VERSION ""

NS_ :

BS_:

BU_: FUSION IVI HMI Telltale

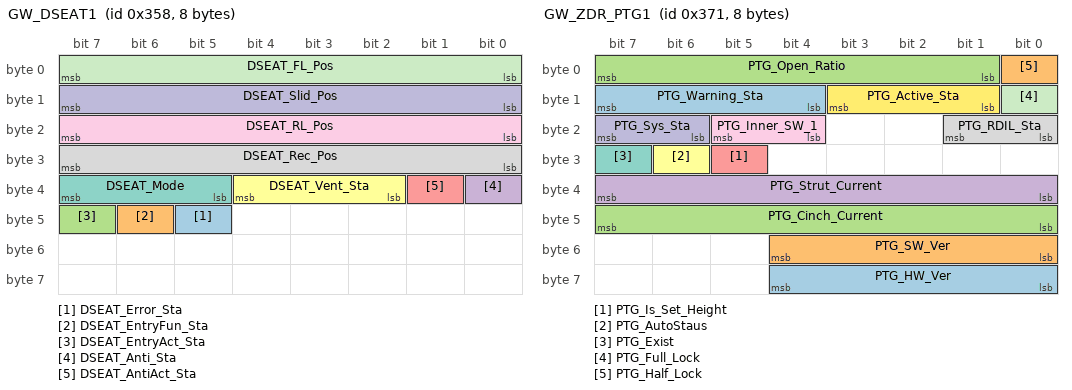
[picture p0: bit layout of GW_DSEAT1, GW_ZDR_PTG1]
BO_ 856 GW_DSEAT1: 8 FUSION
 SG_ DSEAT_Error_Sta : 45|1@0+ (1,0) [0|1] "" IVI
 SG_ DSEAT_EntryFun_Sta : 46|1@0+ (1,0) [0|1] "" IVI
 SG_ DSEAT_EntryAct_Sta : 47|1@0+ (1,0) [0|1] "" Vector__XXX
 SG_ DSEAT_Anti_Sta : 32|1@0+ (1,0) [0|1] "" IVI
 SG_ DSEAT_AntiAct_Sta : 33|1@0+ (1,0) [0|1] "" Vector__XXX
 SG_ DSEAT_Vent_Sta : 36|3@0+ (1,0) [0|4] "" IVI
 SG_ DSEAT_Mode : 39|3@0+ (1,0) [0|7] "" Vector__XXX
 SG_ DSEAT_Rec_Pos : 31|8@0+ (1,0) [0|80] "deg" Vector__XXX
 SG_ DSEAT_RL_Pos : 23|8@0+ (1,0) [0|60] "mm" Vector__XXX
 SG_ DSEAT_Slid_Pos : 15|8@0+ (1,0) [0|240] "mm" Vector__XXX
 SG_ DSEAT_FL_Pos : 7|8@0+ (1,0) [0|25] "mm" Vector__XXX

BO_ 881 GW_ZDR_PTG1: 8 FUSION
 SG_ PTG_HW_Ver : 60|5@0+ (1,0) [0|31] "" IVI
 SG_ PTG_SW_Ver : 52|5@0+ (1,0) [0|31] "" IVI
 SG_ PTG_Cinch_Current : 47|8@0+ (0.1,0) [0|25.5] "A" Vector__XXX
 SG_ PTG_Strut_Current : 39|8@0+ (0.1,0) [0|25.5] "A" Vector__XXX
 SG_ PTG_Is_Set_Height : 29|1@0+ (1,0) [0|1] "" IVI
 SG_ PTG_AutoStaus : 30|1@0+ (1,0) [0|1] "" IVI
 SG_ PTG_Exist : 31|1@0+ (1,0) [0|1] "" IVI
 SG_ PTG_RDIL_Sta : 17|2@0+ (1,0) [0|3] "" Vector__XXX
 SG_ PTG_Inner_SW_1 : 21|2@0+ (1,0) [0|3] "" Vector__XXX
 SG_ PTG_Sys_Sta : 23|2@0+ (1,0) [0|3] "" IVI
 SG_ PTG_Full_Lock : 8|1@0+ (1,0) [0|1] "" Vector__XXX
 SG_ PTG_Active_Sta : 11|3@0+ (1,0) [0|7] "" IVI
 SG_ PTG_Warning_Sta : 15|4@0+ (1,0) [0|15] "" Vector__XXX
 SG_ PTG_Half_Lock : 0|1@0+ (1,0) [0|1] "" Vector__XXX
 SG_ PTG_Open_Ratio : 7|7@0+ (1,0) [0|127] "" Vector__XXX

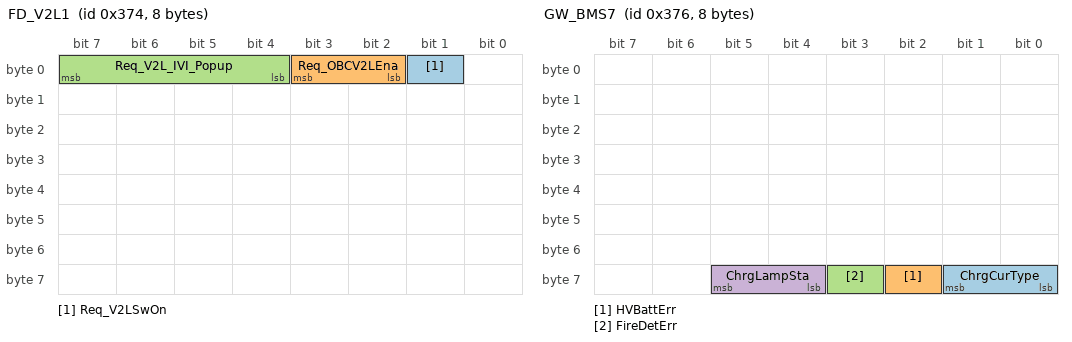
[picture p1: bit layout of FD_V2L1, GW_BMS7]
BO_ 884 FD_V2L1: 8 FUSION
 SG_ Req_V2LSwOn : 1|1@0+ (1,0) [0|1] "" IVI
 SG_ Req_OBCV2LEna : 3|2@0+ (1,0) [0|2] "" Vector__XXX
 SG_ Req_V2L_IVI_Popup : 7|4@0+ (1,0) [0|6] "" IVI

BO_ 886 GW_BMS7: 8 FUSION
 SG_ ChrgCurType : 57|2@0+ (1,0) [0|3] "" Vector__XXX
 SG_ HVBattErr : 58|1@0+ (1,0) [0|1] "" IVI,Telltale
 SG_ FireDetErr : 59|1@0+ (1,0) [0|1] "" IVI
 SG_ ChrgLampSta : 61|2@0+ (1,0) [0|3] "" Vector__XXX

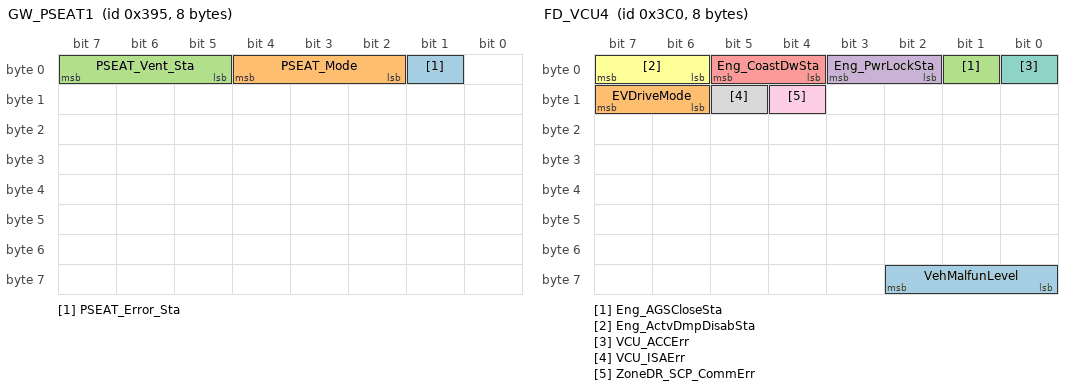
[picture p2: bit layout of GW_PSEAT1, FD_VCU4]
BO_ 917 GW_PSEAT1: 8 FUSION
 SG_ PSEAT_Error_Sta : 1|1@0+ (1,0) [0|1] "" IVI
 SG_ PSEAT_Mode : 4|3@0+ (1,0) [0|7] "" IVI
 SG_ PSEAT_Vent_Sta : 7|3@0+ (1,0) [0|4] "" IVI

BO_ 921 GW_MCU_F3: 8 FUSION
 SG_ Fr_MCU_SW_Ver : 55|16@0+ (1,0) [0|65535] "" IVI
 SG_ Fr_MCU_HW_Ver : 39|16@0+ (1,0) [0|65535] "" IVI

BO_ 925 GW_MCU_R3: 8 FUSION
 SG_ Rr_MCU3_SW_Ver : 55|16@0+ (1,0) [0|65535] "" IVI
 SG_ Rr_MCU3_HW_Ver : 39|16@0+ (1,0) [0|65535] "" IVI

BO_ 960 FD_VCU4: 8 FUSION
 SG_ VehMalfunLevel : 58|3@0+ (1,0) [0|5] "" IVI
 SG_ EVDriveMode : 15|2@0+ (1,0) [0|2] "" IVI
 SG_ Eng_AGSCloseSta : 1|1@0+ (1,0) [0|1] "" IVI
 SG_ Eng_PwrLockSta : 3|2@0+ (1,0) [0|2] "" IVI
 SG_ Eng_CoastDwSta : 5|2@0+ (1,0) [0|2] "" IVI
 SG_ Eng_ActvDmpDisabSta : 7|2@0+ (1,0) [0|2] "" IVI
 SG_ VCU_ACCErr : 0|1@0+ (1,0) [0|1] "" IVI
 SG_ VCU_ISAErr : 13|1@0+ (1,0) [0|1] "" IVI
 SG_ ZoneDR_SCP_CommErr : 12|1@0+ (1,0) [0|1] "" IVI

BO_ 963 FD_VCU6: 32 FUSION
 SG_ FUSION_SW_SHA8 : 239|8@0+ (1,0) [0|255] "" IVI
 SG_ FUSION_SW_SHA7 : 231|8@0+ (1,0) [0|255] "" IVI
 SG_ FUSION_SW_SHA6 : 223|8@0+ (1,0) [0|255] "" IVI
 SG_ FUSION_SW_SHA5 : 215|8@0+ (1,0) [0|255] "" IVI
 SG_ FUSION_SW_SHA4 : 207|8@0+ (1,0) [0|255] "" IVI
 SG_ FUSION_SW_SHA3 : 199|8@0+ (1,0) [0|255] "" IVI
 SG_ FUSION_SW_SHA2 : 191|8@0+ (1,0) [0|255] "" IVI
 SG_ FUSION_SW_SHA1 : 183|8@0+ (1,0) [0|255] "" IVI
 SG_ FUSION_SW_dash2 : 175|8@0+ (1,0) [0|255] "" IVI
 SG_ FUSION_SW_change2 : 167|8@0+ (1,0) [0|255] "" IVI
 SG_ FUSION_SW_change1 : 159|8@0+ (1,0) [0|255] "" IVI
 SG_ FUSION_SW_dash1 : 151|8@0+ (1,0) [0|255] "" IVI
 SG_ FUSION_HW_Ver1 : 143|8@0+ (1,0) [0|255] "" IVI
 SG_ FUSION_HW_Ver2 : 135|8@0+ (1,0) [0|255] "" IVI
 SG_ FUSION_HW_Ver3 : 127|8@0+ (1,0) [0|255] "" IVI
 SG_ FUSION_SW_CarModel1 : 119|8@0+ (1,0) [0|255] "" IVI
 SG_ FUSION_SW_CarModel2 : 111|8@0+ (1,0) [0|255] "" IVI
 SG_ FUSION_SW_CarModel3 : 103|8@0+ (1,0) [0|255] "" IVI
 SG_ FUSION_SW_Controller1 : 95|8@0+ (1,0) [0|255] "" IVI
 SG_ FUSION_SW_Controller2 : 87|8@0+ (1,0) [0|255] "" IVI
 SG_ FUSION_SW_Major1 : 79|8@0+ (1,0) [0|255] "" IVI
 SG_ FUSION_SW_Major2 : 71|8@0+ (1,0) [0|255] "" IVI
 SG_ FUSION_SW_Minor1 : 63|8@0+ (1,0) [0|255] "" IVI
 SG_ FUSION_SW_Minor2 : 55|8@0+ (1,0) [0|255] "" IVI
 SG_ FUSION_SW_Patch1 : 47|8@0+ (1,0) [0|255] "" IVI
 SG_ FUSION_SW_Patch2 : 39|8@0+ (1,0) [0|255] "" IVI
 SG_ FUSION_SW_Country1 : 31|8@0+ (1,0) [0|255] "" IVI
 SG_ FUSION_SW_Country2 : 23|8@0+ (1,0) [0|255] "" IVI
 SG_ FUSION_SW_Var : 15|8@0+ (1,0) [0|255] "" IVI

BO_ 965 GW_ZoneDR5: 32 FUSION
 SG_ ZONE_DR_SW_SHA8 : 239|8@0+ (1,0) [0|255] "" IVI
 SG_ ZONE_DR_SW_SHA7 : 231|8@0+ (1,0) [0|255] "" IVI
 SG_ ZONE_DR_SW_SHA6 : 223|8@0+ (1,0) [0|255] "" IVI
 SG_ ZONE_DR_SW_SHA5 : 215|8@0+ (1,0) [0|255] "" IVI
 SG_ ZONE_DR_SW_SHA4 : 207|8@0+ (1,0) [0|255] "" IVI
 SG_ ZONE_DR_SW_SHA3 : 199|8@0+ (1,0) [0|255] "" IVI
 SG_ ZONE_DR_SW_SHA2 : 191|8@0+ (1,0) [0|255] "" IVI
 SG_ ZONE_DR_SW_SHA1 : 183|8@0+ (1,0) [0|255] "" IVI
 SG_ ZONE_DR_SW_dash2 : 175|8@0+ (1,0) [0|255] "" IVI
 SG_ ZONE_DR_SW_change2 : 167|8@0+ (1,0) [0|255] "" IVI
 SG_ ZONE_DR_SW_change1 : 159|8@0+ (1,0) [0|255] "" IVI
 SG_ ZONE_DR_SW_dash1 : 151|8@0+ (1,0) [0|255] "" IVI
 SG_ ZONE_DR_HW_Ver1 : 143|8@0+ (1,0) [0|255] "" IVI
 SG_ ZONE_DR_HW_Ver2 : 135|8@0+ (1,0) [0|255] "" IVI
 SG_ ZONE_DR_HW_Ver3 : 127|8@0+ (1,0) [0|255] "" IVI
 SG_ ZONE_DR_SW_CarModel1 : 119|8@0+ (1,0) [0|255] "" IVI
 SG_ ZONE_DR_SW_CarModel2 : 111|8@0+ (1,0) [0|255] "" IVI
 SG_ ZONE_DR_SW_CarModel3 : 103|8@0+ (1,0) [0|255] "" IVI
 SG_ ZONE_DR_SW_Controller1 : 95|8@0+ (1,0) [0|255] "" IVI
 SG_ ZONE_DR_SW_Controller2 : 87|8@0+ (1,0) [0|255] "" IVI
 SG_ ZONE_DR_SW_Major1 : 79|8@0+ (1,0) [0|255] "" IVI
 SG_ ZONE_DR_SW_Major2 : 71|8@0+ (1,0) [0|255] "" IVI
 SG_ ZONE_DR_SW_Minor1 : 63|8@0+ (1,0) [0|255] "" IVI
 SG_ ZONE_DR_SW_Minor2 : 55|8@0+ (1,0) [0|255] "" IVI
 SG_ ZONE_DR_SW_Patch1 : 47|8@0+ (1,0) [0|255] "" IVI
 SG_ ZONE_DR_SW_Patch2 : 39|8@0+ (1,0) [0|255] "" IVI
 SG_ ZONE_DR_SW_Country1 : 31|8@0+ (1,0) [0|255] "" IVI
 SG_ ZONE_DR_SW_Country2 : 23|8@0+ (1,0) [0|255] "" IVI
 SG_ ZONE_DR_SW_Var : 15|8@0+ (1,0) [0|255] "" IVI

BO_ 969 GW_ZoneFR5: 32 FUSION
 SG_ ZONE_FR_SW_SHA8 : 239|8@0+ (1,0) [0|255] "" IVI
 SG_ ZONE_FR_SW_SHA7 : 231|8@0+ (1,0) [0|255] "" IVI
 SG_ ZONE_FR_SW_SHA6 : 223|8@0+ (1,0) [0|255] "" IVI
 SG_ ZONE_FR_SW_SHA5 : 215|8@0+ (1,0) [0|255] "" IVI
 SG_ ZONE_FR_SW_SHA4 : 207|8@0+ (1,0) [0|255] "" IVI
 SG_ ZONE_FR_SW_SHA3 : 199|8@0+ (1,0) [0|255] "" IVI
 SG_ ZONE_FR_SW_SHA2 : 191|8@0+ (1,0) [0|255] "" IVI
 SG_ ZONE_FR_SW_SHA1 : 183|8@0+ (1,0) [0|255] "" IVI
 SG_ ZONE_FR_SW_dash2 : 175|8@0+ (1,0) [0|255] "" IVI
 SG_ ZONE_FR_SW_change2 : 167|8@0+ (1,0) [0|255] "" IVI
 SG_ ZONE_FR_SW_change1 : 159|8@0+ (1,0) [0|255] "" IVI
 SG_ ZONE_FR_SW_dash1 : 151|8@0+ (1,0) [0|255] "" IVI
 SG_ ZONE_FR_HW_Ver1 : 143|8@0+ (1,0) [0|255] "" IVI
 SG_ ZONE_FR_HW_Ver2 : 135|8@0+ (1,0) [0|255] "" IVI
 SG_ ZONE_FR_HW_Ver3 : 127|8@0+ (1,0) [0|255] "" IVI
 SG_ ZONE_FR_SW_CarModel1 : 119|8@0+ (1,0) [0|255] "" IVI
 SG_ ZONE_FR_SW_CarModel2 : 111|8@0+ (1,0) [0|255] "" IVI
 SG_ ZONE_FR_SW_CarModel3 : 103|8@0+ (1,0) [0|255] "" IVI
 SG_ ZONE_FR_SW_Controller1 : 95|8@0+ (1,0) [0|255] "" IVI
 SG_ ZONE_FR_SW_Controller2 : 87|8@0+ (1,0) [0|255] "" IVI
 SG_ ZONE_FR_SW_Major1 : 79|8@0+ (1,0) [0|255] "" IVI
 SG_ ZONE_FR_SW_Major2 : 71|8@0+ (1,0) [0|255] "" IVI
 SG_ ZONE_FR_SW_Minor1 : 63|8@0+ (1,0) [0|255] "" IVI
 SG_ ZONE_FR_SW_Minor2 : 55|8@0+ (1,0) [0|255] "" IVI
 SG_ ZONE_FR_SW_Patch1 : 47|8@0+ (1,0) [0|255] "" IVI
 SG_ ZONE_FR_SW_Patch2 : 39|8@0+ (1,0) [0|255] "" IVI
 SG_ ZONE_FR_SW_Country1 : 31|8@0+ (1,0) [0|255] "" IVI
 SG_ ZONE_FR_SW_Country2 : 23|8@0+ (1,0) [0|255] "" IVI
 SG_ ZONE_FR_SW_Var : 15|8@0+ (1,0) [0|255] "" IVI

BO_ 992 GW_BMS4: 48 FUSION
 SG_ HVBCellVoltMax : 375|16@0+ (1,0) [0|65533] "mV" Vector__XXX
 SG_ HVBCellVoltMin : 359|16@0+ (1,0) [0|65533] "mV" Vector__XXX
 SG_ CellTempAvg : 351|8@0+ (1,-40) [-40|213] "Deg^C" Vector__XXX
 SG_ MaxCellVolt_Num : 343|8@0+ (1,0) [0|253] "" Vector__XXX
 SG_ MinCellVolt_Num : 335|8@0+ (1,0) [0|253] "" Vector__XXX
 SG_ MaxCellTemp_Num : 327|8@0+ (1,0) [0|253] "" Vector__XXX
 SG_ MinCellTemp_Num : 319|8@0+ (1,0) [0|253] "" Vector__XXX
 SG_ HVBMTempMax : 311|8@0+ (1,-40) [-40|213] "Deg^C" IVI
 SG_ HVBMTempMin : 303|8@0+ (1,-40) [-40|213] "Deg^C" Vector__XXX
 SG_ Mtemp16 : 159|8@0+ (1,-40) [-40|213] "Deg^C" Vector__XXX
 SG_ Mtemp17 : 151|8@0+ (1,-40) [-40|213] "Deg^C" Vector__XXX
 SG_ Mtemp18 : 143|8@0+ (1,-40) [-40|213] "Deg^C" Vector__XXX
 SG_ Mtemp19 : 135|8@0+ (1,-40) [-40|213] "Deg^C" Vector__XXX
 SG_ Mtemp20 : 127|8@0+ (1,-40) [-40|213] "Deg^C" Vector__XXX
 SG_ Mtemp01 : 119|8@0+ (1,-40) [-40|213] "Deg^C" Vector__XXX
 SG_ Mtemp02 : 111|8@0+ (1,-40) [-40|213] "Deg^C" Vector__XXX
 SG_ Mtemp03 : 103|8@0+ (1,-40) [-40|213] "Deg^C" Vector__XXX
 SG_ Mtemp04 : 95|8@0+ (1,-40) [-40|213] "Deg^C" Vector__XXX
 SG_ Mtemp05 : 87|8@0+ (1,-40) [-40|213] "Deg^C" Vector__XXX
 SG_ Mtemp06 : 79|8@0+ (1,-40) [-40|213] "Deg^C" Vector__XXX
 SG_ Mtemp07 : 71|8@0+ (1,-40) [-40|213] "Deg^C" Vector__XXX
 SG_ Mtemp08 : 63|8@0+ (1,-40) [-40|213] "Deg^C" Vector__XXX
 SG_ Mtemp09 : 55|8@0+ (1,-40) [-40|213] "Deg^C" Vector__XXX
 SG_ Mtemp10 : 47|8@0+ (1,-40) [-40|213] "Deg^C" Vector__XXX
 SG_ Mtemp11 : 39|8@0+ (1,-40) [-40|213] "Deg^C" Vector__XXX
 SG_ Mtemp12 : 31|8@0+ (1,-40) [-40|213] "Deg^C" Vector__XXX
 SG_ Mtemp13 : 23|8@0+ (1,-40) [-40|213] "Deg^C" Vector__XXX
 SG_ Mtemp14 : 15|8@0+ (1,-40) [-40|213] "Deg^C" Vector__XXX
 SG_ Mtemp15 : 7|8@0+ (1,-40) [-40|213] "Deg^C" Vector__XXX

BO_ 997 GW_PSEAT3: 8 FUSION
 SG_ PSEAT_HW_Ver : 23|16@0+ (1,0) [0|65535] "" IVI
 SG_ PSEAT_SW_Ver : 7|16@0+ (1,0) [0|65535] "" IVI

BO_ 1016 GW_DSEAT3: 8 FUSION
 SG_ DSEAT_HW_Ver : 23|16@0+ (1,0) [0|65535] "" IVI
 SG_ DSEAT_SW_Ver : 7|16@0+ (1,0) [0|65535] "" IVI

BO_ 1077 FD_TPMS1: 20 FUSION
 SG_ LRWheelPSW : 159|8@0+ (1,0) [0|200] "" IVI
 SG_ LFWheelPSW : 151|8@0+ (1,0) [0|200] "" IVI
 SG_ RFWheelPSW : 143|8@0+ (1,0) [0|200] "" IVI
 SG_ RRWheelPSW : 135|8@0+ (1,0) [0|200] "" IVI
 SG_ RFPressIndi : 121|2@0+ (1,0) [0|3] "" IVI
 SG_ LFPressIndi : 123|2@0+ (1,0) [0|3] "" IVI
 SG_ RRPressIndi : 125|2@0+ (1,0) [0|3] "" IVI
 SG_ LRPressIndi : 127|2@0+ (1,0) [0|3] "" IVI
 SG_ RFWheelTmpIndi : 112|1@0+ (1,0) [0|1] "" IVI
 SG_ LFWheelTmpIndi : 113|1@0+ (1,0) [0|1] "" IVI
 SG_ RRWheelTmpIndi : 114|1@0+ (1,0) [0|1] "" IVI
 SG_ LRWheelTmpIndi : 115|1@0+ (1,0) [0|1] "" IVI
 SG_ RFSensorFail : 116|1@0+ (1,0) [0|1] "" IVI
 SG_ LFSensorFail : 117|1@0+ (1,0) [0|1] "" IVI
 SG_ RRSensorFail : 118|1@0+ (1,0) [0|1] "" IVI
 SG_ LRSensorFail : 119|1@0+ (1,0) [0|1] "" IVI
 SG_ RFBatWarn : 104|1@0+ (1,0) [0|1] "" IVI
 SG_ LFBatWarn : 105|1@0+ (1,0) [0|1] "" IVI
 SG_ RRBatWarn : 106|1@0+ (1,0) [0|1] "" IVI
 SG_ LRBatWarn : 107|1@0+ (1,0) [0|1] "" IVI
 SG_ RFWheelDebug : 108|1@0+ (1,0) [0|1] "" IVI
 SG_ LFWheelDebug : 109|1@0+ (1,0) [0|1] "" IVI
 SG_ RRWheelDebug : 110|1@0+ (1,0) [0|1] "" IVI
 SG_ LRWheelDebug : 111|1@0+ (1,0) [0|1] "" IVI
 SG_ RFWheelPress : 103|8@0+ (1,0) [0|250] "" IVI
 SG_ LFWheelPress : 95|8@0+ (1,0) [0|250] "" IVI
 SG_ RRWheelPress : 87|8@0+ (1,0) [0|250] "" IVI
 SG_ LRWheelPress : 79|8@0+ (1,0) [0|250] "" IVI
 SG_ RFWheelTemp : 71|8@0+ (1,-40) [-40|215] "Deg^C" IVI
 SG_ LFWheelTemp : 63|8@0+ (1,-40) [-40|215] "Deg^C" IVI
 SG_ RRWheelTemp : 55|8@0+ (1,-40) [-40|215] "Deg^C" IVI
 SG_ LRWheelTemp : 47|8@0+ (1,-40) [-40|215] "Deg^C" IVI
 SG_ AutoLTips : 25|2@0+ (1,0) [0|3] "" IVI
 SG_ CWheelTips : 34|2@0+ (1,0) [0|3] "" IVI
 SG_ TPMS_Cali_Butt_Allow : 35|1@0+ (1,0) [0|1] "" IVI
 SG_ TPMS_Res_Butt_Allow : 37|1@0+ (1,0) [0|1] "" IVI
 SG_ TPMSWarnIndi : 39|2@0+ (1,0) [0|3] "" IVI
 SG_ RRSensorMode : 12|1@0+ (1,0) [0|1] "" Vector__XXX
 SG_ LRSensorMode : 13|1@0+ (1,0) [0|1] "" Vector__XXX
 SG_ RFSensorMode : 14|1@0+ (1,0) [0|1] "" Vector__XXX
 SG_ LFSensorMode : 15|1@0+ (1,0) [0|1] "" Vector__XXX

BO_ 1078 FD_TPMS2: 32 FUSION
 SG_ ID1_ALTU : 215|32@0+ (1,0) [0|4.294967296E9] "-" Vector__XXX
 SG_ ID2_ALTU : 183|32@0+ (1,0) [0|4.294967296E9] "-" Vector__XXX
 SG_ ID3_ALTU : 151|32@0+ (1,0) [0|4.294967296E9] "-" Vector__XXX
 SG_ ID4_ALTU : 119|32@0+ (1,0) [0|4.294967296E9] "-" Vector__XXX
 SG_ IDin_ALTU : 87|32@0+ (1,0) [0|4.294967296E9] "-" Vector__XXX
 SG_ ID1_Loc_ALTU : 74|3@0+ (1,0) [0|5] "-" Vector__XXX
 SG_ ID2_Loc_ALTU : 77|3@0+ (1,0) [0|5] "-" Vector__XXX
 SG_ ID3_Loc_ALTU : 66|3@0+ (1,0) [0|5] "-" Vector__XXX
 SG_ ID4_Loc_ALTU : 69|3@0+ (1,0) [0|5] "-" Vector__XXX
 SG_ RF_FAT_ALTU : 70|1@0+ (1,0) [0|1] "-" Vector__XXX
 SG_ ID1_message_ALTU : 63|8@0+ (1,0) [0|255] "-" Vector__XXX
 SG_ ID2_message_ALTU : 55|8@0+ (1,0) [0|255] "-" Vector__XXX
 SG_ ID3_message_ALTU : 47|8@0+ (1,0) [0|255] "-" Vector__XXX
 SG_ ID4_message_ALTU : 39|8@0+ (1,0) [0|255] "-" Vector__XXX
 SG_ S1WheelDebug_ALTU : 31|8@0+ (0.5,0) [0|100] "%" Vector__XXX
 SG_ S2WheelDebug_ALTU : 23|8@0+ (0.5,0) [0|100] "%" Vector__XXX
 SG_ S3WheelDebug_ALTU : 15|8@0+ (0.5,0) [0|100] "%" Vector__XXX
 SG_ S4WheelDebug_ALTU : 7|8@0+ (0.5,0) [0|100] "%" Vector__XXX

BO_ 1080 FD_OTA1: 12 FUSION
 SG_ OTA_Up_Backcount : 55|8@0+ (1,0) [0|122] "" IVI
 SG_ OTA_DL_Speed : 27|20@0+ (1,0) [0|1048575] "Kb/s" IVI
 SG_ OTA_Lock_Req : 31|1@0+ (1,0) [0|1] "" Vector__XXX
 SG_ OTA_Updating_ECU : 20|5@0+ (1,0) [0|30] "" Vector__XXX
 SG_ OTA_Update_Available : 21|1@0+ (1,0) [0|1] "" IVI
 SG_ OTA_InVehicle_FW : 23|2@0+ (1,0) [0|2] "" IVI
 SG_ OTA_DL_Available : 8|1@0+ (1,0) [0|1] "" IVI
 SG_ OTA_Mode : 9|1@0+ (1,0) [0|1] "" IVI
 SG_ OTA_Network_Type : 11|2@0+ (1,0) [0|3] "" IVI
 SG_ OTA_MDA_Status : 15|4@0+ (1,0) [0|14] "" IVI
 SG_ OTA_Progress_Rate : 7|8@0+ (1,0) [0|102] "" IVI
 SG_ OTA_Permit_Agreed : 63|1@0+ (1,0) [0|1] "" IVI
 SG_ OTA_Remained_Time : 58|11@0+ (10,0) [0|10800] "SECOND" IVI
 SG_ OTA_Debug_Code : 79|8@0+ (1,0) [0|65] "" IVI
 SG_ OTA_TBOXResetReq : 30|1@0+ (1,0) [0|1] "" Vector__XXX
 SG_ OTA_Updating_ECU_8bit : 95|8@0+ (1,0) [0|255] "" IVI

BO_ 1090 GW_TBOX1: 12 FUSION
 SG_ PowerOff_T_Set : 70|7@0+ (1,1) [1|100] "" Vector__XXX
 SG_ Re_Radio : 60|1@0+ (1,0) [0|1] "" IVI
 SG_ TBOX_NET_SIG_STR : 55|4@0+ (1,0) [0|8] "" IVI
 SG_ TBOX_TEST_STATUS : 51|4@0+ (1,0) [0|15] "" IVI
 SG_ ReOutsideMirror : 43|2@0+ (1,0) [0|3] "" Vector__XXX
 SG_ CbnPreReq : 45|2@0+ (1,0) [0|3] "" Vector__XXX
 SG_ CbnPreACEnaReq : 47|2@0+ (1,0) [0|3] "" IVI
 SG_ CbnPreTarT : 37|6@0+ (0.5,17) [17|32] "" Vector__XXX
 SG_ Uncounting_Req : 39|2@0+ (1,0) [0|3] "" Vector__XXX
 SG_ TBOX_Remote_PW : 28|5@0+ (1,0) [0|16] "" Vector__XXX
 SG_ Re_PwrReqTbox : 31|3@0+ (1,0) [0|6] "" Vector__XXX
 SG_ TBOX_RemoteOn : 17|2@0+ (1,0) [0|3] "" Vector__XXX
 SG_ TBOX_Re_VehData : 19|2@0+ (1,0) [0|3] "" Vector__XXX
 SG_ Antitheft_Zero : 23|4@0+ (1,0) [0|15] "" Vector__XXX
 SG_ Re_DoorLock : 7|16@0+ (1,0) [0|65535] "" Vector__XXX
 SG_ TBOX_Re_DTCData : 41|2@0+ (1,0) [0|3] "" Vector__XXX
 SG_ Remote_ACTemp : 77|6@0+ (0.5,17) [17|32] "Deg^C" Vector__XXX
 SG_ Remote_AutoReq : 79|1@0+ (1,0) [0|1] "" Vector__XXX
 SG_ Remote_MidAutoReq : 78|1@0+ (1,0) [0|1] "" Vector__XXX

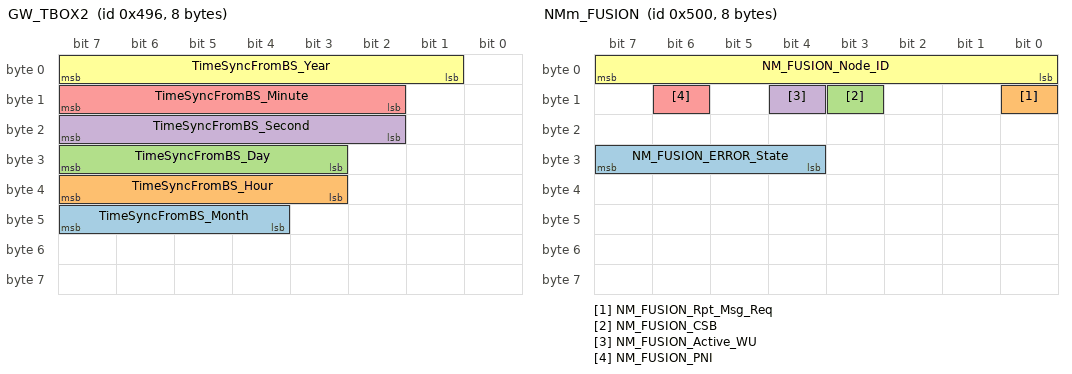
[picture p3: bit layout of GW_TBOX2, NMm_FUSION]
BO_ 1174 GW_TBOX2: 8 FUSION
 SG_ TimeSyncFromBS_Month : 47|4@0+ (1,0) [0|12] "MONTH" IVI
 SG_ TimeSyncFromBS_Hour : 39|5@0+ (1,0) [0|23] "HOUR" IVI
 SG_ TimeSyncFromBS_Day : 31|5@0+ (1,0) [0|31] "DAY" IVI
 SG_ TimeSyncFromBS_Second : 23|6@0+ (1,0) [0|59] "SECOND" IVI
 SG_ TimeSyncFromBS_Minute : 15|6@0+ (1,0) [0|59] "MINUTE" IVI
 SG_ TimeSyncFromBS_Year : 7|7@0+ (1,2000) [2000|2099] "YEAR" IVI

BO_ 1249 GW_TBOX3: 48 FUSION
 SG_ TBOX_SW_VER : 279|32@0+ (1,0) [0|4.294967295E9] "" IVI
 SG_ TBOX_HW_VER : 231|32@0+ (1,0) [0|4.294967295E9] "" IVI
 SG_ ReserveChargeOn_Minute : 221|6@0+ (1,0) [0|59] "MINUTE" Vector__XXX
 SG_ ReserveChargeOn_Hour : 210|5@0+ (1,0) [0|23] "HOUR" Vector__XXX
 SG_ ReserveChargeOn_Day : 215|5@0+ (1,0) [0|31] "DAY" Vector__XXX
 SG_ ReserveChargeOn_Month : 203|4@0+ (1,0) [0|12] "MONTH" Vector__XXX
 SG_ ReserveChargeOn_Year : 194|7@0+ (1,2000) [2000|2099] "YEAR" Vector__XXX
 SG_ ReserveChargeOFF_Minute : 189|6@0+ (1,0) [0|59] "MINUTE" Vector__XXX
 SG_ ReserveChargeOFF_Hour : 178|5@0+ (1,0) [0|23] "HOUR" Vector__XXX
 SG_ ReserveChargeOFF_Day : 183|5@0+ (1,0) [0|31] "DAY" Vector__XXX
 SG_ ReserveChargeOFF_Month : 171|4@0+ (1,0) [0|12] "MONTH" Vector__XXX
 SG_ ReserveChargeOFF_Year : 162|7@0+ (1,2000) [2000|2099] "YEAR" Vector__XXX
 SG_ Charge_Percent_Set : 159|8@0+ (1,0) [0|100] "%" IVI

BO_ 1280 NMm_FUSION: 8 FUSION
 SG_ NM_FUSION_ERROR_State : 31|4@0+ (1,0) [0|8] "" IVI,HMI,Telltale
 SG_ NM_FUSION_Rpt_Msg_Req : 8|1@0+ (1,0) [0|1] "" IVI,HMI,Telltale
 SG_ NM_FUSION_CSB : 11|1@0+ (1,0) [0|1] "" IVI,HMI,Telltale
 SG_ NM_FUSION_Active_WU : 12|1@0+ (1,0) [0|1] "" IVI,HMI,Telltale
 SG_ NM_FUSION_PNI : 14|1@0+ (1,0) [0|1] "" IVI,HMI,Telltale
 SG_ NM_FUSION_Node_ID : 7|8@0+ (1,0) [0|127] "" IVI,HMI,Telltale

BO_ 1666 DiagPhysReqToTelltale: 8 FUSION
 SG_ DiagPhysReqToTelltale : 7|64@0+ (1,0) [0|0] "" Telltale

BO_ 1696 DiagPhysReqToIVI: 8 FUSION
 SG_ DiagPhysReqToIVI : 7|64@0+ (1,0) [0|0] "" IVI

BO_ 1714 DiagPhysReqToHMI: 8 FUSION
 SG_ DiagPhysReqToHMI : 7|64@0+ (1,0) [0|0] "" HMI

BO_ 2000 DiagFuncReqFT: 8 FUSION
 SG_ DiagFuncReqFT : 7|64@0+ (1,0) [0|0] "" IVI,HMI,Telltale

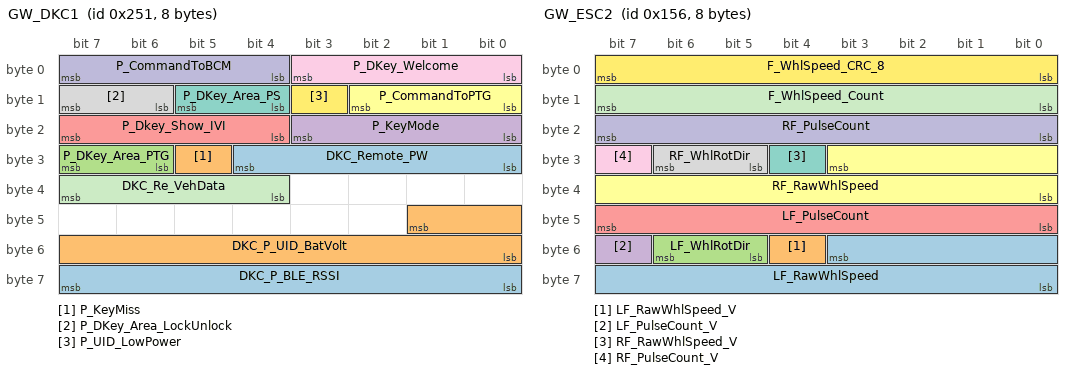
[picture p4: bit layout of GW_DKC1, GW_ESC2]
BO_ 593 GW_DKC1: 8 FUSION
 SG_ DKC_Remote_PW : 28|5@0+ (1,0) [0|16] "" Vector__XXX
 SG_ P_KeyMiss : 29|1@0+ (1,0) [0|1] "" IVI
 SG_ P_DKey_Area_PTG : 31|2@0+ (1,0) [0|3] "" Vector__XXX
 SG_ P_KeyMode : 19|4@0+ (1,0) [0|15] "" Vector__XXX
 SG_ P_Dkey_Show_IVI : 23|4@0+ (1,0) [0|15] "" IVI
 SG_ P_CommandToPTG : 10|3@0+ (1,0) [0|5] "" Vector__XXX
 SG_ P_DKey_Area_PS : 13|2@0+ (1,0) [0|3] "" Vector__XXX
 SG_ P_DKey_Area_LockUnlock : 15|2@0+ (1,0) [0|3] "" Vector__XXX
 SG_ P_DKey_Welcome : 3|4@0+ (1,0) [0|15] "" Vector__XXX
 SG_ P_CommandToBCM : 7|4@0+ (1,0) [0|15] "" Vector__XXX
 SG_ DKC_Re_VehData : 39|4@0+ (1,0) [0|15] "" Vector__XXX
 SG_ P_UID_LowPower : 11|1@0+ (1,0) [0|1] "" IVI
 SG_ DKC_P_BLE_RSSI : 63|8@0+ (1,0) [0|255] "" Vector__XXX
 SG_ DKC_P_UID_BatVolt : 41|10@0+ (10,0) [0|3500] "mV" Vector__XXX

BO_ 342 GW_ESC2: 8 FUSION
 SG_ LF_RawWhlSpeed : 51|12@0+ (0.0625,0) [0|255.9375] "km/h" Vector__XXX
 SG_ LF_RawWhlSpeed_V : 52|1@0+ (1,0) [0|1] "" Vector__XXX
 SG_ LF_WhlRotDir : 54|2@0+ (1,0) [0|3] "" IVI
 SG_ LF_PulseCount_V : 55|1@0+ (1,0) [0|1] "" IVI
 SG_ LF_PulseCount : 47|8@0+ (1,0) [0|255] "" IVI
 SG_ RF_RawWhlSpeed : 27|12@0+ (0.0625,0) [0|255.9375] "km/h" Vector__XXX
 SG_ RF_RawWhlSpeed_V : 28|1@0+ (1,0) [0|1] "" Vector__XXX
 SG_ RF_WhlRotDir : 30|2@0+ (1,0) [0|3] "" IVI
 SG_ RF_PulseCount_V : 31|1@0+ (1,0) [0|1] "" IVI
 SG_ RF_PulseCount : 23|8@0+ (1,0) [0|255] "" IVI
 SG_ F_WhlSpeed_Count : 15|8@0+ (1,0) [0|255] "" IVI
 SG_ F_WhlSpeed_CRC_8 : 7|8@0+ (1,0) [0|255] "" IVI

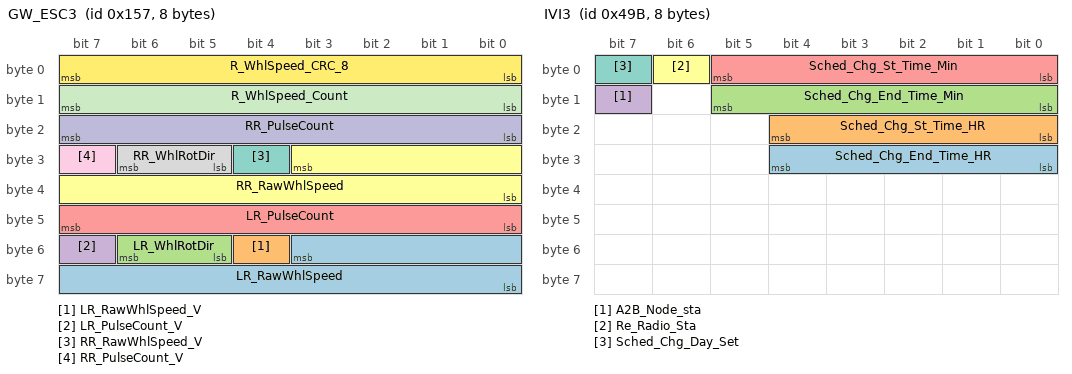
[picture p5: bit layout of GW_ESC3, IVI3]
BO_ 343 GW_ESC3: 8 FUSION
 SG_ LR_RawWhlSpeed : 51|12@0+ (0.0625,0) [0|255.9375] "km/h" Vector__XXX
 SG_ LR_RawWhlSpeed_V : 52|1@0+ (1,0) [0|1] "" Vector__XXX
 SG_ LR_WhlRotDir : 54|2@0+ (1,0) [0|3] "" IVI
 SG_ LR_PulseCount_V : 55|1@0+ (1,0) [0|1] "" IVI
 SG_ LR_PulseCount : 47|8@0+ (1,0) [0|255] "" IVI
 SG_ RR_RawWhlSpeed : 27|12@0+ (0.0625,0) [0|255.9375] "km/h" Vector__XXX
 SG_ RR_RawWhlSpeed_V : 28|1@0+ (1,0) [0|1] "" Vector__XXX
 SG_ RR_WhlRotDir : 30|2@0+ (1,0) [0|3] "" IVI
 SG_ RR_PulseCount_V : 31|1@0+ (1,0) [0|1] "" IVI
 SG_ RR_PulseCount : 23|8@0+ (1,0) [0|255] "" IVI
 SG_ R_WhlSpeed_Count : 15|8@0+ (1,0) [0|255] "" IVI
 SG_ R_WhlSpeed_CRC_8 : 7|8@0+ (1,0) [0|255] "" IVI

BO_ 602 METER1: 24 IVI
 SG_ ODOMETER : 175|24@0+ (0.1,0) [0|999999.9] "KM" FUSION
 SG_ Trip_A : 151|24@0+ (0.1,0) [0|99999.9] "KM" FUSION
 SG_ Trip_B : 127|24@0+ (0.1,0) [0|99999.9] "KM" FUSION
 SG_ ParkBrake : 112|1@0+ (1,0) [0|1] "" FUSION
 SG_ Charge : 113|1@0+ (1,0) [0|1] "" FUSION
 SG_ LEDlitWarnReq : 114|1@0+ (1,0) [0|1] "" FUSION
 SG_ Spd_Crl_Sta : 115|1@0+ (1,0) [0|1] "" FUSION
 SG_ Spd_Crl_Mode : 118|3@0+ (1,0) [0|7] "" FUSION
 SG_ AvailableTrip : 103|16@0+ (0.1,0) [0|999.9] "KM" FUSION
 SG_ APCforDTE : 87|16@0+ (0.1,-999.9) [-999.9|999.9] "Wh/km" FUSION
 SG_ AVGPwrConsumption : 71|16@0+ (0.1,-999.9) [-999.9|999.9] "Wh/km" FUSION
 SG_ Averaged_vehspeed : 49|10@0+ (1,0) [0|300] "km/h" FUSION
 SG_ METER_MPH_Real : 35|12@0+ (0.077675,0) [0|160.0105] "mph" FUSION
 SG_ METER_KPH_Real : 31|12@0+ (0.125,0) [0|255.875] "km/h" FUSION
 SG_ METER_MPH_Calcu : 23|8@0+ (1,0) [0|160] "mph" FUSION
 SG_ METER_KPH_Calcu : 15|8@0+ (1,0) [0|254] "km/h" FUSION

BO_ 1168 IVI1: 8 IVI
 SG_ DRAmbLightBrightnessSet : 46|7@0+ (1,0) [0|100] "%" FUSION
 SG_ AmbLightUserSet : 34|3@0+ (1,0) [0|6] "" FUSION
 SG_ IPAmbLightBrightnessSet : 30|7@0+ (1,0) [0|100] "%" FUSION
 SG_ Sched_OTA_wake : 31|1@0+ (1,0) [0|1] "" FUSION
 SG_ AmbLightColorSet : 21|6@0+ (1,0) [0|63] "" FUSION
 SG_ Upd_Countdown_Cancel : 22|1@0+ (1,0) [0|1] "" FUSION
 SG_ Upd_Countdown_Skip : 23|1@0+ (1,0) [0|1] "" FUSION
 SG_ LINKtoDrive : 8|1@0+ (1,0) [0|1] "" FUSION
 SG_ OTA_CompNTFY_Pres : 9|1@0+ (1,0) [0|1] "" FUSION
 SG_ OTA_CancelDL_Req : 10|1@0+ (1,0) [0|1] "" FUSION
 SG_ IVI_OTA_Upd_Sta : 12|2@0+ (1,0) [0|3] "" FUSION
 SG_ OTA_UpdStart_Req : 13|1@0+ (1,0) [0|1] "" FUSION
 SG_ OTA_SuspendDL_Req : 14|1@0+ (1,0) [0|1] "" FUSION
 SG_ OTA_DL_Req : 15|1@0+ (1,0) [0|1] "" FUSION
 SG_ FCP_FrEvt_BtnSyncReq : 0|1@0+ (1,0) [0|1] "" FUSION
 SG_ FCP_MidEvt_BtnAutoReq : 1|1@0+ (1,0) [0|1] "" FUSION
 SG_ FCP_FrEvt_BtnAutoReq : 2|1@0+ (1,0) [0|1] "" FUSION
 SG_ FCP_FrEvt_BtnACReq : 3|1@0+ (1,0) [0|1] "" FUSION
 SG_ FCP_FrEvt_BtnACMaxReq : 4|1@0+ (1,0) [0|1] "" FUSION
 SG_ VehACModReq : 7|3@0+ (1,0) [0|7] "" FUSION
 SG_ PW_CONTINUE_USE : 39|1@0+ (1,0) [0|1] "" FUSION
 SG_ PW_CLOSE_IMD : 38|1@0+ (1,0) [0|1] "" FUSION
 SG_ SmartEco_Mode_SW : 47|1@0+ (1,0) [0|1] "" FUSION
 SG_ BrkAbn_GoReady_SW : 37|1@0+ (1,0) [0|1] "" FUSION
 SG_ OpenDrOpenWdo_SW : 36|1@0+ (1,0) [0|1] "" FUSION
 SG_ IVI_Lock_SoundSW_Sta : 35|1@0+ (1,0) [0|1] "" FUSION

BO_ 1173 IVI2: 64 IVI
 SG_ AVM_parking_cancel : 505|2@0+ (1,0) [0|3] "" FUSION
 SG_ AVM_parking_excute : 507|2@0+ (1,0) [0|3] "" FUSION
 SG_ AVM_OFF_Rec_Butt : 508|1@0+ (1,0) [0|1] "" FUSION
 SG_ IVI_AGSCloseSW : 511|2@0+ (1,0) [0|3] "" FUSION
 SG_ IVI_LVChrgFuncSW : 497|2@0+ (1,0) [0|3] "" FUSION
 SG_ IVI_PwrLockSW : 499|2@0+ (1,0) [0|3] "" FUSION
 SG_ IVI_CoastDwSW : 501|2@0+ (1,0) [0|3] "" FUSION
 SG_ IVI_ActvDmpDisabSW : 503|2@0+ (1,0) [0|3] "" FUSION
 SG_ Roll_Mode_SW_Cmd : 473|2@0+ (1,0) [0|3] "" FUSION
 SG_ TCS_SW_Cmd : 475|2@0+ (1,0) [0|3] "" FUSION
 SG_ SLIF_BUTT : 477|2@0+ (1,0) [0|2] "" FUSION
 SG_ Roll_Eng_Mode : 478|1@0+ (1,0) [0|1] "" FUSION
 SG_ SOC_Limit_Set : 468|5@0+ (2,50) [50|100] "%" FUSION
 SG_ CDL_Lock_Butt : 469|1@0+ (1,0) [0|1] "" FUSION
 SG_ CDL_Unlock_Butt : 470|1@0+ (1,0) [0|1] "" FUSION
 SG_ SOC_ADJ_BUTT : 471|1@0+ (1,0) [0|1] "" FUSION
 SG_ AC_Chg_Cur_Set : 462|7@0+ (1,5) [5|132] "A" FUSION
 SG_ IVI_ISA_OffsetSpd : 451|4@0+ (1,0) [0|14] "" FUSION
 SG_ RoomLampMode : 455|1@0+ (1,0) [0|1] "" FUSION
 SG_ NAVI_SpeedLimit : 444|5@0+ (1,0) [0|31] "km/h" FUSION
 SG_ NAVI_RoadClass : 447|3@0+ (1,0) [0|7] "" FUSION
 SG_ NAVI_Tollgate : 427|12@0+ (1,0) [0|2000] "m" FUSION
 SG_ NAVI_LinkClass : 431|4@0+ (1,0) [0|15] "" FUSION
 SG_ NAVI_Tunnel : 411|12@0+ (1,0) [0|2000] "m" FUSION
 SG_ NAVI_ForwardLinkLevel : 415|4@0+ (1,0) [0|15] "" FUSION
 SG_ SenstivityPosition : 403|4@0+ (1,0) [0|15] "" FUSION
 SG_ AVM_Parking_mode : 407|4@0+ (1,0) [0|15] "" FUSION
 SG_ Hood_Latch_SW : 393|2@0+ (1,0) [0|3] "" FUSION
 SG_ RCTA_BUTT : 396|2@0+ (1,0) [0|3] "" FUSION
 SG_ IVI_Pwroff_req : 397|1@0+ (1,0) [0|1] "" FUSION
 SG_ IVI_Trigger_req : 398|1@0+ (1,0) [0|1] "" FUSION
 SG_ AVM_Err_STA : 399|1@0+ (1,0) [0|1] "" FUSION
 SG_ NAVI_Distance_info : 375|24@0+ (1,0) [0|1.6777215E7] "m" FUSION
 SG_ IVI_Mute_Sta : 360|1@0+ (1,0) [0|1] "" FUSION
 SG_ IVI_PTG_USSta_SW : 361|1@0+ (1,0) [0|1] "" FUSION
 SG_ IVI_WI_MAIN_SW : 362|1@0+ (1,0) [0|1] "" FUSION
 SG_ IVI_RR_Def_Req : 363|1@0+ (1,0) [0|1] "" FUSION
 SG_ IVI_Night_Mode_Sta : 364|1@0+ (1,0) [0|1] "" FUSION
 SG_ IVI_Status : 365|1@0+ (1,0) [0|1] "" FUSION
 SG_ LVDAMute_BUTT : 367|2@0+ (1,0) [0|3] "" FUSION
 SG_ CAAS_Sw : 353|2@0+ (1,0) [0|3] "" FUSION
 SG_ DSEAT_entryfun_set : 354|1@0+ (1,0) [0|1] "" FUSION
 SG_ DSEAT_anti_set : 355|1@0+ (1,0) [0|1] "" FUSION
 SG_ TPMS_Res_Butt : 357|1@0+ (1,0) [0|1] "" FUSION
 SG_ FollowMeSW : 358|1@0+ (1,0) [0|1] "" FUSION
 SG_ SetUnlockSingle : 359|1@0+ (1,0) [0|1] "" FUSION
 SG_ IVI_PTG_Mode_SW : 345|2@0+ (1,0) [0|3] "" FUSION
 SG_ IVI_PTG_Sta_SW : 347|2@0+ (1,0) [0|3] "" FUSION
 SG_ SLG_Sw : 349|2@0+ (1,0) [0|3] "" FUSION
 SG_ FS_Off_Sw : 351|2@0+ (1,0) [0|3] "" FUSION
 SG_ PSEAT_vent_req : 338|3@0+ (1,0) [0|7] "" FUSION
 SG_ FFogLampSW : 339|1@0+ (1,0) [0|1] "" FUSION
 SG_ DSEAT_vent_req : 342|3@0+ (1,0) [0|7] "" FUSION
 SG_ RFogLampSW : 343|1@0+ (1,0) [0|1] "" FUSION
 SG_ MFRD_N_Bright_Req : 334|7@0+ (1,0) [0|100] "%" FUSION
 SG_ User_p_download : 335|1@0+ (1,0) [0|1] "" FUSION
 SG_ HeadLampSW : 321|2@0+ (1,0) [0|3] "" FUSION
 SG_ NAVI_State : 323|2@0+ (1,0) [0|3] "" FUSION
 SG_ Wifi_Sta_IVI_TBOX : 327|4@0+ (1,0) [0|15] "" FUSION
 SG_ IVI_Panel_Y_Coor : 307|12@0+ (1,0) [0|4095] "" FUSION
 SG_ IVI_Panel_X_Coor : 303|12@0+ (1,0) [0|4095] "" FUSION
 SG_ NAVI_Cam_Dist_info : 295|8@0+ (1,0) [0|255] "m" FUSION
 SG_ OFF_AC_MODE : 282|3@0+ (1,0) [0|7] "" FUSION
 SG_ IVI_PW_Mode_Req : 284|2@0+ (1,0) [0|3] "" FUSION
 SG_ User_p_upload : 285|1@0+ (1,0) [0|1] "" FUSION
 SG_ CameraWrn : 286|1@0+ (1,0) [0|1] "" FUSION
 SG_ Wifi_Reset : 287|1@0+ (1,0) [0|1] "" FUSION
 SG_ NAVI_Direction_STA : 279|8@0+ (1,0) [0|255] "" FUSION
 SG_ IVI_Screen : 269|6@0+ (1,0) [0|62] "" FUSION
 SG_ TurnSwTimeSet : 271|2@0+ (1,0) [0|3] "" FUSION
 SG_ Pressure_unit : 263|8@0+ (1,0) [0|255] "" FUSION
 SG_ Time_system : 255|8@0+ (1,0) [0|255] "" FUSION
 SG_ NAVI_Speed_Limit_A : 241|2@0+ (1,0) [0|3] "" FUSION
 SG_ Temperature_unit : 242|1@0+ (1,0) [0|1] "" FUSION
 SG_ Distance_unit : 243|1@0+ (1,0) [0|1] "" FUSION
 SG_ ESC_SW_Cmd : 245|2@0+ (1,0) [0|3] "" FUSION
 SG_ IVI_Panel_Act : 246|1@0+ (1,0) [0|1] "" FUSION
 SG_ sigHvacRearReq : 247|1@0+ (1,0) [0|1] "" FUSION
 SG_ FCWMute_BUTT : 233|2@0+ (1,0) [0|3] "" FUSION
 SG_ LKA_BUTT : 235|2@0+ (1,0) [0|3] "" FUSION
 SG_ ODAMute_BUTT : 237|2@0+ (1,0) [0|3] "" FUSION
 SG_ LDWMute_BUTT : 239|2@0+ (1,0) [0|3] "" FUSION
 SG_ BSDMute_BUTT : 225|2@0+ (1,0) [0|3] "" FUSION
 SG_ sigWindDirZon3Req : 228|3@0+ (1,0) [0|7] "" FUSION
 SG_ sigAirIntenZon3Req : 219|4@0+ (1,0) [0|15] "" FUSION
 SG_ sigAirIntenZon1Req : 223|4@0+ (1,0) [0|15] "" FUSION
 SG_ AEB_BUTT : 209|2@0+ (1,0) [0|3] "" FUSION
 SG_ sigSetTempZon3Req : 215|6@0+ (0.5,17) [17|32] "Deg^C" FUSION
 SG_ sigSetTempZon2Req : 205|6@0+ (0.5,17) [17|32] "Deg^C" FUSION
 SG_ sigRecircReq : 206|1@0+ (1,0) [0|1] "" FUSION
 SG_ sigHvacReq : 207|1@0+ (1,0) [0|1] "" FUSION
 SG_ sigSetTempZon1Req : 197|6@0+ (0.5,17) [17|32] "Deg^C" FUSION
 SG_ sigHvacFrontReq : 198|1@0+ (1,0) [0|1] "" FUSION
 SG_ sigDfrstReq : 199|1@0+ (1,0) [0|1] "" FUSION
 SG_ GPS_LAT : 167|32@0+ (1,0) [0|4.294967295E9] "SECOND" FUSION
 SG_ GPS_LONG : 135|32@0+ (1,0) [0|4.294967295E9] "" FUSION
 SG_ L_Drv_ControlCommand : 126|7@0+ (1,0) [0|127] "%" FUSION
 SG_ TPMS_Cali_Butt : 127|1@0+ (1,0) [0|1] "" FUSION
 SG_ L_Pas_ControlCommand : 118|7@0+ (1,0) [0|127] "%" FUSION
 SG_ IVI_Unlock_Chg_req : 119|1@0+ (1,0) [0|1] "" FUSION
 SG_ L_RLD_ControlCommand : 110|7@0+ (1,0) [0|127] "%" FUSION
 SG_ IVI_Stop_Chg_req : 111|1@0+ (1,0) [0|1] "" FUSION
 SG_ L_RRD_ControlCommand : 102|7@0+ (1,0) [0|127] "%" FUSION
 SG_ IVI_Start_Chg_req : 103|1@0+ (1,0) [0|1] "" FUSION
 SG_ METER_Malfunc_Sta : 89|2@0+ (1,0) [0|2] "" FUSION
 SG_ sigFootReq : 90|1@0+ (1,0) [0|1] "" FUSION
 SG_ sigFaceReq : 91|1@0+ (1,0) [0|1] "" FUSION
 SG_ Sched_Chg_Start : 92|1@0+ (1,0) [0|1] "" FUSION
 SG_ Sched_Chg_wake : 93|1@0+ (1,0) [0|1] "" FUSION
 SG_ Sched_Chg_butt : 94|1@0+ (1,0) [0|1] "" FUSION
 SG_ Sched_Chg_Stop : 95|1@0+ (1,0) [0|1] "" FUSION
 SG_ Sched_Chg_limit : 84|5@0+ (2,50) [50|100] "%" FUSION
 SG_ Walkaway_Lock_SW : 8|1@0+ (1,0) [0|1] "" FUSION
 SG_ Approach_Unlock_SW : 9|1@0+ (1,0) [0|1] "" FUSION
 SG_ FalseNPrevent_SW : 10|1@0+ (1,0) [0|1] "" FUSION
 SG_ IVI_CreepSW_Req : 11|1@0+ (1,0) [0|1] "" FUSION
 SG_ IVI_PTG_Open_Height : 14|3@0+ (1,0) [0|7] "" FUSION
 SG_ IVI_Req_V2L : 15|1@0+ (1,0) [0|1] "" FUSION
 SG_ Perd_V2L : 3|4@0+ (1,0) [0|15] "" FUSION
 SG_ SOC_V2LLimit : 7|4@0+ (5,20) [20|80] "%" FUSION

BO_ 1179 IVI3: 8 IVI
 SG_ Sched_Chg_End_Time_HR : 28|5@0+ (1,0) [0|23] "HOUR" FUSION
 SG_ Sched_Chg_St_Time_HR : 20|5@0+ (1,0) [0|23] "HOUR" FUSION
 SG_ Sched_Chg_End_Time_Min : 13|6@0+ (1,0) [0|59] "MINUTE" FUSION
 SG_ A2B_Node_sta : 15|1@0+ (1,0) [0|1] "" FUSION
 SG_ Sched_Chg_St_Time_Min : 5|6@0+ (1,0) [0|59] "MINUTE" FUSION
 SG_ Re_Radio_Sta : 6|1@0+ (1,0) [0|1] "" FUSION
 SG_ Sched_Chg_Day_Set : 7|1@0+ (1,0) [0|1] "" FUSION

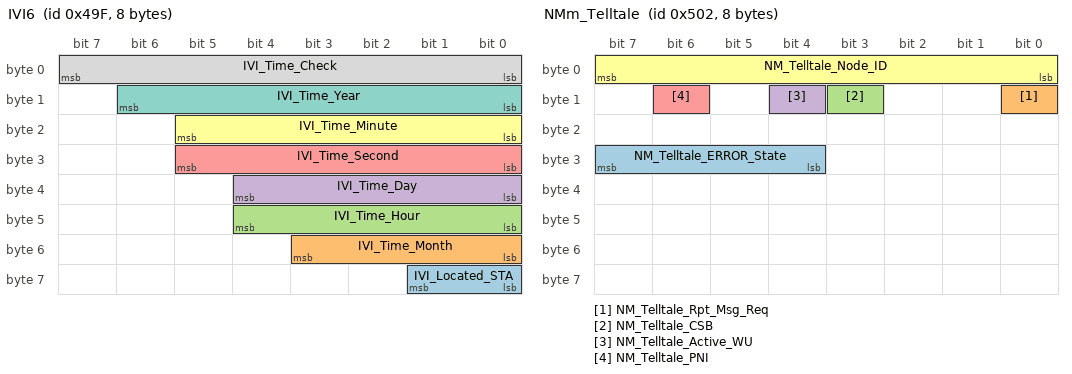
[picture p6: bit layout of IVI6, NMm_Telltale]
BO_ 1183 IVI6: 8 IVI
 SG_ IVI_Located_STA : 57|2@0+ (1,0) [0|3] "" FUSION
 SG_ IVI_Time_Month : 51|4@0+ (1,0) [0|12] "MONTH" FUSION
 SG_ IVI_Time_Hour : 44|5@0+ (1,0) [0|31] "HOUR" FUSION
 SG_ IVI_Time_Day : 36|5@0+ (1,0) [0|31] "DAY" FUSION
 SG_ IVI_Time_Second : 29|6@0+ (1,0) [0|63] "SECOND" FUSION
 SG_ IVI_Time_Minute : 21|6@0+ (1,0) [0|63] "MINUTE" FUSION
 SG_ IVI_Time_Year : 14|7@0+ (1,2000) [2000|2127] "YEAR" FUSION
 SG_ IVI_Time_Check : 7|8@0+ (1,0) [0|255] "" FUSION

BO_ 1282 NMm_Telltale: 8 Telltale
 SG_ NM_Telltale_ERROR_State : 31|4@0+ (1,0) [0|8] "" FUSION
 SG_ NM_Telltale_Rpt_Msg_Req : 8|1@0+ (1,0) [0|1] "" FUSION
 SG_ NM_Telltale_CSB : 11|1@0+ (1,0) [0|1] "" FUSION
 SG_ NM_Telltale_Active_WU : 12|1@0+ (1,0) [0|1] "" FUSION
 SG_ NM_Telltale_PNI : 14|1@0+ (1,0) [0|1] "" FUSION
 SG_ NM_Telltale_Node_ID : 7|8@0+ (1,0) [0|127] "" FUSION

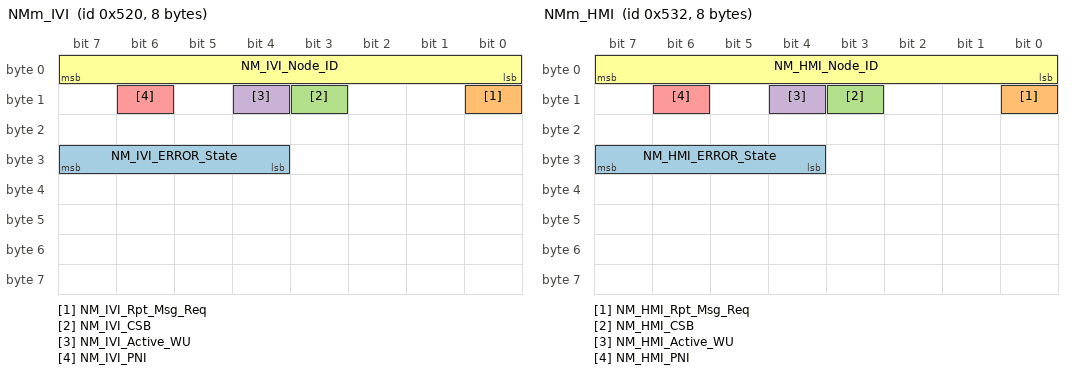
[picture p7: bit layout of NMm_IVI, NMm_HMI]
BO_ 1312 NMm_IVI: 8 IVI
 SG_ NM_IVI_ERROR_State : 31|4@0+ (1,0) [0|8] "" FUSION
 SG_ NM_IVI_Rpt_Msg_Req : 8|1@0+ (1,0) [0|1] "" FUSION
 SG_ NM_IVI_CSB : 11|1@0+ (1,0) [0|1] "" FUSION
 SG_ NM_IVI_Active_WU : 12|1@0+ (1,0) [0|1] "" FUSION
 SG_ NM_IVI_PNI : 14|1@0+ (1,0) [0|1] "" FUSION
 SG_ NM_IVI_Node_ID : 7|8@0+ (1,0) [0|127] "" FUSION

BO_ 1330 NMm_HMI: 8 HMI
 SG_ NM_HMI_ERROR_State : 31|4@0+ (1,0) [0|8] "" FUSION
 SG_ NM_HMI_Rpt_Msg_Req : 8|1@0+ (1,0) [0|1] "" FUSION
 SG_ NM_HMI_CSB : 11|1@0+ (1,0) [0|1] "" FUSION
 SG_ NM_HMI_Active_WU : 12|1@0+ (1,0) [0|1] "" FUSION
 SG_ NM_HMI_PNI : 14|1@0+ (1,0) [0|1] "" FUSION
 SG_ NM_HMI_Node_ID : 7|8@0+ (1,0) [0|127] "" FUSION

BO_ 1538 DiagRespFromTelltale: 8 Telltale
 SG_ DiagRespFromTelltale : 7|64@0+ (1,0) [0|0] "" FUSION

BO_ 1568 DiagRespFromIVI: 8 IVI
 SG_ DiagRespFromIVI : 7|64@0+ (1,0) [0|0] "" FUSION

BO_ 1586 DiagRespFromHMI: 8 HMI
 SG_ DiagRespFromHMI : 7|64@0+ (1,0) [0|0] "" FUSION

BO_ 796 GW_ZoneFR4: 12 FUSION
 SG_ BMSReqRlngCtrHSC6 : 7|4@0+ (1,0) [0|15] "" Vector__XXX
 SG_ BMSReqTapPosHSC6 : 3|4@0+ (1,0) [0|15] "" Vector__XXX
 SG_ BMSReqPwrHSC6 : 15|16@0+ (1,0) [0|65535] "" Vector__XXX
 SG_ BMSReqPWMHSC6 : 31|7@0+ (1,0) [0|100] "" Vector__XXX
 SG_ BMSInptClntTemHSC6 : 24|9@0+ (0.5,-40) [-40|200] "" Vector__XXX
 SG_ BMSReqMdHSC6 : 71|2@0+ (1,0) [0|3] "" Vector__XXX
 SG_ BMSEnbPTCHSC6 : 69|1@0+ (1,0) [0|1] "" Vector__XXX
 SG_ BMSChksmHSC6 : 47|8@0+ (1,0) [0|255] "" Vector__XXX
 SG_ PTCActuPwrHSC6 : 55|16@0+ (1,0) [0|65535] "" IVI
 SG_ COMP_ActualPwr : 68|13@0+ (1,0) [0|6000] "W" IVI

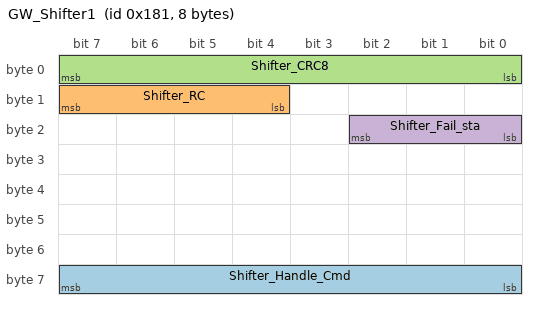
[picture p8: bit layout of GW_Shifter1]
BO_ 385 GW_Shifter1: 8 FUSION
 SG_ Shifter_Handle_Cmd : 63|8@0+ (1,0) [0|255] "" IVI
 SG_ Shifter_RC : 15|4@0+ (1,0) [0|15] "" Vector__XXX
 SG_ Shifter_CRC8 : 7|8@0+ (1,0) [0|255] "" Vector__XXX
 SG_ Shifter_Fail_sta : 18|3@0+ (1,0) [0|7] "" IVI

BO_ 496 FD_VCU0: 16 FUSION
 SG_ SysPwrSta : 7|4@0+ (1,0) [0|15] "" IVI
 SG_ PowerUpState : 15|4@0+ (1,0) [0|7] "" Vector__XXX
 SG_ PowerUpFault : 11|4@0+ (1,0) [0|7] "" Vector__XXX
 SG_ PowerDownState : 22|3@0+ (1,0) [0|7] "" Vector__XXX
 SG_ PowerDownFault : 19|4@0+ (1,0) [0|7] "" Vector__XXX
 SG_ PwrStaSelect : 31|2@0+ (1,0) [0|3] "" Vector__XXX
 SG_ PwrStaConstraint : 29|3@0+ (1,0) [0|4] "" Vector__XXX
 SG_ TCountSta : 26|2@0+ (1,0) [0|2] "" Vector__XXX
 SG_ PwrUpReq : 39|2@0+ (1,0) [0|2] "" Vector__XXX
 SG_ PwrDownReq : 37|2@0+ (1,0) [0|2] "" Vector__XXX
 SG_ Rr_TqSource : 35|4@0+ (1,0) [0|9] "" Vector__XXX
 SG_ Fr_TqSource : 47|4@0+ (1,0) [0|9] "" Vector__XXX
 SG_ LVBattVoltSta : 43|2@0+ (1,0) [0|3] "" Vector__XXX
 SG_ HVTHCMSysAvail : 41|2@0+ (1,0) [0|3] "" Vector__XXX
 SG_ VehHVPwrAvail4THCM : 55|8@0+ (50,0) [0|12650] "W" Vector__XXX
 SG_ VCUBrkSWSta : 63|2@0+ (1,0) [0|2] "" IVI
 SG_ VCUFLDoorSta : 61|1@0+ (1,0) [0|1] "" IVI
 SG_ VCUFRDoorSta : 60|1@0+ (1,0) [0|1] "" IVI
 SG_ VCURLDoorSta : 59|1@0+ (1,0) [0|1] "" IVI
 SG_ VCURRDoorSta : 58|1@0+ (1,0) [0|1] "" IVI
 SG_ SysAllowReadySta : 57|1@0+ (1,0) [0|1] "" IVI
 SG_ HVRlyOpFail : 56|1@0+ (1,0) [0|1] "" IVI
 SG_ MCUActDisFail : 71|1@0+ (1,0) [0|1] "" IVI
 SG_ PwrStaONTOIVIPopReq : 70|1@0+ (1,0) [0|1] "" IVI
 SG_ PwrStaTOSta : 69|1@0+ (1,0) [0|1] "" Vector__XXX
 SG_ PwrStaONTOIVIPopT : 67|12@0+ (1,0) [0|4095] "SECOND" IVI
 SG_ SchedChgTOSta : 87|1@0+ (1,0) [0|1] "" Vector__XXX
 SG_ SilentChkAllowSleep : 86|1@0+ (1,0) [0|1] "" Vector__XXX
 SG_ LVSilentChrgSta : 85|2@0+ (1,0) [0|3] "" Vector__XXX
 SG_ LVSilentChrgLv : 83|2@0+ (1,0) [0|3] "" Vector__XXX
 SG_ LVSilentChrgReq : 81|1@0+ (1,0) [0|1] "" Vector__XXX
 SG_ TimerAllowSleep : 80|1@0+ (1,0) [0|1] "" Vector__XXX
 SG_ PMMAllowECUSleep : 95|1@0+ (1,0) [0|1] "" Vector__XXX
 SG_ LVChrgHoldTAct : 91|12@0+ (1,0) [0|4095] "SECOND" Vector__XXX
 SG_ LVBattChrgtimeAct : 107|12@0+ (1,0) [0|4095] "SECOND" Vector__XXX
 SG_ EVCCAplusPwrUpReq : 94|1@0+ (1,0) [0|1] "" Vector__XXX
 SG_ FDADC12VDetAvg : 127|8@0+ (0.1,0) [0|25.5] "V" Vector__XXX
 SG_ VCUHoodSWSta : 23|1@0+ (1,0) [0|1] "" IVI
 SG_ VCUTailgateSWSta : 24|1@0+ (1,0) [0|1] "" IVI

BO_ 340 FD_VCU2: 16 FUSION
 SG_ ActAPSPosn : 127|8@0+ (0.394,0) [0|100.076] "%" IVI
 SG_ DriverTq : 111|16@0+ (1,-4300) [-4300|4300] "Nm" Vector__XXX
 SG_ VehActPwr : 87|24@0+ (1,-600000) [-600000|600000] "W" Vector__XXX
 SG_ Rr_DriverTq : 39|16@0+ (0.5,-5300) [-5300|5300] "Nm" Vector__XXX
 SG_ Fr_DriverTq : 23|16@0+ (0.5,-5300) [-5300|5300] "Nm" Vector__XXX
 SG_ AccPedal_Override : 14|1@0+ (1,0) [0|1] "" Vector__XXX
 SG_ ACC_CtrlAvail : 15|1@0+ (1,0) [0|1] "" Vector__XXX
 SG_ CS_VCU2_CAN1 : 7|8@0+ (1,0) [0|255] "" Vector__XXX
 SG_ RC_VCU2_CAN1 : 11|4@0+ (1,0) [0|15] "" Vector__XXX

CM_ SG_ 856 DSEAT_Error_Sta "Driver Seat Error Status";
CM_ SG_ 856 DSEAT_EntryFun_Sta "Driver Seat Entry Function Status";
CM_ SG_ 856 DSEAT_EntryAct_Sta "Driver Seat Entry Function Activate Status";
CM_ SG_ 856 DSEAT_Anti_Sta "Driver Seat Antitheft Status";
CM_ SG_ 856 DSEAT_AntiAct_Sta "Driver Seat Antitheft Activate Status";
CM_ SG_ 856 DSEAT_Vent_Sta "Driver Seat Ventilate Staus";
CM_ SG_ 856 DSEAT_Mode "Driver Seat Mode
0=manual, 1=power, 2=power & heater, 
3=power & ventilate, 
4=power & heater & ventilate, 
5=manual & heater, 
6=manual & ventilate, 
7=manual & heater & ventilate";
CM_ SG_ 856 DSEAT_Rec_Pos "Driver Seat Recliner Position
Min=0, 
Max=80, Engineering Unit=deg, Offset=0 deg, Resolution=1 deg per bit, Invaild=255, Undefined=81 - 254";
CM_ SG_ 856 DSEAT_RL_Pos "Driver Seat Rear Lifter Position
Min=0, 
Max=60, Engineering Unit=mm, Offset=0 mm, Resolution=1 mm per bit, Invaild=255, Undefined=61 - 254";
CM_ SG_ 856 DSEAT_Slid_Pos "Driver Seat Slider Position
Min=0, Max=240, Engineering Unit=mm, Offset=0 mm, Resolution=1 mm per bit, Invaild=255, Undefined=241 - 254";
CM_ SG_ 856 DSEAT_FL_Pos "Driver Seat Front Lifter Position
Min=0, Max=25, Engineering Unit=mm,  Offset=0 mm, Resolution=1 mm per bit, Invaild=255, Undefined=26 - 254";
CM_ SG_ 881 PTG_HW_Ver "Power Tail Gate ECU Hardware Version";
CM_ SG_ 881 PTG_SW_Ver "Power Tail Gate ECU Software Version";
CM_ SG_ 881 PTG_Cinch_Current "Power Tail Gate Cinch Motor Current";
CM_ SG_ 881 PTG_Strut_Current "Power Tail Gate Lift Strut Motor Current";
CM_ SG_ 881 PTG_Is_Set_Height "PTG 'Set Open Height' Action Listener";
CM_ SG_ 881 PTG_AutoStaus "Power Tail Gate Auto Status";
CM_ SG_ 881 PTG_Exist "Power Tail Gate Exist";
CM_ SG_ 881 PTG_RDIL_Sta "Power Tail Gate Rear Direction Indicator Lamp State";
CM_ SG_ 881 PTG_Inner_SW_1 "Power Tail Gate Inner SW#1 State";
CM_ SG_ 881 PTG_Sys_Sta "Power Tail Gate System Status";
CM_ SG_ 881 PTG_Full_Lock "Power Tail Gate Latch Full Lock";
CM_ SG_ 881 PTG_Active_Sta "Power Tail Gate Function Activation State";
CM_ SG_ 881 PTG_Warning_Sta "Power Tail Gate Warning";
CM_ SG_ 881 PTG_Half_Lock "Power Tail Gate Latch Half Lock";
CM_ SG_ 881 PTG_Open_Ratio "Power Tail Gate Open Ratio";
CM_ SG_ 884 Req_V2LSwOn "FD asks IVI popup wording for SW on.";
CM_ SG_ 884 Req_OBCV2LEna "FD trigs OBC V2L enabled.";
CM_ SG_ 884 Req_V2L_IVI_Popup "FD asks IVI popup wording for V2L fault.";
CM_ SG_ 886 ChrgCurType "Charging Current Type";
CM_ SG_ 886 HVBattErr "Battery error (HVBattFault)";
CM_ SG_ 886 FireDetErr "Fire detector";
CM_ SG_ 886 ChrgLampSta "Charge lamp status";
CM_ SG_ 917 PSEAT_Error_Sta "Passenger Seat Error Status";
CM_ SG_ 917 PSEAT_Mode "Passenger Seat Mode";
CM_ SG_ 917 PSEAT_Vent_Sta "Passenger Seat Ventilate Staus";
CM_ SG_ 921 Fr_MCU_SW_Ver "Front MCU Software version";
CM_ SG_ 921 Fr_MCU_HW_Ver "Front MCU Hardware version";
CM_ SG_ 925 Rr_MCU3_SW_Ver "Rear MCU Software version";
CM_ SG_ 925 Rr_MCU3_HW_Ver "Rear MCU Hardware version";
CM_ SG_ 960 VehMalfunLevel "Vehicle malfunction level";
CM_ SG_ 960 EVDriveMode "Driving Mode";
CM_ SG_ 960 Eng_AGSCloseSta "AGS close display status";
CM_ SG_ 960 Eng_PwrLockSta "power lock display status";
CM_ SG_ 960 Eng_CoastDwSta "coast down tq map display status";
CM_ SG_ 960 Eng_ActvDmpDisabSta "MCU active damping disable display status";
CM_ SG_ 960 VCU_ACCErr "ACC function Error";
CM_ SG_ 960 VCU_ISAErr "ISA function Error";
CM_ SG_ 960 ZoneDR_SCP_CommErr "ZoneDR_SCP Communication Error";
CM_ SG_ 963 FUSION_SW_SHA8 "software version SHA character 8";
CM_ SG_ 963 FUSION_SW_SHA7 "software version SHA character 7";
CM_ SG_ 963 FUSION_SW_SHA6 "software version SHA character 6";
CM_ SG_ 963 FUSION_SW_SHA5 "software version SHA character 5";
CM_ SG_ 963 FUSION_SW_SHA4 "software version SHA character 4";
CM_ SG_ 963 FUSION_SW_SHA3 " software version SHA character 3";
CM_ SG_ 963 FUSION_SW_SHA2 "software version SHA character 2";
CM_ SG_ 963 FUSION_SW_SHA1 "software version SHA character 1";
CM_ SG_ 963 FUSION_SW_dash2 "software version dash character 2";
CM_ SG_ 963 FUSION_SW_change2 "software version number of change 2";
CM_ SG_ 963 FUSION_SW_change1 "software version number of change 1";
CM_ SG_ 963 FUSION_SW_dash1 "software version dash character 1";
CM_ SG_ 963 FUSION_HW_Ver1 "hardware version character 1";
CM_ SG_ 963 FUSION_HW_Ver2 "hardware version character 2";
CM_ SG_ 963 FUSION_HW_Ver3 "hardware version character 3";
CM_ SG_ 963 FUSION_SW_CarModel1 "software version car model character 1";
CM_ SG_ 963 FUSION_SW_CarModel2 "software version car model character 2";
CM_ SG_ 963 FUSION_SW_CarModel3 "software version car model character 3";
CM_ SG_ 963 FUSION_SW_Controller1 "software version controller character 1";
CM_ SG_ 963 FUSION_SW_Controller2 "software version controller character 2";
CM_ SG_ 963 FUSION_SW_Major1 "software version major character 1";
CM_ SG_ 963 FUSION_SW_Major2 "software version major character 2";
CM_ SG_ 963 FUSION_SW_Minor1 "software version minor character 1";
CM_ SG_ 963 FUSION_SW_Minor2 "software version minor character 2";
CM_ SG_ 963 FUSION_SW_Patch1 "software version patch character 1";
CM_ SG_ 963 FUSION_SW_Patch2 "software version patch character 2";
CM_ SG_ 963 FUSION_SW_Country1 "software version country of target market character 1";
CM_ SG_ 963 FUSION_SW_Country2 "software version country of target market character 2";
CM_ SG_ 963 FUSION_SW_Var "software version car model variation";
CM_ SG_ 965 ZONE_DR_SW_SHA8 "software version SHA character 8";
CM_ SG_ 965 ZONE_DR_SW_SHA7 "software version SHA character 7";
CM_ SG_ 965 ZONE_DR_SW_SHA6 "software version SHA character 6";
CM_ SG_ 965 ZONE_DR_SW_SHA5 "software version SHA character 5";
CM_ SG_ 965 ZONE_DR_SW_SHA4 "software version SHA character 4";
CM_ SG_ 965 ZONE_DR_SW_SHA3 "software version SHA character 3";
CM_ SG_ 965 ZONE_DR_SW_SHA2 "software version SHA character 2";
CM_ SG_ 965 ZONE_DR_SW_SHA1 "software version SHA character 1";
CM_ SG_ 965 ZONE_DR_SW_dash2 "software version dash character 2";
CM_ SG_ 965 ZONE_DR_SW_change2 "software version number of change 2";
CM_ SG_ 965 ZONE_DR_SW_change1 "software version number of change 1";
CM_ SG_ 965 ZONE_DR_SW_dash1 "software version dash character 1";
CM_ SG_ 965 ZONE_DR_HW_Ver1 "ZONE_DR hardware version character 1";
CM_ SG_ 965 ZONE_DR_HW_Ver2 "ZONE_DR hardware version character 2";
CM_ SG_ 965 ZONE_DR_HW_Ver3 "ZONE_DR hardware version character 3";
CM_ SG_ 965 ZONE_DR_SW_CarModel1 "software version car model character 1";
CM_ SG_ 965 ZONE_DR_SW_CarModel2 "software version car model character 2";
CM_ SG_ 965 ZONE_DR_SW_CarModel3 "software version car model character 3";
CM_ SG_ 965 ZONE_DR_SW_Controller1 "software version controller character 1";
CM_ SG_ 965 ZONE_DR_SW_Controller2 "software version controller character 2";
CM_ SG_ 965 ZONE_DR_SW_Major1 "software version major character 1";
CM_ SG_ 965 ZONE_DR_SW_Major2 "software version major character 2";
CM_ SG_ 965 ZONE_DR_SW_Minor1 "software version minor character 1";
CM_ SG_ 965 ZONE_DR_SW_Minor2 "software version minor character 2";
CM_ SG_ 965 ZONE_DR_SW_Patch1 "software version patch character 1";
CM_ SG_ 965 ZONE_DR_SW_Patch2 "software version patch character 2";
CM_ SG_ 965 ZONE_DR_SW_Country1 "software version country of target market character 1";
CM_ SG_ 965 ZONE_DR_SW_Country2 "software version country of target market character 2";
CM_ SG_ 965 ZONE_DR_SW_Var "software version car model variation";
CM_ SG_ 969 ZONE_FR_SW_SHA8 "software version SHA character 8";
CM_ SG_ 969 ZONE_FR_SW_SHA7 "software version SHA character 7";
CM_ SG_ 969 ZONE_FR_SW_SHA6 "software version SHA character 6";
CM_ SG_ 969 ZONE_FR_SW_SHA5 "software version SHA character 5";
CM_ SG_ 969 ZONE_FR_SW_SHA4 "software version SHA character 4";
CM_ SG_ 969 ZONE_FR_SW_SHA3 "software version SHA character 3";
CM_ SG_ 969 ZONE_FR_SW_SHA2 "software version SHA character 2";
CM_ SG_ 969 ZONE_FR_SW_SHA1 "software version SHA character 1";
CM_ SG_ 969 ZONE_FR_SW_dash2 "software version dash character 2";
CM_ SG_ 969 ZONE_FR_SW_change2 "software version number of change 2";
CM_ SG_ 969 ZONE_FR_SW_change1 "software version number of change 1";
CM_ SG_ 969 ZONE_FR_SW_dash1 "software version dash character 1";
CM_ SG_ 969 ZONE_FR_HW_Ver1 "ZONE_FR hardware version character 1";
CM_ SG_ 969 ZONE_FR_HW_Ver2 "ZONE_FR hardware version character 2";
CM_ SG_ 969 ZONE_FR_HW_Ver3 "ZONE_FR hardware version character 3";
CM_ SG_ 969 ZONE_FR_SW_CarModel1 "software version car model character 1";
CM_ SG_ 969 ZONE_FR_SW_CarModel2 "software version car model character 2";
CM_ SG_ 969 ZONE_FR_SW_CarModel3 "software version car model character 3";
CM_ SG_ 969 ZONE_FR_SW_Controller1 "software version controller character 1";
CM_ SG_ 969 ZONE_FR_SW_Controller2 "software version controller character 2";
CM_ SG_ 969 ZONE_FR_SW_Major1 "software version major character 1";
CM_ SG_ 969 ZONE_FR_SW_Major2 "software version major character 2";
CM_ SG_ 969 ZONE_FR_SW_Minor1 "software version minor character 1";
CM_ SG_ 969 ZONE_FR_SW_Minor2 "software version minor character 2";
CM_ SG_ 969 ZONE_FR_SW_Patch1 "software version patch character 1";
CM_ SG_ 969 ZONE_FR_SW_Patch2 "software version patch character 2";
CM_ SG_ 969 ZONE_FR_SW_Country1 "software version country of target market character 1";
CM_ SG_ 969 ZONE_FR_SW_Country2 "software version country of target market character 2";
CM_ SG_ 969 ZONE_FR_SW_Var "software version car model variation";
CM_ SG_ 992 HVBCellVoltMax "HV battery maximum cell Volt";
CM_ SG_ 992 HVBCellVoltMin "HV battery minimum cell Volt";
CM_ SG_ 992 CellTempAvg "Cell average temperature";
CM_ SG_ 992 MaxCellVolt_Num "Maximum cell voltage Number";
CM_ SG_ 992 MinCellVolt_Num "Minimum cell voltage Number";
CM_ SG_ 992 MaxCellTemp_Num "Maximum cell temperature Number";
CM_ SG_ 992 MinCellTemp_Num "Minimum cell temperature Number";
CM_ SG_ 992 HVBMTempMax "HV battery maximum module temperature";
CM_ SG_ 992 HVBMTempMin "HV battery minimum module temperature";
CM_ SG_ 992 Mtemp16 "Module temperature 16";
CM_ SG_ 992 Mtemp17 "Module temperature 17";
CM_ SG_ 992 Mtemp18 "Module temperature 18";
CM_ SG_ 992 Mtemp19 "Module temperature 19";
CM_ SG_ 992 Mtemp20 "Module temperature 20";
CM_ SG_ 992 Mtemp01 "Module Temperature01";
CM_ SG_ 992 Mtemp02 "Module Temperature02";
CM_ SG_ 992 Mtemp03 "Module Temperature03";
CM_ SG_ 992 Mtemp04 "Module Temperature04";
CM_ SG_ 992 Mtemp05 "Module Temperature05";
CM_ SG_ 992 Mtemp06 "Module Temperature06";
CM_ SG_ 992 Mtemp07 "Module Temperature07";
CM_ SG_ 992 Mtemp08 "Module Temperature08";
CM_ SG_ 992 Mtemp09 "Module Temperature09";
CM_ SG_ 992 Mtemp10 "Module Temperature10";
CM_ SG_ 992 Mtemp11 "Module Temperature11";
CM_ SG_ 992 Mtemp12 "Module Temperature12";
CM_ SG_ 992 Mtemp13 "Module Temperature13";
CM_ SG_ 992 Mtemp14 "Module Temperature14";
CM_ SG_ 992 Mtemp15 "Module Temperature15";
CM_ SG_ 997 PSEAT_HW_Ver "Passenger Seat Hardware Version Number";
CM_ SG_ 997 PSEAT_SW_Ver "Passenger Seat Software Version Number";
CM_ SG_ 1016 DSEAT_HW_Ver "Driver Seat Hardware Version Number";
CM_ SG_ 1016 DSEAT_SW_Ver "Driver Seat Software Version Number";
CM_ SG_ 1077 LRWheelPSW "Left_Rear_Wheel PressureSetWarm";
CM_ SG_ 1077 LFWheelPSW "Left_Forward Wheel PressureSetWarm";
CM_ SG_ 1077 RFWheelPSW "Right_Forward Wheel PressureSetWarm";
CM_ SG_ 1077 RRWheelPSW "Right_Rear_Wheel PressureSetWarm";
CM_ SG_ 1077 RFPressIndi "Right_Forward Wheel Pressure Warning Indicator";
CM_ SG_ 1077 LFPressIndi "Left_Forward Wheel Pressure Warning Indicator";
CM_ SG_ 1077 RRPressIndi "Right_Rear_Wheel Pressure Warning Indicator";
CM_ SG_ 1077 LRPressIndi "Left_Rear_Wheel Pressure Warning Indicator";
CM_ SG_ 1077 RFWheelTmpIndi "Right_Forward Wheel Temperature Warning Indicator";
CM_ SG_ 1077 LFWheelTmpIndi "Left_Forward Wheel Temperature Warning Indicator";
CM_ SG_ 1077 RRWheelTmpIndi "Right_Rear_Wheel Temperature Warning Indicator";
CM_ SG_ 1077 LRWheelTmpIndi "Left_Rear_Wheel Temperature Warning Indicator";
CM_ SG_ 1077 RFSensorFail "Right_Forward Wheel Sensor Fail Indicator";
CM_ SG_ 1077 LFSensorFail "Left_Forward Wheel Sensor Fail Indicator";
CM_ SG_ 1077 RRSensorFail "Right_Rear_Wheel Sensor Fail Indicator";
CM_ SG_ 1077 LRSensorFail "Left_Rear_Wheel Sensor Fail Indicator";
CM_ SG_ 1077 RFBatWarn "Right_Forward Wheel Battery Warning";
CM_ SG_ 1077 LFBatWarn "Left_Forward Wheel Battery Warning";
CM_ SG_ 1077 RRBatWarn "Right_Rear_Wheel Battery Warning";
CM_ SG_ 1077 LRBatWarn "Left_Rear_Wheel Battery Warning";
CM_ SG_ 1077 RFWheelDebug "Right_Forward wheel debug";
CM_ SG_ 1077 LFWheelDebug "Left_Forward wheel debug";
CM_ SG_ 1077 RRWheelDebug "Right_Rear_wheel debug";
CM_ SG_ 1077 LRWheelDebug "Left_Rear_wheel debug";
CM_ SG_ 1077 RFWheelPress "Right_Forward Wheel Pressure";
CM_ SG_ 1077 LFWheelPress "Left_Forward Wheel Pressure";
CM_ SG_ 1077 RRWheelPress "Right_Rear_Wheel Pressure";
CM_ SG_ 1077 LRWheelPress "Left_Rear_Wheel Pressure";
CM_ SG_ 1077 RFWheelTemp "Right_Forward Temperature";
CM_ SG_ 1077 LFWheelTemp "Left_Forward Temperature";
CM_ SG_ 1077 RRWheelTemp "Right_Rear_Temperature";
CM_ SG_ 1077 LRWheelTemp "Left_Rear_Temperature";
CM_ SG_ 1077 AutoLTips "Auto location Tips";
CM_ SG_ 1077 CWheelTips "Calibrate Wheel Tips";
CM_ SG_ 1077 TPMS_Cali_Butt_Allow "TPMS Tire calibrate Button Allowable";
CM_ SG_ 1077 TPMS_Res_Butt_Allow "TPMS Reset Button Allowable";
CM_ SG_ 1077 TPMSWarnIndi "TPMS Warning Indicator";
CM_ SG_ 1077 RRSensorMode "Left Rear Wheel TPMS Sensor Mode";
CM_ SG_ 1077 LRSensorMode "Left Rear Wheel TPMS Sensor Mode";
CM_ SG_ 1077 RFSensorMode "Right Front Wheel TPMS Sensor Mode";
CM_ SG_ 1077 LFSensorMode "Left Front Wheel TPMS Sensor Mode";
CM_ SG_ 1078 ID1_ALTU "ID1 Automatic Location Tests Use";
CM_ SG_ 1078 ID2_ALTU "ID2 Automatic Location Tests Use";
CM_ SG_ 1078 ID3_ALTU "ID3 Automatic Location Tests Use";
CM_ SG_ 1078 ID4_ALTU "ID4 Automatic Location Tests Use";
CM_ SG_ 1078 IDin_ALTU "ID input Automatic Location Tests Use";
CM_ SG_ 1078 ID1_Loc_ALTU "Sensor ID1 In Which Locaition Automatic Location Tests Use";
CM_ SG_ 1078 ID2_Loc_ALTU "Sensor ID2 In Which Locaition Automatic Location Tests Use";
CM_ SG_ 1078 ID3_Loc_ALTU "Sensor ID3 In Which Locaition Automatic Location Tests Use";
CM_ SG_ 1078 ID4_Loc_ALTU "Sensor ID4 In Which Locaition Automatic Location Tests Use";
CM_ SG_ 1078 RF_FAT_ALTU "RF Sensor FAT Automatic Location Tests Use";
CM_ SG_ 1078 ID1_message_ALTU "Sensor ID1 message reception Automatic Location Tests Use";
CM_ SG_ 1078 ID2_message_ALTU "Sensor ID2 message reception Automatic Location Tests Use";
CM_ SG_ 1078 ID3_message_ALTU "Sensor ID3 message reception Automatic Location Tests Use";
CM_ SG_ 1078 ID4_message_ALTU "Sensor ID4 message reception Automatic Location Tests Use";
CM_ SG_ 1078 S1WheelDebug_ALTU "S1 RF Reception Automatic Location Tests Use";
CM_ SG_ 1078 S2WheelDebug_ALTU "S2 RF Reception Automatic Location Tests Use";
CM_ SG_ 1078 S3WheelDebug_ALTU "S3 RF Reception Automatic Location Tests Use";
CM_ SG_ 1078 S4WheelDebug_ALTU "S4 RF Reception Automatic Location Tests Use";
CM_ SG_ 1080 OTA_Up_Backcount "Start Update Backcount";
CM_ SG_ 1080 OTA_DL_Speed "Firmware Package download speed";
CM_ SG_ 1080 OTA_Lock_Req "OTA Lock request to DKC";
CM_ SG_ 1080 OTA_Updating_ECU "Fusion MDA is updating ECU";
CM_ SG_ 1080 OTA_Update_Available "Fusion MDA available for update";
CM_ SG_ 1080 OTA_InVehicle_FW "In Vehicle Firmware Version Status";
CM_ SG_ 1080 OTA_DL_Available "Fusion MDA available for download";
CM_ SG_ 1080 OTA_Mode "Vehicel OTA mode Status";
CM_ SG_ 1080 OTA_Network_Type "Vehicle Network Type";
CM_ SG_ 1080 OTA_MDA_Status "Fusion Master OTA agent status";
CM_ SG_ 1080 OTA_Progress_Rate "MDA download or update progress rate";
CM_ SG_ 1080 OTA_Permit_Agreed "Download/Upgrade coundition check result";
CM_ SG_ 1080 OTA_Remained_Time "Download/Upgrade Estimated Time";
CM_ SG_ 1080 OTA_Debug_Code "OTA Error Code for Debug";
CM_ SG_ 1080 OTA_TBOXResetReq "TBOX Reset Request";
CM_ SG_ 1080 OTA_Updating_ECU_8bit "Fusion MDA is updating ECU";
CM_ SG_ 1090 PowerOff_T_Set "Auto Power off time setting";
CM_ SG_ 1090 Re_Radio "Remote Radio on/off";
CM_ SG_ 1090 TBOX_NET_SIG_STR "TBOX Network Signal Strength";
CM_ SG_ 1090 TBOX_TEST_STATUS "TBOX Self Test Status";
CM_ SG_ 1090 ReOutsideMirror "Remote outside mirror control";
CM_ SG_ 1090 CbnPreReq "Cabin Preconditioning Request";
CM_ SG_ 1090 CbnPreACEnaReq "Cabin Preconditioning Air condition open enable";
CM_ SG_ 1090 CbnPreTarT "Cabin Preconditioning Target Temperature";
CM_ SG_ 1090 Uncounting_Req "TBOX Uncounting Request";
CM_ SG_ 1090 TBOX_Remote_PW "TBOX_Remote_PW";
CM_ SG_ 1090 Re_PwrReqTbox "Remote Vehicle Power Status";
CM_ SG_ 1090 TBOX_RemoteOn "Remote command processing to restrict function operation";
CM_ SG_ 1090 TBOX_Re_VehData "remote vehicle data";
CM_ SG_ 1090 Antitheft_Zero "AntitheftBehaviour Zero";
CM_ SG_ 1090 Re_DoorLock "TBOX Remote DoorLock Control.";
CM_ SG_ 1090 TBOX_Re_DTCData "Request vehicle data";
CM_ SG_ 1090 Remote_ACTemp "TBOX Remote_ACTemp";
CM_ SG_ 1090 Remote_AutoReq "TBOX Remote_AutoReq ON_OFF";
CM_ SG_ 1090 Remote_MidAutoReq "TBOX Remote_MidAutoReq ON_OFF";
CM_ SG_ 1174 TimeSyncFromBS_Month "Time Sync. From Base Station of  Month";
CM_ SG_ 1174 TimeSyncFromBS_Hour "Time Sync. From Base Station of Hour";
CM_ SG_ 1174 TimeSyncFromBS_Day "Time Sync. from Base Station - DAY";
CM_ SG_ 1174 TimeSyncFromBS_Second "Time Sync. From Base Station of Second";
CM_ SG_ 1174 TimeSyncFromBS_Minute "Time Sync. From Base Station of Minute";
CM_ SG_ 1174 TimeSyncFromBS_Year "Time Sync. From Base Station of Year";
CM_ SG_ 1249 TBOX_SW_VER "TBOX SW Ver., 4 byte ASCII Code";
CM_ SG_ 1249 TBOX_HW_VER "TBOX HW Ver., 4 byte ASCII Code";
CM_ SG_ 1249 ReserveChargeOn_Minute "APP charge request time ON set";
CM_ SG_ 1249 ReserveChargeOn_Hour "APP charge request time ON set";
CM_ SG_ 1249 ReserveChargeOn_Day "APP charge request time ON set";
CM_ SG_ 1249 ReserveChargeOn_Month "APP charge request time ON set";
CM_ SG_ 1249 ReserveChargeOn_Year "APP charge request time ON set";
CM_ SG_ 1249 ReserveChargeOFF_Minute "APP charge request time OFF set";
CM_ SG_ 1249 ReserveChargeOFF_Hour "APP charge request time OFF set";
CM_ SG_ 1249 ReserveChargeOFF_Day "APP charge request time OFF set";
CM_ SG_ 1249 ReserveChargeOFF_Month "APP charge request time OFF set";
CM_ SG_ 1249 ReserveChargeOFF_Year "APP charge request time OFF set";
CM_ SG_ 1249 Charge_Percent_Set "Charge_Percent_Set";
CM_ SG_ 1280 NM_FUSION_ERROR_State "Defined Error states of the CAN Controller";
CM_ SG_ 1280 NM_FUSION_Rpt_Msg_Req "Repeat Message Request";
CM_ SG_ 1280 NM_FUSION_CSB "NM Coordinator Sleep Bit";
CM_ SG_ 1280 NM_FUSION_Active_WU "Active Wakeup Bit";
CM_ SG_ 1280 NM_FUSION_PNI "Partial Network Information Bit (PNI)";
CM_ SG_ 1280 NM_FUSION_Node_ID "Source Node Identifier";
CM_ SG_ 1666 DiagPhysReqToTelltale "Diagnostic Physical Request to Telltale";
CM_ SG_ 1696 DiagPhysReqToIVI "Diagnostic Physical Request to IVI";
CM_ SG_ 1714 DiagPhysReqToHMI "Diagnostic Physical Request to HMI";
CM_ SG_ 2000 DiagFuncReqFT "Diagnostic Functional Request from Tester";
CM_ SG_ 593 DKC_Remote_PW "DKC_Remote_PW";
CM_ SG_ 593 P_KeyMiss "DKC Key Miss";
CM_ SG_ 593 P_DKey_Area_PTG "Digital key PTG Area";
CM_ SG_ 593 P_KeyMode "DKC Key control Mode";
CM_ SG_ 593 P_Dkey_Show_IVI "Digital key IVI Show";
CM_ SG_ 593 P_CommandToPTG "DKC command to PTG";
CM_ SG_ 593 P_DKey_Area_PS "Digital key PS Area";
CM_ SG_ 593 P_DKey_Area_LockUnlock "Digital key  Lock and Unlock Area";
CM_ SG_ 593 P_DKey_Welcome "Digital key Welcome Area";
CM_ SG_ 593 P_CommandToBCM "DKC command to BCM";
CM_ SG_ 593 DKC_Re_VehData "Request for Remote VehData by DKC";
CM_ SG_ 593 P_UID_LowPower "DKC UID low battery display";
CM_ SG_ 593 DKC_P_BLE_RSSI "DKC BLE RSSI value";
CM_ SG_ 593 DKC_P_UID_BatVolt "DKC UID battery voltage";
CM_ SG_ 342 LF_RawWhlSpeed "Left Front Raw Wheel Speed";
CM_ SG_ 342 LF_RawWhlSpeed_V "Left Front Raw Wheel Speed Validity";
CM_ SG_ 342 LF_WhlRotDir "Left Front Wheel Rotation Direction";
CM_ SG_ 342 LF_PulseCount_V "Left Front Wheel Pulse Counter Validity";
CM_ SG_ 342 LF_PulseCount "Left Front Wheel Pulse Counter";
CM_ SG_ 342 RF_RawWhlSpeed "Right Front Raw Wheel Speed";
CM_ SG_ 342 RF_RawWhlSpeed_V "Right Front Raw Wheel Speed Validity";
CM_ SG_ 342 RF_WhlRotDir "Right Front Wheel Rotation Direction";
CM_ SG_ 342 RF_PulseCount_V "Right Front Wheel Pulse Counter Validity";
CM_ SG_ 342 RF_PulseCount "Right Front Wheel Pulse Counter";
CM_ SG_ 342 F_WhlSpeed_Count "Front Wheel Speed Life Counter";
CM_ SG_ 342 F_WhlSpeed_CRC_8 "Front Wheel Speed Checksum(SAE-J1850-CRC8)";
CM_ SG_ 343 LR_RawWhlSpeed "Left Rear Raw Wheel Speed";
CM_ SG_ 343 LR_RawWhlSpeed_V "Left Rear Raw Wheel Speed Validity";
CM_ SG_ 343 LR_WhlRotDir "Left Rear Wheel Rotation Direction";
CM_ SG_ 343 LR_PulseCount_V "Left Rear Wheel Pulse Counter Validity";
CM_ SG_ 343 LR_PulseCount "Left Rear Wheel Pulse Counter";
CM_ SG_ 343 RR_RawWhlSpeed "Right Rear Raw Wheel Speed";
CM_ SG_ 343 RR_RawWhlSpeed_V "Right Rear Raw Wheel Speed Validity";
CM_ SG_ 343 RR_WhlRotDir "Right Rear Wheel Rotation Direction";
CM_ SG_ 343 RR_PulseCount_V "Right Rear Wheel Pulse Counter Validity";
CM_ SG_ 343 RR_PulseCount "Right Rear Wheel Pulse Counter";
CM_ SG_ 343 R_WhlSpeed_Count "Rear Wheel Speed Life Counter";
CM_ SG_ 343 R_WhlSpeed_CRC_8 "Rear Wheel Speed Checksum(SAE-J1850-CRC8)";
CM_ SG_ 602 ODOMETER "Odometer";
CM_ SG_ 602 Trip_A "TripA";
CM_ SG_ 602 Trip_B "TripB";
CM_ SG_ 602 ParkBrake "Park Brake";
CM_ SG_ 602 Charge "Charge";
CM_ SG_ 602 LEDlitWarnReq "LED lit Warning Request";
CM_ SG_ 602 Spd_Crl_Sta "Speed Control Function Status";
CM_ SG_ 602 Spd_Crl_Mode "Speed Control Function Mode";
CM_ SG_ 602 AvailableTrip "Distance to Empty";
CM_ SG_ 602 AVGPwrConsumption "average power consumption";
CM_ SG_ 602 Averaged_vehspeed "Averaged_vehspeed";
CM_ SG_ 602 METER_MPH_Real "METER Real Speed(MPH)";
CM_ SG_ 602 METER_KPH_Real "METER Real Speed(KPH)";
CM_ SG_ 602 METER_MPH_Calcu "METER Calculated Speed(MPH)";
CM_ SG_ 602 METER_KPH_Calcu "METER Calculated Speed(KPH)";
CM_ SG_ 1168 DRAmbLightBrightnessSet "Door Amber Light Brightness Set";
CM_ SG_ 1168 AmbLightUserSet "AmbLight User Set";
CM_ SG_ 1168 IPAmbLightBrightnessSet "IP Amber Light Brightness Set";
CM_ SG_ 1168 Sched_OTA_wake "Scheduled OTA wake up";
CM_ SG_ 1168 AmbLightColorSet "AmbLight Color Set";
CM_ SG_ 1168 Upd_Countdown_Cancel "Update Countdown Cancel";
CM_ SG_ 1168 Upd_Countdown_Skip "Update Countdown Skip";
CM_ SG_ 1168 LINKtoDrive "LINK to Drive";
CM_ SG_ 1168 OTA_CompNTFY_Pres "OTA Complete notify presented";
CM_ SG_ 1168 OTA_CancelDL_Req "OTA Cancel Download Request";
CM_ SG_ 1168 IVI_OTA_Upd_Sta "IVI OTA Update Status";
CM_ SG_ 1168 OTA_UpdStart_Req "OTA Update Start Request";
CM_ SG_ 1168 OTA_SuspendDL_Req "OTA Suspend Download Request";
CM_ SG_ 1168 OTA_DL_Req "OTA Download Request";
CM_ SG_ 1168 FCP_FrEvt_BtnSyncReq "Sync Button Press";
CM_ SG_ 1168 FCP_MidEvt_BtnAutoReq "Middle Auto Button Press";
CM_ SG_ 1168 FCP_FrEvt_BtnAutoReq "Front Auto Button Press";
CM_ SG_ 1168 FCP_FrEvt_BtnACReq "AC Max Button Press max cooling";
CM_ SG_ 1168 FCP_FrEvt_BtnACMaxReq "AC Max Button Press max cooling";
CM_ SG_ 1168 VehACModReq "Vehicle Air Conition mode
0x2~0x5:Reserved
0x2~0x5:Reserved";
CM_ SG_ 1168 PW_CONTINUE_USE "Power Continue Use";
CM_ SG_ 1168 PW_CLOSE_IMD "Power Close Immediately";
CM_ SG_ 1168 SmartEco_Mode_SW "Smart ECO Mode Switch";
CM_ SG_ 1168 BrkAbn_GoReady_SW "Brake Abnormal Go Ready";
CM_ SG_ 1168 OpenDrOpenWdo_SW "Open Door Link Open Window Switch
IVI";
CM_ SG_ 1168 IVI_Lock_SoundSW_Sta "IVI_Lock_SoundSW_Sta";
CM_ SG_ 1173 AVM_parking_cancel "auto parking cancel";
CM_ SG_ 1173 AVM_parking_excute "confirm and start to auto parking";
CM_ SG_ 1173 AVM_OFF_Rec_Butt "AVM KEYOFF Recording Button";
CM_ SG_ 1173 IVI_AGSCloseSW "IVI AGS close switch";
CM_ SG_ 1173 IVI_LVChrgFuncSW "IVI LV Charging function switch";
CM_ SG_ 1173 IVI_PwrLockSW "IVI Power State Lock Switch";
CM_ SG_ 1173 IVI_CoastDwSW "IVI Coastdown switch";
CM_ SG_ 1173 IVI_ActvDmpDisabSW "IVI Active Damping Disable Switch";
CM_ SG_ 1173 Roll_Mode_SW_Cmd "Roll Mode Switch command";
CM_ SG_ 1173 TCS_SW_Cmd "TCS Switch command";
CM_ SG_ 1173 SLIF_BUTT "SLIF  ON/OFF Buttom";
CM_ SG_ 1173 Roll_Eng_Mode "Roll Engine Mode";
CM_ SG_ 1173 SOC_Limit_Set "SOC Charging Limitation Setting";
CM_ SG_ 1173 CDL_Lock_Butt "Central Door Lock_LOCK_Button";
CM_ SG_ 1173 CDL_Unlock_Butt "Central Door Lock_UNLOCK_Button";
CM_ SG_ 1173 SOC_ADJ_BUTT "SOC Charging Limitation Adjust Button";
CM_ SG_ 1173 AC_Chg_Cur_Set "AC Charging Current Setting";
CM_ SG_ 1173 IVI_ISA_OffsetSpd "IVI ISA Offset speed";
CM_ SG_ 1173 RoomLampMode "Room lampt on/off connected with car door open/close";
CM_ SG_ 1173 NAVI_SpeedLimit "Information for Current Link Speed Limit expressed as km/h or mph";
CM_ SG_ 1173 NAVI_RoadClass "Information for Road Class";
CM_ SG_ 1173 NAVI_Tollgate "Information for Tollgate exist (Exist information shall be informed 500m ahead)";
CM_ SG_ 1173 NAVI_LinkClass "Information for Link Class Value of Segment";
CM_ SG_ 1173 NAVI_Tunnel "Information for Tunnel exist (Exist information shall be informed 500m ahead)";
CM_ SG_ 1173 NAVI_ForwardLinkLevel "Information for Forward Link Level in Freeway (Change information shall be informed 500m ahead)";
CM_ SG_ 1173 SenstivityPosition "wiper Senstivity Position";
CM_ SG_ 1173 AVM_Parking_mode "AVM_Parking Mode";
CM_ SG_ 1173 Hood_Latch_SW "Hood Latch Switch";
CM_ SG_ 1173 RCTA_BUTT "RCTA ON/OFF Button";
CM_ SG_ 1173 IVI_Pwroff_req "IVI Power off request";
CM_ SG_ 1173 IVI_Trigger_req "IVI Trigger VCU to Ready request";
CM_ SG_ 1173 AVM_Err_STA "AVM Error Status";
CM_ SG_ 1173 NAVI_Distance_info "NAVI Distance Information";
CM_ SG_ 1173 IVI_Mute_Sta "IVI Mute status";
CM_ SG_ 1173 IVI_PTG_USSta_SW "Power Tail Gate Ultrasonic On/Off Switch";
CM_ SG_ 1173 IVI_WI_MAIN_SW "IVI Wiper Maintance_Switch";
CM_ SG_ 1173 IVI_RR_Def_Req "IVI Rear Deffogger Status";
CM_ SG_ 1173 IVI_Night_Mode_Sta "IVI Night Mode Status";
CM_ SG_ 1173 IVI_Status "IVI Status";
CM_ SG_ 1173 LVDAMute_BUTT "LDW Mute Buttom";
CM_ SG_ 1173 CAAS_Sw "Collision Avoidance Assistance System Switch Status";
CM_ SG_ 1173 DSEAT_entryfun_set "Driver Seat Entry on/off request";
CM_ SG_ 1173 DSEAT_anti_set "Driver Seat Antitheft on/off request";
CM_ SG_ 1173 TPMS_Res_Butt "TPMS_Reset_button";
CM_ SG_ 1173 FollowMeSW "Follow Me Home SW";
CM_ SG_ 1173 SetUnlockSingle "Single Set Unlock DOOR SETTING";
CM_ SG_ 1173 IVI_PTG_Mode_SW "Power Tail Gate Manual and Automatic mode Switch";
CM_ SG_ 1173 IVI_PTG_Sta_SW "Power Tail Gate Open and Close Switch";
CM_ SG_ 1173 SLG_Sw "Smart liftgate Switch Status";
CM_ SG_ 1173 FS_Off_Sw "F_USS Switch Status";
CM_ SG_ 1173 PSEAT_vent_req "Passenger Seat Ventilate request
0= No Request,
1= Vent1,
2= Vent2,
3= Vent3,
4= Off";
CM_ SG_ 1173 FFogLampSW "Front Fog Lamp Switch";
CM_ SG_ 1173 DSEAT_vent_req "Driver Seat ventilate request";
CM_ SG_ 1173 RFogLampSW "Rear Fog Lamp Switch";
CM_ SG_ 1173 MFRD_N_Bright_Req "MFRD night Brightness setting";
CM_ SG_ 1173 User_p_download "User profile download";
CM_ SG_ 1173 HeadLampSW "Head Lamp Switch";
CM_ SG_ 1173 NAVI_State "Information for Navigation Status";
CM_ SG_ 1173 Wifi_Sta_IVI_TBOX "Wifi signal status between IVI and TBOX";
CM_ SG_ 1173 IVI_Panel_Y_Coor "IVI Touch Panel Y coordinate";
CM_ SG_ 1173 IVI_Panel_X_Coor "IVI Touch Panel X coordinate";
CM_ SG_ 1173 NAVI_Cam_Dist_info "Navigation speed camera distance information";
CM_ SG_ 1173 OFF_AC_MODE "OFF AC MODE";
CM_ SG_ 1173 IVI_PW_Mode_Req "IVI Power Mode require";
CM_ SG_ 1173 User_p_upload "User profile upload";
CM_ SG_ 1173 CameraWrn "Speed cameras Warming";
CM_ SG_ 1173 Wifi_Reset "Wifi Reset between VIG and OBU";
CM_ SG_ 1173 NAVI_Direction_STA "NAVI Direction Status";
CM_ SG_ 1173 IVI_Screen "IVI Screen
0x1d~0x3E:undefined";
CM_ SG_ 1173 TurnSwTimeSet "turning switch flash time set";
CM_ SG_ 1173 Pressure_unit "Pressure unit";
CM_ SG_ 1173 Time_system "Time system";
CM_ SG_ 1173 NAVI_Speed_Limit_A "NAVI Speed Limitation Applicable";
CM_ SG_ 1173 Temperature_unit "Temperature unit";
CM_ SG_ 1173 Distance_unit "Distance unit";
CM_ SG_ 1173 ESC_SW_Cmd "ESC ON/OFF Buttom";
CM_ SG_ 1173 IVI_Panel_Act "IVI Touch Panel Active";
CM_ SG_ 1173 sigHvacRearReq "Request for operation for the rear HVAC (ON / OFF)";
CM_ SG_ 1173 FCWMute_BUTT "FCW Mute Buttom";
CM_ SG_ 1173 LKA_BUTT "LKA  ON/OFF Buttom";
CM_ SG_ 1173 ODAMute_BUTT "ODA Mute Buttom";
CM_ SG_ 1173 LDWMute_BUTT "LDW Mute Buttom";
CM_ SG_ 1173 BSDMute_BUTT "BSD Mute Buttom";
CM_ SG_ 1173 sigWindDirZon3Req "Request to HVAC Wind Direction Zone 3. 
Feed, Body and/or Auto";
CM_ SG_ 1173 sigAirIntenZon3Req "Request to HVAC FAN Level/Air Intensirty: 0-Max or Auto for zone 3
0xb~0xE:Reserved
0xb~0xE:Reserved
0xb~0xE:Reserved";
CM_ SG_ 1173 sigAirIntenZon1Req "Request to HVAC FAN Level/Air Intensirty: 0-Max or Auto for zone 1
0xb~0xE:Reserved
0xb~0xE:Reserved
0xb~0xE:Reserved";
CM_ SG_ 1173 AEB_BUTT "AEB  ON/OFF Buttom";
CM_ SG_ 1173 sigSetTempZon3Req "Temperature setpoint  for HVAC Zone 3";
CM_ SG_ 1173 sigSetTempZon2Req "Temperature setpoint  for HVAC Zone 2";
CM_ SG_ 1173 sigRecircReq "Recirculation request for the HVAC (ON / AUTO)";
CM_ SG_ 1173 sigHvacReq "Request for operation for the HVAC (ON / OFF)";
CM_ SG_ 1173 sigSetTempZon1Req "Temperature setpoint  for HVAC Zone 1";
CM_ SG_ 1173 sigHvacFrontReq "Request for operation for the front HVAC (ON / OFF)";
CM_ SG_ 1173 sigDfrstReq "Defrost request for the HVAC (ON / AUTO)";
CM_ SG_ 1173 GPS_LAT "GPS Location_Latitude";
CM_ SG_ 1173 GPS_LONG "GPS Location_Longitude";
CM_ SG_ 1173 L_Drv_ControlCommand "Driver window control command";
CM_ SG_ 1173 TPMS_Cali_Butt "TPMS tire calibrate button";
CM_ SG_ 1173 L_Pas_ControlCommand "Passenger window control command";
CM_ SG_ 1173 IVI_Unlock_Chg_req "IVI unlock Charging port Request";
CM_ SG_ 1173 L_RLD_ControlCommand "Rear Left window control command";
CM_ SG_ 1173 IVI_Stop_Chg_req "IVI Stop Charging Request";
CM_ SG_ 1173 L_RRD_ControlCommand "Rear Right  window control command";
CM_ SG_ 1173 IVI_Start_Chg_req "IVI Start Charging Request";
CM_ SG_ 1173 METER_Malfunc_Sta "Meter Malfunction Status";
CM_ SG_ 1173 sigFootReq "FOOT BLOWER REQUEST";
CM_ SG_ 1173 sigFaceReq "FACE BLOWER REQUEST";
CM_ SG_ 1173 Sched_Chg_Start "Scheduled Charging Start";
CM_ SG_ 1173 Sched_Chg_wake "Scheduled Charging wake up";
CM_ SG_ 1173 Sched_Chg_butt "Scheduled Charging Button";
CM_ SG_ 1173 Sched_Chg_Stop "Scheduled Charging stop";
CM_ SG_ 1173 Sched_Chg_limit "Scheduled Charging charging limit";
CM_ SG_ 1173 Walkaway_Lock_SW "Lock when walking away";
CM_ SG_ 1173 Approach_Unlock_SW "Unlock when approaching Switch";
CM_ SG_ 1173 FalseNPrevent_SW "Prevent FALSE turn GEAR into N";
CM_ SG_ 1173 IVI_CreepSW_Req "IVI Creep On/Off Switch Request";
CM_ SG_ 1173 IVI_PTG_Open_Height "IVI 'PTG Open Height' Menu Status";
CM_ SG_ 1173 IVI_Req_V2L "IVI require V2L on/off";
CM_ SG_ 1173 Perd_V2L "V2L Period Setting";
CM_ SG_ 1173 SOC_V2LLimit "SOC V2LLimitation";
CM_ SG_ 1179 Sched_Chg_End_Time_HR "Scheduled Charging End Time Hour Setting";
CM_ SG_ 1179 Sched_Chg_St_Time_HR "Scheduled Charging Start Time Hour Setting";
CM_ SG_ 1179 Sched_Chg_End_Time_Min "Scheduled Charging End Time Minute Setting";
CM_ SG_ 1179 A2B_Node_sta "A2B node status";
CM_ SG_ 1179 Sched_Chg_St_Time_Min "Scheduled Charging Start Time Minute Setting";
CM_ SG_ 1179 Re_Radio_Sta "Re-active Radio Status";
CM_ SG_ 1179 Sched_Chg_Day_Set "Scheduled Charging Daily setting";
CM_ SG_ 1183 IVI_Located_STA "IVI_GPS Satellite Located status";
CM_ SG_ 1183 IVI_Time_Month "IVI_GPS Satellite Time_Month";
CM_ SG_ 1183 IVI_Time_Hour "IVI_GPS Satellite Time_Hour";
CM_ SG_ 1183 IVI_Time_Day "IVI_GPS Satellite Time_Day";
CM_ SG_ 1183 IVI_Time_Second "IVI_GPS Satellite Time_Second";
CM_ SG_ 1183 IVI_Time_Minute "IVI_GPS Satellite Time_Minute";
CM_ SG_ 1183 IVI_Time_Year "IVI_GPS Satellite Time_Year";
CM_ SG_ 1183 IVI_Time_Check "IVI_GPS Satellite Time_Check Sum";
CM_ SG_ 1282 NM_Telltale_ERROR_State "Defined Error states of the CAN Controller";
CM_ SG_ 1282 NM_Telltale_Rpt_Msg_Req "Repeat Message Request";
CM_ SG_ 1282 NM_Telltale_CSB "NM Coordinator Sleep Bit";
CM_ SG_ 1282 NM_Telltale_Active_WU "Active Wakeup Bit";
CM_ SG_ 1282 NM_Telltale_PNI "Partial Network Information Bit (PNI)";
CM_ SG_ 1282 NM_Telltale_Node_ID "Source Node Identifier";
CM_ SG_ 1312 NM_IVI_ERROR_State "Defined Error states of the CAN Controller";
CM_ SG_ 1312 NM_IVI_Rpt_Msg_Req "Repeat Message Request";
CM_ SG_ 1312 NM_IVI_CSB "NM Coordinator Sleep Bit";
CM_ SG_ 1312 NM_IVI_Active_WU "Active Wakeup Bit";
CM_ SG_ 1312 NM_IVI_PNI "Partial Network Information Bit (PNI)";
CM_ SG_ 1312 NM_IVI_Node_ID "Source Node Identifier";
CM_ SG_ 1330 NM_HMI_ERROR_State "Defined Error states of the CAN Controller";
CM_ SG_ 1330 NM_HMI_Rpt_Msg_Req "Repeat Message Request";
CM_ SG_ 1330 NM_HMI_CSB "NM Coordinator Sleep Bit";
CM_ SG_ 1330 NM_HMI_Active_WU "Active Wakeup Bit";
CM_ SG_ 1330 NM_HMI_PNI "Partial Network Information Bit (PNI)";
CM_ SG_ 1330 NM_HMI_Node_ID "Source Node Identifier";
CM_ SG_ 1538 DiagRespFromTelltale "Diagnostic Response from Telltale";
CM_ SG_ 1568 DiagRespFromIVI "Diagnostic Response from IVI";
CM_ SG_ 1586 DiagRespFromHMI "Diagnostic Response from HMI";
CM_ SG_ 796 COMP_ActualPwr "COMP actual power";
CM_ SG_ 385 Shifter_Handle_Cmd "Shifter Control Unit handle Command(PRND)";
CM_ SG_ 385 Shifter_RC "shifter_rollingcounter";
CM_ SG_ 385 Shifter_CRC8 "shifter_checksum";
CM_ SG_ 385 Shifter_Fail_sta "Shifter fail status";
CM_ SG_ 496 SysPwrSta "System power mode";
CM_ SG_ 496 PowerUpState "Power up mode";
CM_ SG_ 496 PowerUpFault "Power up fault";
CM_ SG_ 496 PowerDownState "Power down state";
CM_ SG_ 496 PowerDownFault "Power down fault";
CM_ SG_ 496 PwrStaSelect "Power state select";
CM_ SG_ 496 PwrStaConstraint "Power state constraint";
CM_ SG_ 496 TCountSta "Timmer counting state";
CM_ SG_ 496 PwrUpReq "Power up request";
CM_ SG_ 496 Rr_TqSource "Rear EDU Torque Source";
CM_ SG_ 496 Fr_TqSource "Front EDU Torque Source";
CM_ SG_ 496 LVBattVoltSta "LV battery voltage state";
CM_ SG_ 496 HVTHCMSysAvail "HV THCM syetem avaliable state";
CM_ SG_ 496 VehHVPwrAvail4THCM "Vehicle HV power avalible for THCM";
CM_ SG_ 496 VCUBrkSWSta "VCU brake SW state";
CM_ SG_ 496 VCUFLDoorSta "VCU FL door state";
CM_ SG_ 496 VCUFRDoorSta "VCU FR door state";
CM_ SG_ 496 VCURLDoorSta "VCU RL door state";
CM_ SG_ 496 VCURRDoorSta "VCU RR door state";
CM_ SG_ 496 SysAllowReadySta "System allow  to ready state";
CM_ SG_ 496 HVRlyOpFail "HV relay opend fail";
CM_ SG_ 496 MCUActDisFail "MCU active discharge fail";
CM_ SG_ 496 PwrStaONTOIVIPopReq "Power state ON timeout IVI popup";
CM_ SG_ 496 PwrStaTOSta "Power state timeout state";
CM_ SG_ 496 PwrStaONTOIVIPopT "Count down time value for power state ON timeout IVI popup";
CM_ SG_ 496 SchedChgTOSta "Schedule charge timeout state";
CM_ SG_ 496 SilentChkAllowSleep "Silent charge check allow sleep flag.";
CM_ SG_ 496 LVSilentChrgSta "V Silent Chrge State";
CM_ SG_ 496 LVSilentChrgLv "LV silent charging level";
CM_ SG_ 496 LVSilentChrgReq "LV Silent Chrge Request";
CM_ SG_ 496 TimerAllowSleep "Timer allow sleep flag.";
CM_ SG_ 496 PMMAllowECUSleep "PMM allow ECU sleep flag.";
CM_ SG_ 496 LVChrgHoldTAct "Calibration value for LV charge hold time";
CM_ SG_ 496 LVBattChrgtimeAct "V Battery charge time.";
CM_ SG_ 496 EVCCAplusPwrUpReq "EVCC A-plus signal power up request.";
CM_ SG_ 496 FDADC12VDetAvg "FD ADC 12V detect voltage average value";
CM_ SG_ 496 VCUHoodSWSta "VCU hood SW state";
CM_ SG_ 496 VCUTailgateSWSta "VCU Tailgate SW state";
CM_ SG_ 340 ActAPSPosn "Accelerator Actual Position";
CM_ SG_ 340 DriverTq "Driver's Torque";
CM_ SG_ 340 VehActPwr "Vehicle Actual Power";
CM_ SG_ 340 Rr_DriverTq "Driver's Torque on Rear Axle";
CM_ SG_ 340 Fr_DriverTq "Driver's Torque on Front Axle";
CM_ SG_ 340 AccPedal_Override "Drvier Acceleration (Pedal) Override";
CM_ SG_ 340 ACC_CtrlAvail "VCU available for ACC control";
CM_ SG_ 340 CS_VCU2_CAN1 "VCU2 frame checksum(SAEJ1850)
x^8+x^4+x^3+x^2+1 
It shall use 0xFF as the start value and XOR value.";
CM_ SG_ 340 RC_VCU2_CAN1 "VCU2 4-bit rolling counter";
BA_DEF_ BO_ "GenMsgSendType" ENUM "Cycle","NoMsgSendType","IfActive","Event","CA","CE";
BA_DEF_ BO_ "GenMsgNrOfRepetition" INT 0 0;
BA_DEF_ BO_ "GenMsgILSupport" ENUM "No","Yes";
BA_DEF_ BO_ "GenMsgDelayTime" INT 0 0;
BA_DEF_ BO_ "GenMsgCycleTimeFast" INT 0 0;
BA_DEF_ BO_ "GenMsgCycleTime" INT 0 0;
BA_DEF_ BO_ "DiagResponse" ENUM "No","Yes";
BA_DEF_ BO_ "DiagRequest" ENUM "No","Yes";
BA_DEF_ BO_ "NmMessage" ENUM "No","Yes";
BA_DEF_ BO_ "VFrameFormat" ENUM "StandardCAN","ExtendedCAN","reserved","reserved","reserved","reserved","reserved","reserved","reserved","reserved","reserved","reserved","reserved","reserved","StandardCAN_FD","ExtendedCAN_FD";
BA_DEF_ BO_ "GenMsgRequestable" INT 0 1;
BA_DEF_ BO_ "DataID_Hex" HEX 0 65535;
BA_DEF_ BO_ "DoIPLogicalAddress" STRING ;
BA_DEF_ BO_ "DataID" STRING ;
BA_DEF_ BO_ "CANFD_BRS" ENUM "0","1";
BA_DEF_ SG_ "GenSigInvalidValue" HEX 0 0;
BA_DEF_ SG_ "GenSigStartValue" HEX 0 0;
BA_DEF_ SG_ "GenSigInactiveValue" HEX 0 0;
BA_DEF_ SG_ "GenSigRoutingTimeoutValue_String" STRING ;
BA_DEF_ SG_ "GenSigRoutingTimeoutValue" HEX 0 0;
BA_DEF_ SG_ "GenSigSendType" ENUM "Cycle","OnWrite","OnWriteWithRepetition","OnChange","OnChangeWithRepetition","IfActive","IfActiveWithRepetition","NoSigSendType","vector_leerstring";
BA_DEF_ SG_ "SigType" ENUM "Default","Range","RangeSigned","ASCII","Discrete","Control","ReferencePGN","DTC","StringDelimiter","StringLength","StringLengthControl","MessageCounter","MessageChecksum";
BA_DEF_ SG_ "GenSigILSupport" ENUM "No","Yes";
BA_DEF_DEF_ "GenMsgSendType" "Cycle";
BA_DEF_DEF_ "GenMsgNrOfRepetition" 0;
BA_DEF_DEF_ "GenMsgILSupport" "Yes";
BA_DEF_DEF_ "GenMsgDelayTime" 0;
BA_DEF_DEF_ "GenMsgCycleTimeFast" 0;
BA_DEF_DEF_ "GenMsgCycleTime" 100;
BA_DEF_DEF_ "DiagResponse" "No";
BA_DEF_DEF_ "DiagRequest" "No";
BA_DEF_DEF_ "NmMessage" "No";
BA_DEF_DEF_ "VFrameFormat" "StandardCAN";
BA_DEF_DEF_ "GenMsgRequestable" 1;
BA_DEF_DEF_ "DataID_Hex" 0;
BA_DEF_DEF_ "DoIPLogicalAddress" "";
BA_DEF_DEF_ "DataID" "";
BA_DEF_DEF_ "CANFD_BRS" "1";
BA_DEF_DEF_ "GenSigInvalidValue" 0;
BA_DEF_DEF_ "GenSigStartValue" 0;
BA_DEF_DEF_ "GenSigInactiveValue" 0;
BA_DEF_DEF_ "GenSigRoutingTimeoutValue_String" "";
BA_DEF_DEF_ "GenSigRoutingTimeoutValue" 0;
BA_DEF_DEF_ "GenSigSendType" "Cycle";
BA_DEF_DEF_ "SigType" "Default";
BA_DEF_DEF_ "GenSigILSupport" "Yes";
BA_ "GenMsgNrOfRepetition" BO_ 856 1;
BA_ "GenMsgCycleTime" BO_ 856 200;
BA_ "GenMsgDelayTime" BO_ 856 5;
BA_ "GenMsgCycleTimeFast" BO_ 856 20;
BA_ "GenMsgSendType" BO_ 856 5;
BA_ "VFrameFormat" BO_ 856 14;
BA_ "VFrameFormat" BO_ 881 14;
BA_ "GenMsgNrOfRepetition" BO_ 884 1;
BA_ "GenMsgCycleTimeFast" BO_ 884 10;
BA_ "GenMsgSendType" BO_ 884 5;
BA_ "VFrameFormat" BO_ 884 14;
BA_ "GenMsgNrOfRepetition" BO_ 886 1;
BA_ "GenMsgCycleTime" BO_ 886 1000;
BA_ "GenMsgCycleTimeFast" BO_ 886 10;
BA_ "GenMsgSendType" BO_ 886 5;
BA_ "VFrameFormat" BO_ 886 14;
BA_ "GenMsgCycleTime" BO_ 917 200;
BA_ "VFrameFormat" BO_ 917 14;
BA_ "GenMsgCycleTime" BO_ 921 1000;
BA_ "VFrameFormat" BO_ 921 14;
BA_ "GenMsgCycleTime" BO_ 925 1000;
BA_ "VFrameFormat" BO_ 925 14;
BA_ "GenMsgNrOfRepetition" BO_ 960 1;
BA_ "GenMsgCycleTime" BO_ 960 200;
BA_ "GenMsgCycleTimeFast" BO_ 960 50;
BA_ "GenMsgSendType" BO_ 960 5;
BA_ "VFrameFormat" BO_ 960 14;
BA_ "GenMsgCycleTime" BO_ 963 5000;
BA_ "VFrameFormat" BO_ 963 14;
BA_ "GenMsgCycleTime" BO_ 965 5000;
BA_ "VFrameFormat" BO_ 965 14;
BA_ "GenMsgCycleTime" BO_ 969 5000;
BA_ "VFrameFormat" BO_ 969 14;
BA_ "VFrameFormat" BO_ 992 14;
BA_ "GenMsgCycleTime" BO_ 997 1000;
BA_ "VFrameFormat" BO_ 997 14;
BA_ "GenMsgCycleTime" BO_ 1016 1000;
BA_ "VFrameFormat" BO_ 1016 14;
BA_ "GenMsgNrOfRepetition" BO_ 1077 1;
BA_ "GenMsgCycleTime" BO_ 1077 200;
BA_ "GenMsgCycleTimeFast" BO_ 1077 10;
BA_ "GenMsgSendType" BO_ 1077 5;
BA_ "VFrameFormat" BO_ 1077 14;
BA_ "GenMsgNrOfRepetition" BO_ 1078 1;
BA_ "GenMsgCycleTime" BO_ 1078 200;
BA_ "GenMsgCycleTimeFast" BO_ 1078 10;
BA_ "GenMsgSendType" BO_ 1078 5;
BA_ "VFrameFormat" BO_ 1078 14;
BA_ "GenMsgNrOfRepetition" BO_ 1080 1;
BA_ "GenMsgCycleTime" BO_ 1080 200;
BA_ "GenMsgCycleTimeFast" BO_ 1080 20;
BA_ "GenMsgSendType" BO_ 1080 5;
BA_ "VFrameFormat" BO_ 1080 14;
BA_ "GenMsgCycleTime" BO_ 1090 200;
BA_ "VFrameFormat" BO_ 1090 14;
BA_ "GenMsgCycleTime" BO_ 1174 300000;
BA_ "VFrameFormat" BO_ 1174 14;
BA_ "GenMsgNrOfRepetition" BO_ 1249 1;
BA_ "GenMsgCycleTime" BO_ 1249 1000;
BA_ "GenMsgCycleTimeFast" BO_ 1249 10;
BA_ "GenMsgSendType" BO_ 1249 5;
BA_ "VFrameFormat" BO_ 1249 14;
BA_ "GenMsgCycleTime" BO_ 1280 0;
BA_ "NmMessage" BO_ 1280 1;
BA_ "GenMsgSendType" BO_ 1280 3;
BA_ "GenMsgCycleTime" BO_ 1666 0;
BA_ "DiagRequest" BO_ 1666 1;
BA_ "GenMsgSendType" BO_ 1666 3;
BA_ "VFrameFormat" BO_ 1666 14;
BA_ "DoIPLogicalAddress" BO_ 1666 "0x0682";
BA_ "GenMsgCycleTime" BO_ 1696 0;
BA_ "DiagRequest" BO_ 1696 1;
BA_ "GenMsgSendType" BO_ 1696 3;
BA_ "VFrameFormat" BO_ 1696 14;
BA_ "DoIPLogicalAddress" BO_ 1696 "0x06A0";
BA_ "GenMsgCycleTime" BO_ 1714 0;
BA_ "DiagRequest" BO_ 1714 1;
BA_ "GenMsgSendType" BO_ 1714 3;
BA_ "VFrameFormat" BO_ 1714 14;
BA_ "DoIPLogicalAddress" BO_ 1714 "0x06B2";
BA_ "GenMsgCycleTime" BO_ 2000 0;
BA_ "DiagRequest" BO_ 2000 1;
BA_ "GenMsgSendType" BO_ 2000 3;
BA_ "VFrameFormat" BO_ 2000 14;
BA_ "DoIPLogicalAddress" BO_ 2000 "0xEFFF";
BA_ "GenMsgNrOfRepetition" BO_ 593 1;
BA_ "GenMsgCycleTimeFast" BO_ 593 10;
BA_ "GenMsgSendType" BO_ 593 5;
BA_ "VFrameFormat" BO_ 593 14;
BA_ "GenMsgCycleTime" BO_ 342 10;
BA_ "VFrameFormat" BO_ 342 14;
BA_ "GenMsgCycleTime" BO_ 343 10;
BA_ "VFrameFormat" BO_ 343 14;
BA_ "GenMsgNrOfRepetition" BO_ 602 1;
BA_ "GenMsgCycleTimeFast" BO_ 602 10;
BA_ "GenMsgSendType" BO_ 602 5;
BA_ "VFrameFormat" BO_ 602 14;
BA_ "GenMsgNrOfRepetition" BO_ 1168 1;
BA_ "GenMsgCycleTime" BO_ 1168 500;
BA_ "GenMsgCycleTimeFast" BO_ 1168 50;
BA_ "GenMsgSendType" BO_ 1168 5;
BA_ "VFrameFormat" BO_ 1168 14;
BA_ "GenMsgNrOfRepetition" BO_ 1173 1;
BA_ "GenMsgCycleTime" BO_ 1173 200;
BA_ "GenMsgDelayTime" BO_ 1173 5;
BA_ "GenMsgCycleTimeFast" BO_ 1173 20;
BA_ "GenMsgSendType" BO_ 1173 5;
BA_ "VFrameFormat" BO_ 1173 14;
BA_ "GenMsgNrOfRepetition" BO_ 1179 1;
BA_ "GenMsgCycleTime" BO_ 1179 1000;
BA_ "GenMsgCycleTimeFast" BO_ 1179 10;
BA_ "GenMsgSendType" BO_ 1179 5;
BA_ "VFrameFormat" BO_ 1179 14;
BA_ "GenMsgCycleTime" BO_ 1183 1000;
BA_ "VFrameFormat" BO_ 1183 14;
BA_ "GenMsgCycleTime" BO_ 1282 0;
BA_ "NmMessage" BO_ 1282 1;
BA_ "GenMsgSendType" BO_ 1282 3;
BA_ "GenMsgCycleTime" BO_ 1312 0;
BA_ "NmMessage" BO_ 1312 1;
BA_ "GenMsgSendType" BO_ 1312 3;
BA_ "GenMsgCycleTime" BO_ 1330 0;
BA_ "NmMessage" BO_ 1330 1;
BA_ "GenMsgSendType" BO_ 1330 3;
BA_ "GenMsgCycleTime" BO_ 1538 0;
BA_ "DiagResponse" BO_ 1538 1;
BA_ "GenMsgSendType" BO_ 1538 3;
BA_ "VFrameFormat" BO_ 1538 14;
BA_ "DoIPLogicalAddress" BO_ 1538 "0x0682";
BA_ "GenMsgCycleTime" BO_ 1568 0;
BA_ "DiagResponse" BO_ 1568 1;
BA_ "GenMsgSendType" BO_ 1568 3;
BA_ "VFrameFormat" BO_ 1568 14;
BA_ "DoIPLogicalAddress" BO_ 1568 "0x06A0";
BA_ "GenMsgCycleTime" BO_ 1586 0;
BA_ "DiagResponse" BO_ 1586 1;
BA_ "GenMsgSendType" BO_ 1586 3;
BA_ "VFrameFormat" BO_ 1586 14;
BA_ "DoIPLogicalAddress" BO_ 1586 "0x06B2";
BA_ "VFrameFormat" BO_ 796 14;
BA_ "GenMsgNrOfRepetition" BO_ 385 1;
BA_ "DataID_Hex" BO_ 385 63901;
BA_ "DataID" BO_ 385 "0xF99D";
BA_ "GenMsgCycleTimeFast" BO_ 385 10;
BA_ "GenMsgSendType" BO_ 385 5;
BA_ "VFrameFormat" BO_ 385 14;
BA_ "GenMsgNrOfRepetition" BO_ 496 1;
BA_ "GenMsgCycleTimeFast" BO_ 496 2;
BA_ "GenMsgSendType" BO_ 496 5;
BA_ "VFrameFormat" BO_ 496 14;
BA_ "DataID_Hex" BO_ 340 63729;
BA_ "GenMsgCycleTime" BO_ 340 10;
BA_ "DataID" BO_ 340 "0xF8F1";
BA_ "VFrameFormat" BO_ 340 14;
BA_ "GenSigSendType" SG_ 856 DSEAT_Error_Sta 3;
BA_ "GenSigSendType" SG_ 856 DSEAT_EntryFun_Sta 3;
BA_ "GenSigSendType" SG_ 856 DSEAT_EntryAct_Sta 3;
BA_ "GenSigSendType" SG_ 856 DSEAT_Anti_Sta 3;
BA_ "GenSigSendType" SG_ 856 DSEAT_AntiAct_Sta 3;
BA_ "GenSigSendType" SG_ 856 DSEAT_Vent_Sta 3;
BA_ "GenSigSendType" SG_ 884 Req_V2LSwOn 3;
BA_ "GenSigSendType" SG_ 884 Req_V2L_IVI_Popup 3;
BA_ "GenSigInvalidValue" SG_ 886 ChrgCurType 3;
BA_ "GenSigSendType" SG_ 886 ChrgCurType 3;
BA_ "GenSigSendType" SG_ 886 HVBattErr 3;
BA_ "GenSigSendType" SG_ 886 FireDetErr 3;
BA_ "GenSigSendType" SG_ 886 ChrgLampSta 3;
BA_ "GenSigSendType" SG_ 960 VehMalfunLevel 3;
BA_ "GenSigSendType" SG_ 960 EVDriveMode 3;
BA_ "GenSigSendType" SG_ 960 Eng_AGSCloseSta 3;
BA_ "GenSigInvalidValue" SG_ 960 Eng_PwrLockSta 2;
BA_ "GenSigSendType" SG_ 960 Eng_PwrLockSta 3;
BA_ "GenSigInvalidValue" SG_ 960 Eng_CoastDwSta 2;
BA_ "GenSigSendType" SG_ 960 Eng_CoastDwSta 3;
BA_ "GenSigInvalidValue" SG_ 960 Eng_ActvDmpDisabSta 2;
BA_ "GenSigSendType" SG_ 960 Eng_ActvDmpDisabSta 3;
BA_ "GenSigSendType" SG_ 960 VCU_ACCErr 3;
BA_ "GenSigSendType" SG_ 960 VCU_ISAErr 3;
BA_ "GenSigSendType" SG_ 960 ZoneDR_SCP_CommErr 3;
BA_ "GenSigInvalidValue" SG_ 992 HVBCellVoltMax 65535;
BA_ "GenSigInvalidValue" SG_ 992 HVBCellVoltMin 65535;
BA_ "GenSigInvalidValue" SG_ 992 CellTempAvg 255;
BA_ "GenSigStartValue" SG_ 992 CellTempAvg 40;
BA_ "GenSigInvalidValue" SG_ 992 MaxCellVolt_Num 255;
BA_ "GenSigInvalidValue" SG_ 992 MinCellVolt_Num 255;
BA_ "GenSigInvalidValue" SG_ 992 MaxCellTemp_Num 255;
BA_ "GenSigInvalidValue" SG_ 992 MinCellTemp_Num 255;
BA_ "GenSigInvalidValue" SG_ 992 HVBMTempMax 255;
BA_ "GenSigStartValue" SG_ 992 HVBMTempMax 40;
BA_ "GenSigInvalidValue" SG_ 992 HVBMTempMin 255;
BA_ "GenSigStartValue" SG_ 992 HVBMTempMin 40;
BA_ "GenSigInvalidValue" SG_ 992 Mtemp16 255;
BA_ "GenSigInvalidValue" SG_ 992 Mtemp17 255;
BA_ "GenSigInvalidValue" SG_ 992 Mtemp18 255;
BA_ "GenSigInvalidValue" SG_ 992 Mtemp19 255;
BA_ "GenSigInvalidValue" SG_ 992 Mtemp20 255;
BA_ "GenSigInvalidValue" SG_ 992 Mtemp01 255;
BA_ "GenSigInvalidValue" SG_ 992 Mtemp02 255;
BA_ "GenSigInvalidValue" SG_ 992 Mtemp03 255;
BA_ "GenSigInvalidValue" SG_ 992 Mtemp04 255;
BA_ "GenSigInvalidValue" SG_ 992 Mtemp05 255;
BA_ "GenSigInvalidValue" SG_ 992 Mtemp06 255;
BA_ "GenSigInvalidValue" SG_ 992 Mtemp07 255;
BA_ "GenSigInvalidValue" SG_ 992 Mtemp08 255;
BA_ "GenSigInvalidValue" SG_ 992 Mtemp09 255;
BA_ "GenSigInvalidValue" SG_ 992 Mtemp10 255;
BA_ "GenSigInvalidValue" SG_ 992 Mtemp11 255;
BA_ "GenSigInvalidValue" SG_ 992 Mtemp12 255;
BA_ "GenSigInvalidValue" SG_ 992 Mtemp13 255;
BA_ "GenSigInvalidValue" SG_ 992 Mtemp14 255;
BA_ "GenSigInvalidValue" SG_ 992 Mtemp15 255;
BA_ "GenSigSendType" SG_ 1077 LRWheelPSW 3;
BA_ "GenSigSendType" SG_ 1077 LFWheelPSW 3;
BA_ "GenSigSendType" SG_ 1077 RFWheelPSW 3;
BA_ "GenSigSendType" SG_ 1077 RRWheelPSW 3;
BA_ "GenSigSendType" SG_ 1077 RFPressIndi 3;
BA_ "GenSigSendType" SG_ 1077 LFPressIndi 3;
BA_ "GenSigInvalidValue" SG_ 1077 RRPressIndi 3;
BA_ "GenSigSendType" SG_ 1077 RRPressIndi 3;
BA_ "GenSigSendType" SG_ 1077 LRPressIndi 3;
BA_ "GenSigSendType" SG_ 1077 RFWheelTmpIndi 3;
BA_ "GenSigSendType" SG_ 1077 LFWheelTmpIndi 3;
BA_ "GenSigSendType" SG_ 1077 RRWheelTmpIndi 3;
BA_ "GenSigSendType" SG_ 1077 LRWheelTmpIndi 3;
BA_ "GenSigSendType" SG_ 1077 RFSensorFail 3;
BA_ "GenSigSendType" SG_ 1077 LFSensorFail 3;
BA_ "GenSigSendType" SG_ 1077 RRSensorFail 3;
BA_ "GenSigSendType" SG_ 1077 LRSensorFail 3;
BA_ "GenSigSendType" SG_ 1077 RFBatWarn 3;
BA_ "GenSigSendType" SG_ 1077 LFBatWarn 3;
BA_ "GenSigSendType" SG_ 1077 RRBatWarn 3;
BA_ "GenSigSendType" SG_ 1077 LRBatWarn 3;
BA_ "GenSigSendType" SG_ 1077 RFWheelDebug 3;
BA_ "GenSigSendType" SG_ 1077 LFWheelDebug 3;
BA_ "GenSigSendType" SG_ 1077 RRWheelDebug 3;
BA_ "GenSigSendType" SG_ 1077 LRWheelDebug 3;
BA_ "GenSigSendType" SG_ 1077 RFWheelPress 3;
BA_ "GenSigSendType" SG_ 1077 LFWheelPress 3;
BA_ "GenSigSendType" SG_ 1077 RRWheelPress 3;
BA_ "GenSigSendType" SG_ 1077 LRWheelPress 3;
BA_ "GenSigInvalidValue" SG_ 1077 RFWheelTemp 255;
BA_ "GenSigSendType" SG_ 1077 RFWheelTemp 3;
BA_ "GenSigInvalidValue" SG_ 1077 LFWheelTemp 255;
BA_ "GenSigSendType" SG_ 1077 LFWheelTemp 3;
BA_ "GenSigInvalidValue" SG_ 1077 RRWheelTemp 255;
BA_ "GenSigSendType" SG_ 1077 RRWheelTemp 3;
BA_ "GenSigInvalidValue" SG_ 1077 LRWheelTemp 255;
BA_ "GenSigSendType" SG_ 1077 LRWheelTemp 3;
BA_ "GenSigSendType" SG_ 1077 AutoLTips 3;
BA_ "GenSigInvalidValue" SG_ 1077 CWheelTips 3;
BA_ "GenSigSendType" SG_ 1077 CWheelTips 3;
BA_ "GenSigSendType" SG_ 1077 TPMS_Cali_Butt_Allow 3;
BA_ "GenSigSendType" SG_ 1077 TPMS_Res_Butt_Allow 3;
BA_ "GenSigSendType" SG_ 1077 TPMSWarnIndi 3;
BA_ "GenSigSendType" SG_ 1077 RRSensorMode 3;
BA_ "GenSigSendType" SG_ 1077 LRSensorMode 3;
BA_ "GenSigSendType" SG_ 1077 RFSensorMode 3;
BA_ "GenSigSendType" SG_ 1077 LFSensorMode 3;
BA_ "GenSigSendType" SG_ 1078 ID1_ALTU 3;
BA_ "GenSigSendType" SG_ 1078 ID2_ALTU 3;
BA_ "GenSigSendType" SG_ 1078 ID3_ALTU 3;
BA_ "GenSigSendType" SG_ 1078 ID4_ALTU 3;
BA_ "GenSigSendType" SG_ 1078 IDin_ALTU 3;
BA_ "GenSigSendType" SG_ 1078 ID1_Loc_ALTU 3;
BA_ "GenSigSendType" SG_ 1078 ID2_Loc_ALTU 3;
BA_ "GenSigSendType" SG_ 1078 ID3_Loc_ALTU 3;
BA_ "GenSigSendType" SG_ 1078 ID4_Loc_ALTU 3;
BA_ "GenSigSendType" SG_ 1078 RF_FAT_ALTU 3;
BA_ "GenSigSendType" SG_ 1078 ID1_message_ALTU 3;
BA_ "GenSigSendType" SG_ 1078 ID2_message_ALTU 3;
BA_ "GenSigSendType" SG_ 1078 ID3_message_ALTU 3;
BA_ "GenSigSendType" SG_ 1078 ID4_message_ALTU 3;
BA_ "GenSigSendType" SG_ 1078 S1WheelDebug_ALTU 3;
BA_ "GenSigSendType" SG_ 1078 S2WheelDebug_ALTU 3;
BA_ "GenSigSendType" SG_ 1078 S3WheelDebug_ALTU 3;
BA_ "GenSigSendType" SG_ 1078 S4WheelDebug_ALTU 3;
BA_ "GenSigInvalidValue" SG_ 1080 OTA_Up_Backcount 122;
BA_ "GenSigSendType" SG_ 1080 OTA_Up_Backcount 3;
BA_ "GenSigSendType" SG_ 1080 OTA_DL_Speed 3;
BA_ "GenSigSendType" SG_ 1080 OTA_Lock_Req 3;
BA_ "GenSigInvalidValue" SG_ 1080 OTA_Updating_ECU 30;
BA_ "GenSigSendType" SG_ 1080 OTA_Updating_ECU 3;
BA_ "GenSigSendType" SG_ 1080 OTA_Update_Available 3;
BA_ "GenSigSendType" SG_ 1080 OTA_InVehicle_FW 3;
BA_ "GenSigSendType" SG_ 1080 OTA_DL_Available 3;
BA_ "GenSigSendType" SG_ 1080 OTA_Mode 3;
BA_ "GenSigSendType" SG_ 1080 OTA_Network_Type 3;
BA_ "GenSigSendType" SG_ 1080 OTA_MDA_Status 3;
BA_ "GenSigInvalidValue" SG_ 1080 OTA_Progress_Rate 102;
BA_ "GenSigSendType" SG_ 1080 OTA_Progress_Rate 3;
BA_ "GenSigInvalidValue" SG_ 1080 OTA_Remained_Time 1082;
BA_ "GenSigInvalidValue" SG_ 1080 OTA_Updating_ECU_8bit 30;
BA_ "GenSigSendType" SG_ 1080 OTA_Updating_ECU_8bit 3;
BA_ "GenSigInvalidValue" SG_ 1249 Charge_Percent_Set 101;
BA_ "GenSigStartValue" SG_ 1249 Charge_Percent_Set 100;
BA_ "GenSigSendType" SG_ 1249 Charge_Percent_Set 3;
BA_ "GenSigSendType" SG_ 1280 NM_FUSION_ERROR_State 7;
BA_ "GenSigSendType" SG_ 1280 NM_FUSION_Rpt_Msg_Req 7;
BA_ "GenSigSendType" SG_ 1280 NM_FUSION_CSB 7;
BA_ "GenSigSendType" SG_ 1280 NM_FUSION_Active_WU 7;
BA_ "GenSigSendType" SG_ 1280 NM_FUSION_PNI 7;
BA_ "GenSigSendType" SG_ 1280 NM_FUSION_Node_ID 7;
BA_ "GenSigSendType" SG_ 1666 DiagPhysReqToTelltale 3;
BA_ "GenSigSendType" SG_ 1696 DiagPhysReqToIVI 3;
BA_ "GenSigSendType" SG_ 1714 DiagPhysReqToHMI 3;
BA_ "GenSigSendType" SG_ 2000 DiagFuncReqFT 3;
BA_ "GenSigSendType" SG_ 593 P_KeyMode 3;
BA_ "GenSigInvalidValue" SG_ 593 P_CommandToPTG 5;
BA_ "GenSigSendType" SG_ 593 DKC_Re_VehData 3;
BA_ "GenSigSendType" SG_ 593 P_UID_LowPower 3;
BA_ "GenSigInvalidValue" SG_ 342 LF_RawWhlSpeed_V 1;
BA_ "GenSigInvalidValue" SG_ 342 LF_PulseCount_V 1;
BA_ "GenSigInvalidValue" SG_ 342 RF_RawWhlSpeed_V 1;
BA_ "GenSigInvalidValue" SG_ 342 RF_PulseCount_V 1;
BA_ "GenSigInvalidValue" SG_ 343 LR_RawWhlSpeed_V 1;
BA_ "GenSigInvalidValue" SG_ 343 LR_PulseCount_V 1;
BA_ "GenSigInvalidValue" SG_ 343 RR_RawWhlSpeed_V 1;
BA_ "GenSigInvalidValue" SG_ 343 RR_PulseCount_V 1;
BA_ "GenSigSendType" SG_ 602 ODOMETER 3;
BA_ "GenSigSendType" SG_ 602 Trip_A 3;
BA_ "GenSigSendType" SG_ 602 Trip_B 3;
BA_ "GenSigSendType" SG_ 602 ParkBrake 3;
BA_ "GenSigSendType" SG_ 602 Charge 3;
BA_ "GenSigSendType" SG_ 602 LEDlitWarnReq 3;
BA_ "GenSigInvalidValue" SG_ 602 Spd_Crl_Mode 5;
BA_ "GenSigInvalidValue" SG_ 602 AvailableTrip 65535;
BA_ "GenSigInvalidValue" SG_ 602 APCforDTE 65535;
BA_ "GenSigStartValue" SG_ 602 APCforDTE 9999;
BA_ "GenSigInvalidValue" SG_ 602 AVGPwrConsumption 65535;
BA_ "GenSigStartValue" SG_ 602 AVGPwrConsumption 9999;
BA_ "GenSigInvalidValue" SG_ 602 Averaged_vehspeed 1023;
BA_ "GenSigInvalidValue" SG_ 602 METER_MPH_Real 4095;
BA_ "GenSigInvalidValue" SG_ 602 METER_KPH_Real 4095;
BA_ "GenSigInvalidValue" SG_ 602 METER_MPH_Calcu 255;
BA_ "GenSigInvalidValue" SG_ 602 METER_KPH_Calcu 255;
BA_ "GenSigSendType" SG_ 1168 DRAmbLightBrightnessSet 3;
BA_ "GenSigSendType" SG_ 1168 AmbLightUserSet 3;
BA_ "GenSigSendType" SG_ 1168 IPAmbLightBrightnessSet 3;
BA_ "GenSigSendType" SG_ 1168 Sched_OTA_wake 3;
BA_ "GenSigSendType" SG_ 1168 AmbLightColorSet 3;
BA_ "GenSigSendType" SG_ 1168 Upd_Countdown_Cancel 3;
BA_ "GenSigSendType" SG_ 1168 Upd_Countdown_Skip 3;
BA_ "GenSigSendType" SG_ 1168 LINKtoDrive 3;
BA_ "GenSigSendType" SG_ 1168 OTA_CompNTFY_Pres 3;
BA_ "GenSigSendType" SG_ 1168 OTA_CancelDL_Req 3;
BA_ "GenSigSendType" SG_ 1168 IVI_OTA_Upd_Sta 3;
BA_ "GenSigSendType" SG_ 1168 OTA_UpdStart_Req 3;
BA_ "GenSigSendType" SG_ 1168 OTA_SuspendDL_Req 3;
BA_ "GenSigSendType" SG_ 1168 OTA_DL_Req 3;
BA_ "GenSigSendType" SG_ 1168 FCP_FrEvt_BtnSyncReq 3;
BA_ "GenSigSendType" SG_ 1168 FCP_MidEvt_BtnAutoReq 3;
BA_ "GenSigSendType" SG_ 1168 FCP_FrEvt_BtnAutoReq 3;
BA_ "GenSigSendType" SG_ 1168 FCP_FrEvt_BtnACReq 3;
BA_ "GenSigSendType" SG_ 1168 FCP_FrEvt_BtnACMaxReq 3;
BA_ "GenSigSendType" SG_ 1168 VehACModReq 3;
BA_ "GenSigSendType" SG_ 1168 PW_CONTINUE_USE 3;
BA_ "GenSigSendType" SG_ 1168 PW_CLOSE_IMD 3;
BA_ "GenSigSendType" SG_ 1168 SmartEco_Mode_SW 3;
BA_ "GenSigSendType" SG_ 1168 BrkAbn_GoReady_SW 3;
BA_ "GenSigSendType" SG_ 1168 OpenDrOpenWdo_SW 3;
BA_ "GenSigSendType" SG_ 1168 IVI_Lock_SoundSW_Sta 3;
BA_ "GenSigSendType" SG_ 1173 AVM_parking_cancel 3;
BA_ "GenSigSendType" SG_ 1173 AVM_parking_excute 3;
BA_ "GenSigSendType" SG_ 1173 AVM_OFF_Rec_Butt 3;
BA_ "GenSigInvalidValue" SG_ 1173 IVI_AGSCloseSW 2;
BA_ "GenSigSendType" SG_ 1173 IVI_AGSCloseSW 3;
BA_ "GenSigInvalidValue" SG_ 1173 IVI_LVChrgFuncSW 2;
BA_ "GenSigSendType" SG_ 1173 IVI_LVChrgFuncSW 3;
BA_ "GenSigInvalidValue" SG_ 1173 IVI_PwrLockSW 2;
BA_ "GenSigSendType" SG_ 1173 IVI_PwrLockSW 3;
BA_ "GenSigInvalidValue" SG_ 1173 IVI_CoastDwSW 2;
BA_ "GenSigSendType" SG_ 1173 IVI_CoastDwSW 3;
BA_ "GenSigInvalidValue" SG_ 1173 IVI_ActvDmpDisabSW 2;
BA_ "GenSigSendType" SG_ 1173 IVI_ActvDmpDisabSW 3;
BA_ "GenSigInvalidValue" SG_ 1173 Roll_Mode_SW_Cmd 3;
BA_ "GenSigSendType" SG_ 1173 Roll_Mode_SW_Cmd 3;
BA_ "GenSigInvalidValue" SG_ 1173 TCS_SW_Cmd 3;
BA_ "GenSigSendType" SG_ 1173 TCS_SW_Cmd 3;
BA_ "GenSigInvalidValue" SG_ 1173 SLIF_BUTT 3;
BA_ "GenSigSendType" SG_ 1173 SLIF_BUTT 3;
BA_ "GenSigSendType" SG_ 1173 Roll_Eng_Mode 3;
BA_ "GenSigInvalidValue" SG_ 1173 SOC_Limit_Set 31;
BA_ "GenSigStartValue" SG_ 1173 SOC_Limit_Set 25;
BA_ "GenSigSendType" SG_ 1173 CDL_Lock_Butt 3;
BA_ "GenSigSendType" SG_ 1173 CDL_Unlock_Butt 3;
BA_ "GenSigSendType" SG_ 1173 SOC_ADJ_BUTT 3;
BA_ "GenSigSendType" SG_ 1173 AC_Chg_Cur_Set 3;
BA_ "GenSigInvalidValue" SG_ 1173 IVI_ISA_OffsetSpd 15;
BA_ "GenSigSendType" SG_ 1173 IVI_RR_Def_Req 3;
BA_ "GenSigInvalidValue" SG_ 1173 CAAS_Sw 2;
BA_ "GenSigSendType" SG_ 1173 CAAS_Sw 3;
BA_ "GenSigSendType" SG_ 1173 IVI_PTG_Mode_SW 3;
BA_ "GenSigSendType" SG_ 1173 IVI_PTG_Sta_SW 3;
BA_ "GenSigInvalidValue" SG_ 1173 MFRD_N_Bright_Req 127;
BA_ "GenSigSendType" SG_ 1173 MFRD_N_Bright_Req 3;
BA_ "GenSigSendType" SG_ 1173 HeadLampSW 3;
BA_ "GenSigInvalidValue" SG_ 1173 OFF_AC_MODE 7;
BA_ "GenSigSendType" SG_ 1173 OFF_AC_MODE 3;
BA_ "GenSigSendType" SG_ 1173 TurnSwTimeSet 3;
BA_ "GenSigSendType" SG_ 1173 ESC_SW_Cmd 3;
BA_ "GenSigSendType" SG_ 1173 sigHvacRearReq 3;
BA_ "GenSigStartValue" SG_ 1173 sigWindDirZon3Req 7;
BA_ "GenSigSendType" SG_ 1173 sigWindDirZon3Req 3;
BA_ "GenSigSendType" SG_ 1173 sigAirIntenZon3Req 3;
BA_ "GenSigSendType" SG_ 1173 sigAirIntenZon1Req 3;
BA_ "GenSigSendType" SG_ 1173 sigSetTempZon3Req 3;
BA_ "GenSigSendType" SG_ 1173 sigSetTempZon2Req 3;
BA_ "GenSigSendType" SG_ 1173 sigRecircReq 3;
BA_ "GenSigSendType" SG_ 1173 sigHvacReq 3;
BA_ "GenSigSendType" SG_ 1173 sigSetTempZon1Req 3;
BA_ "GenSigSendType" SG_ 1173 sigHvacFrontReq 3;
BA_ "GenSigSendType" SG_ 1173 sigDfrstReq 3;
BA_ "GenSigStartValue" SG_ 1173 L_Drv_ControlCommand 127;
BA_ "GenSigRoutingTimeoutValue" SG_ 1173 L_Drv_ControlCommand 127;
BA_ "GenSigStartValue" SG_ 1173 L_Pas_ControlCommand 127;
BA_ "GenSigRoutingTimeoutValue" SG_ 1173 L_Pas_ControlCommand 127;
BA_ "GenSigStartValue" SG_ 1173 L_RLD_ControlCommand 127;
BA_ "GenSigRoutingTimeoutValue" SG_ 1173 L_RLD_ControlCommand 127;
BA_ "GenSigStartValue" SG_ 1173 L_RRD_ControlCommand 127;
BA_ "GenSigRoutingTimeoutValue" SG_ 1173 L_RRD_ControlCommand 127;
BA_ "GenSigInvalidValue" SG_ 1173 METER_Malfunc_Sta 3;
BA_ "GenSigSendType" SG_ 1173 sigFootReq 3;
BA_ "GenSigSendType" SG_ 1173 sigFaceReq 3;
BA_ "GenSigSendType" SG_ 1173 Sched_Chg_Start 3;
BA_ "GenSigSendType" SG_ 1173 Sched_Chg_wake 3;
BA_ "GenSigSendType" SG_ 1173 Sched_Chg_Stop 3;
BA_ "GenSigInvalidValue" SG_ 1173 Sched_Chg_limit 31;
BA_ "GenSigStartValue" SG_ 1173 Sched_Chg_limit 25;
BA_ "GenSigStartValue" SG_ 1173 Walkaway_Lock_SW 1;
BA_ "GenSigSendType" SG_ 1173 Walkaway_Lock_SW 3;
BA_ "GenSigStartValue" SG_ 1173 Approach_Unlock_SW 1;
BA_ "GenSigSendType" SG_ 1173 Approach_Unlock_SW 3;
BA_ "GenSigStartValue" SG_ 1173 FalseNPrevent_SW 1;
BA_ "GenSigSendType" SG_ 1173 IVI_CreepSW_Req 3;
BA_ "GenSigSendType" SG_ 1173 IVI_PTG_Open_Height 3;
BA_ "GenSigInvalidValue" SG_ 1173 SOC_V2LLimit 15;
BA_ "GenSigInvalidValue" SG_ 1179 Sched_Chg_End_Time_HR 31;
BA_ "GenSigSendType" SG_ 1179 Sched_Chg_End_Time_HR 3;
BA_ "GenSigInvalidValue" SG_ 1179 Sched_Chg_St_Time_HR 31;
BA_ "GenSigSendType" SG_ 1179 Sched_Chg_St_Time_HR 3;
BA_ "GenSigSendType" SG_ 1179 Sched_Chg_End_Time_Min 3;
BA_ "GenSigSendType" SG_ 1179 Sched_Chg_St_Time_Min 3;
BA_ "GenSigSendType" SG_ 1179 Sched_Chg_Day_Set 3;
BA_ "GenSigSendType" SG_ 1282 NM_Telltale_ERROR_State 7;
BA_ "GenSigSendType" SG_ 1282 NM_Telltale_Rpt_Msg_Req 7;
BA_ "GenSigSendType" SG_ 1282 NM_Telltale_CSB 7;
BA_ "GenSigSendType" SG_ 1282 NM_Telltale_Active_WU 7;
BA_ "GenSigSendType" SG_ 1282 NM_Telltale_PNI 7;
BA_ "GenSigSendType" SG_ 1282 NM_Telltale_Node_ID 7;
BA_ "GenSigSendType" SG_ 1312 NM_IVI_ERROR_State 7;
BA_ "GenSigSendType" SG_ 1312 NM_IVI_Rpt_Msg_Req 7;
BA_ "GenSigSendType" SG_ 1312 NM_IVI_CSB 7;
BA_ "GenSigSendType" SG_ 1312 NM_IVI_Active_WU 7;
BA_ "GenSigSendType" SG_ 1312 NM_IVI_PNI 7;
BA_ "GenSigSendType" SG_ 1312 NM_IVI_Node_ID 7;
BA_ "GenSigSendType" SG_ 1330 NM_HMI_ERROR_State 7;
BA_ "GenSigSendType" SG_ 1330 NM_HMI_Rpt_Msg_Req 7;
BA_ "GenSigSendType" SG_ 1330 NM_HMI_CSB 7;
BA_ "GenSigSendType" SG_ 1330 NM_HMI_Active_WU 7;
BA_ "GenSigSendType" SG_ 1330 NM_HMI_PNI 7;
BA_ "GenSigSendType" SG_ 1330 NM_HMI_Node_ID 7;
BA_ "GenSigSendType" SG_ 1538 DiagRespFromTelltale 3;
BA_ "GenSigSendType" SG_ 1568 DiagRespFromIVI 3;
BA_ "GenSigSendType" SG_ 1586 DiagRespFromHMI 3;
BA_ "GenSigInvalidValue" SG_ 796 COMP_ActualPwr 8191;
BA_ "GenSigInvalidValue" SG_ 385 Shifter_Handle_Cmd 255;
BA_ "GenSigSendType" SG_ 385 Shifter_Handle_Cmd 3;
BA_ "GenSigSendType" SG_ 385 Shifter_RC 3;
BA_ "GenSigSendType" SG_ 385 Shifter_CRC8 3;
BA_ "GenSigSendType" SG_ 385 Shifter_Fail_sta 3;
BA_ "GenSigSendType" SG_ 496 SysPwrSta 3;
BA_ "GenSigSendType" SG_ 496 PowerUpState 3;
BA_ "GenSigSendType" SG_ 496 PowerUpFault 3;
BA_ "GenSigSendType" SG_ 496 PowerDownState 3;
BA_ "GenSigSendType" SG_ 496 PowerDownFault 3;
BA_ "GenSigSendType" SG_ 496 PwrStaSelect 3;
BA_ "GenSigSendType" SG_ 496 PwrStaConstraint 3;
BA_ "GenSigSendType" SG_ 496 TCountSta 3;
BA_ "GenSigSendType" SG_ 496 PwrUpReq 3;
BA_ "GenSigSendType" SG_ 496 PwrDownReq 3;
BA_ "GenSigSendType" SG_ 496 Rr_TqSource 3;
BA_ "GenSigSendType" SG_ 496 Fr_TqSource 3;
BA_ "GenSigSendType" SG_ 496 LVBattVoltSta 3;
BA_ "GenSigSendType" SG_ 496 HVTHCMSysAvail 3;
BA_ "GenSigSendType" SG_ 496 VehHVPwrAvail4THCM 3;
BA_ "GenSigSendType" SG_ 496 VCUBrkSWSta 3;
BA_ "GenSigSendType" SG_ 496 VCUFLDoorSta 3;
BA_ "GenSigSendType" SG_ 496 VCUFRDoorSta 3;
BA_ "GenSigSendType" SG_ 496 VCURLDoorSta 3;
BA_ "GenSigSendType" SG_ 496 VCURRDoorSta 3;
BA_ "GenSigSendType" SG_ 496 SysAllowReadySta 3;
BA_ "GenSigSendType" SG_ 496 HVRlyOpFail 3;
BA_ "GenSigSendType" SG_ 496 MCUActDisFail 3;
BA_ "GenSigSendType" SG_ 496 PwrStaONTOIVIPopReq 3;
BA_ "GenSigSendType" SG_ 496 PwrStaTOSta 3;
BA_ "GenSigSendType" SG_ 496 PwrStaONTOIVIPopT 3;
BA_ "GenSigSendType" SG_ 496 SchedChgTOSta 3;
BA_ "GenSigSendType" SG_ 496 SilentChkAllowSleep 3;
BA_ "GenSigSendType" SG_ 496 LVSilentChrgSta 3;
BA_ "GenSigSendType" SG_ 496 LVSilentChrgLv 3;
BA_ "GenSigSendType" SG_ 496 LVSilentChrgReq 3;
BA_ "GenSigSendType" SG_ 496 TimerAllowSleep 3;
BA_ "GenSigSendType" SG_ 496 PMMAllowECUSleep 3;
BA_ "GenSigSendType" SG_ 496 LVChrgHoldTAct 3;
BA_ "GenSigSendType" SG_ 496 LVBattChrgtimeAct 3;
BA_ "GenSigSendType" SG_ 496 EVCCAplusPwrUpReq 3;
BA_ "GenSigSendType" SG_ 496 FDADC12VDetAvg 3;
BA_ "GenSigSendType" SG_ 496 VCUHoodSWSta 3;
BA_ "GenSigSendType" SG_ 496 VCUTailgateSWSta 3;
BA_ "GenSigStartValue" SG_ 340 DriverTq 4300;
BA_ "GenSigStartValue" SG_ 340 VehActPwr 600000;
BA_ "GenSigStartValue" SG_ 340 Rr_DriverTq 10600;
BA_ "GenSigStartValue" SG_ 340 Fr_DriverTq 10600;
VAL_ 856 DSEAT_Error_Sta 1 "Warning Request(IVI POP UP)" 0 "Normal";
VAL_ 856 DSEAT_EntryFun_Sta 1 "on" 0 "off";
VAL_ 856 DSEAT_EntryAct_Sta 1 "Entry Function is activate" 0 "Entry Function is deactivate,";
VAL_ 856 DSEAT_Anti_Sta 1 "on" 0 "off";
VAL_ 856 DSEAT_AntiAct_Sta 1 "Antitheft is activate" 0 "Antitheft is deactivate";
VAL_ 856 DSEAT_Vent_Sta 4 "OFF" 3 "3(High)" 2 "2(Middle)" 1 "1(Low)" 0 "No Request";
VAL_ 856 DSEAT_Mode 7 "manual & heater & ventilate" 6 "manual & ventilate" 5 "manual & heater" 4 "power & heater & ventilate" 3 "power & ventilate" 2 "power & heater" 1 "power" 0 "manual";
VAL_ 881 PTG_HW_Ver 31 "V31" 1 "V1" 0 "Invalid";
VAL_ 881 PTG_SW_Ver 31 "V31" 1 "V1" 0 "Invalid";
VAL_ 881 PTG_Is_Set_Height 1 "On" 0 "Off";
VAL_ 881 PTG_AutoStaus 1 "Auto mode" 0 "Manual mode";
VAL_ 881 PTG_Exist 1 "Exist" 0 "Not Exist";
VAL_ 881 PTG_RDIL_Sta 3 "Invalid" 2 "Flash 3 times" 1 "Flash twice" 0 "No request";
VAL_ 881 PTG_Inner_SW_1 3 "Stuck" 2 "Press&Hold" 1 "Push" 0 "Off";
VAL_ 881 PTG_Sys_Sta 3 "Invalid" 2 "Abnormality" 1 "Normal" 0 "Initializing";
VAL_ 881 PTG_Full_Lock 1 "On" 0 "Off";
VAL_ 881 PTG_Active_Sta 7 "Pinch Reverse" 6 "Hold" 5 "Pause" 4 "Auto Closing" 3 "Auto Opening" 2 "Idle Full Open" 1 "Idle Full Close" 0 "Invalid";
VAL_ 881 PTG_Warning_Sta 7 "Reserved" 6 "User Operation Denied" 5 "User Operation Accepted" 4 "Memory position" 3 "Warning" 2 "Forced stop" 1 "Antipinch reverse" 0 "Off";
VAL_ 881 PTG_Half_Lock 1 "On" 0 "Off";
VAL_ 881 PTG_Open_Ratio 127 "127% (Invalid)" 100 "100% (Max)" 0 "0% (Min)";
VAL_ 884 Req_V2LSwOn 1 "Request for V2L plug switch on" 0 "Not request for V2L plug switch on";
VAL_ 884 Req_OBCV2LEna 2 "Internal V2L discharge" 1 "External V2L discharge" 0 "Not request for V2L discharge";
VAL_ 884 Req_V2L_IVI_Popup 6 "Request IVI popup 'V2L Fault'" 5 "Request IVI popup 'V2L Time up'" 4 "Request IVI popup 'SOC is too low'" 3 "Request IVI popup 'Stop by V2L SOC Set'" 2 "Request IVI popup 'V2L plug-in and V2L SW off'" 1 "Request IVI popup 'Check V2L Plug'" 0 "Not request";
VAL_ 886 ChrgCurType 3 "BC" 2 "DC" 1 "AC" 0 "None";
VAL_ 886 HVBattErr 1 "Battery Error" 0 "None";
VAL_ 886 FireDetErr 1 "Fault" 0 "Normal";
VAL_ 886 ChrgLampSta 3 "Fault" 2 "Green light on" 1 "Red light on" 0 "No action";
VAL_ 917 PSEAT_Error_Sta 1 "Warning Request (IVI POP UP)" 0 "Normal";
VAL_ 917 PSEAT_Mode 7 "manual & heater & ventilate" 6 "manual & ventilate" 5 "manual & heater" 4 "power & heater & ventilate" 3 "power & ventilate" 2 "power & heater" 1 "power" 0 "manual";
VAL_ 917 PSEAT_Vent_Sta 4 "OFF" 3 "3(High)" 2 "2(Middle)" 1 "1(Low)" 0 "No Request";
VAL_ 960 VehMalfunLevel 5 "Invalid" 4 "4th grade malfunction" 3 "3rd grade malfunction" 2 "2nd grade malfunction" 1 "1st grade malfunction" 0 "Normal";
VAL_ 960 EVDriveMode 2 "Sport" 1 "Eco" 0 "Normal";
VAL_ 960 Eng_AGSCloseSta 1 "Closed" 0 "Auto";
VAL_ 960 Eng_PwrLockSta 2 "Invalid" 1 "Locked" 0 "Unlocked";
VAL_ 960 Eng_CoastDwSta 2 "Invalid" 1 "On" 0 "Off";
VAL_ 960 Eng_ActvDmpDisabSta 2 "Invalid" 1 "On" 0 "Off";
VAL_ 960 VCU_ACCErr 1 "Error" 0 "Normal";
VAL_ 960 VCU_ISAErr 1 "Error" 0 "Normal";
VAL_ 960 ZoneDR_SCP_CommErr 1 "Error" 0 "Normal";
VAL_ 1077 RFPressIndi 3 "invalid" 2 "pressure too low" 1 "pressure too high" 0 "Normal";
VAL_ 1077 LFPressIndi 3 "invalid" 2 "pressure too low" 1 "pressure too high" 0 "Normal";
VAL_ 1077 RRPressIndi 3 "invalid" 2 "pressure too low" 1 "pressure too high" 0 "Normal";
VAL_ 1077 LRPressIndi 3 "invalid" 2 "pressure too low" 1 "pressure too high" 0 "Normal";
VAL_ 1077 RFWheelTmpIndi 1 "overheated" 0 "Normal";
VAL_ 1077 LFWheelTmpIndi 1 "overheated" 0 "Normal";
VAL_ 1077 RRWheelTmpIndi 1 "overheated" 0 "Normal";
VAL_ 1077 LRWheelTmpIndi 1 "overheated" 0 "Normal";
VAL_ 1077 RFSensorFail 1 "Fail" 0 "Normal";
VAL_ 1077 LFSensorFail 1 "Fail" 0 "Normal";
VAL_ 1077 RRSensorFail 1 "Fail" 0 "Normal";
VAL_ 1077 LRSensorFail 1 "Fail" 0 "Normal";
VAL_ 1077 RFBatWarn 1 "Low" 0 "Normal";
VAL_ 1077 LFBatWarn 1 "Low" 0 "Normal";
VAL_ 1077 RRBatWarn 1 "Low" 0 "Normal";
VAL_ 1077 LRBatWarn 1 "Low" 0 "Normal";
VAL_ 1077 RFWheelDebug 1 "Receive" 0 "Normal";
VAL_ 1077 LFWheelDebug 1 "Receive" 0 "Normal";
VAL_ 1077 RRWheelDebug 1 "Receive" 0 "Normal";
VAL_ 1077 LRWheelDebug 1 "Receive" 0 "Normal";
VAL_ 1077 RFWheelPress 255 "Invalid" 250 "Max" 0 "Min";
VAL_ 1077 LFWheelPress 255 "Invalid" 250 "Max" 0 "Min";
VAL_ 1077 RRWheelPress 255 "Invalid" 250 "Max" 0 "Min";
VAL_ 1077 LRWheelPress 255 "Invalid" 250 "Max" 0 "Min";
VAL_ 1077 RFWheelTemp 255 "Invalid";
VAL_ 1077 LFWheelTemp 255 "Invalid";
VAL_ 1077 RRWheelTemp 255 "Invalid";
VAL_ 1077 LRWheelTemp 255 "Invalid";
VAL_ 1077 AutoLTips 3 "Invalid" 2 "Auto location failed" 1 "Auto location seccessful" 0 "Normal";
VAL_ 1077 CWheelTips 3 "invalid" 2 "Calibrate Wheel failed" 1 "Calibrate Wheel success" 0 "Normal";
VAL_ 1077 TPMS_Cali_Butt_Allow 1 "Allowable" 0 "Unallowable";
VAL_ 1077 TPMS_Res_Butt_Allow 1 "Allowable" 0 "Unallowable";
VAL_ 1077 TPMSWarnIndi 3 "Invalid" 2 "Indicator Flash" 1 "Indicator ON" 0 "Indicator OFF";
VAL_ 1077 RRSensorMode 1 "FAT Mode" 0 "Not FAT Mode";
VAL_ 1077 LRSensorMode 1 "FAT Mode" 0 "Not FAT Mode";
VAL_ 1077 RFSensorMode 1 "FAT Mode" 0 "Not FAT Mode";
VAL_ 1077 LFSensorMode 1 "FAT Mode" 0 "Not FAT Mode";
VAL_ 1078 ID1_Loc_ALTU 5 "Unlearned" 4 "Right Rear" 3 "Left Rear" 2 "Right Front" 1 "Left Front" 0 "Undefined";
VAL_ 1078 ID2_Loc_ALTU 5 "Unlearned" 4 "Right Rear" 3 "Left Rear" 2 "Right Front" 1 "Left Front" 0 "Undefined";
VAL_ 1078 ID3_Loc_ALTU 5 "Unlearned" 4 "Right Rear" 3 "Left Rear" 2 "Right Front" 1 "Left Front" 0 "Undefined";
VAL_ 1078 ID4_Loc_ALTU 5 "Unlearned" 4 "Right Rear" 3 "Left Rear" 2 "Right Front" 1 "Left Front" 0 "Undefined";
VAL_ 1078 RF_FAT_ALTU 1 "FAT" 0 "Normal";
VAL_ 1080 OTA_Up_Backcount 122 "Invalid" 121 "No action" 0 "~0x78 0s~120s";
VAL_ 1080 OTA_Lock_Req 1 "Lock Request" 0 "No action";
VAL_ 1080 OTA_Updating_ECU 30 "Invalid" 29 "HMI" 28 "W_PTC" 27 "EBM" 26 "AIRPTC" 25 "E_Compressor" 24 "Shifter" 23 "TELLTALE" 22 "MRR" 21 "SRR_M" 20 "FCM" 19 "EPS" 18 "EOP_F" 17 "EOP_R" 16 "MCU_F" 15 "MCU_R" 14 "eBST" 13 "ESC" 12 "APM" 11 "PSEAT" 10 "DSEAT" 9 "PTG" 8 "CCU" 7 "BMS" 6 "DKC" 5 "Zone_Dr" 4 "Zone_Fr" 3 "T-Box" 2 "IVI" 1 "FDC" 0 "No action";
VAL_ 1080 OTA_Update_Available 1 "Ready for Update" 0 "Not Ready";
VAL_ 1080 OTA_InVehicle_FW 2 "FW Need Update" 1 "FW Up to Date" 0 "Not Confirm";
VAL_ 1080 OTA_DL_Available 1 "Ready for Download" 0 "Not Ready";
VAL_ 1080 OTA_Mode 1 "OTA mode" 0 "Normal mode";
VAL_ 1080 OTA_Network_Type 3 "Undefine" 2 "WiFi" 1 "LTE" 0 "Network Not Available";
VAL_ 1080 OTA_MDA_Status 14 "Undefine" 13 "OTA Task Finished" 12 "Vehicle Update Complete" 11 "Update Failed" 10 "Download Failed" 9 "Countdown" 8 "Download Suspend" 7 "Vehicle Roll-Back" 6 "Vehicle Updating" 5 "Wait Update" 4 "Campaign Downloading" 3 "Wait Download" 2 "Ask Campaign" 1 "Ready" 0 "Not Ready";
VAL_ 1080 OTA_Progress_Rate 102 "Invalid" 101 "Not in progress" 100 "100%" 99 "99%" 0 "~0x64 0%~100%";
VAL_ 1080 OTA_Permit_Agreed 1 "Confirmed" 0 "Not Confirm";
VAL_ 1080 OTA_Remained_Time 1081 "No action" 1080 "10800 sec" 1079 "10790 sec" 2 "20 sec" 1 "10 sec" 0 "0 sec";
VAL_ 1080 OTA_Debug_Code 63 "Backend unreachable" 56 "ECU upgrade stuck" 40 "Invalid parameter" 55 "ECU invalid data" 54 "ECU timeout" 53 "ECU unreachable" 51 "Method not support" 50 "Unknown error" 65 "Backend invalid data" 64 "Backend timeout" 0 "Normal state";
VAL_ 1080 OTA_TBOXResetReq 1 "Request reset" 0 "No request";
VAL_ 1080 OTA_Updating_ECU_8bit 255 "Invalid" 34 "DKC_UWB3" 33 "DKC_UWB2" 32 "DKC_UWB1" 31 "DKC_NFC" 30 "DKC_BLE" 29 "HMI" 28 "W_PTC" 27 "EBM" 26 "AIRPTC" 25 "E_Compressor" 24 "Shifter" 23 "TELLTALE" 22 "MRR" 21 "SRR_M" 20 "FCM" 19 "EPS" 18 "EOP_F" 17 "EOP_R" 16 "MCU_F" 15 "MCU_R" 14 "eBST" 13 "ESC" 12 "ABM" 11 "PSEAT" 10 "DSEAT" 9 "PTG" 8 "CCU" 7 "BMS" 6 "DKC" 5 "Zone_Dr" 4 "Zone_Fr" 3 "T-Box" 2 "IVI" 1 "FDC" 0 "No action";
VAL_ 1090 PowerOff_T_Set 99 "100 min (max.)" 0 "1 min (min.)";
VAL_ 1090 Re_Radio 1 "Radio turn on" 0 "Radio turn off";
VAL_ 1090 TBOX_NET_SIG_STR 8 "wifi comes back" 7 "wifi leaves home" 6 "Error" 5 "no signal" 4 "4 bars" 3 "3 bars" 2 "2 bars" 1 "1 bar" 0 "Invalid";
VAL_ 1090 TBOX_TEST_STATUS 15 "Invalid" 8 "OTA updating" 7 "RS-232 Transceiver Failure" 6 "CAN Controller Failure" 5 "3G Module Failure" 4 "Flash Error" 3 "SIM Card Failed" 2 "ECU Internal Error" 1 "WM Self Test OK" 0 "WM Self Testing";
VAL_ 1090 ReOutsideMirror 3 "Undefined" 2 "Unfold" 1 "Fold" 0 "No Command";
VAL_ 1090 CbnPreReq 3 "Reserved" 2 "Estimated time required" 1 "Start preconditioning" 0 "Stop preconditioning";
VAL_ 1090 CbnPreACEnaReq 3 "Reserved" 2 "Not Set" 1 "Enable A/C" 0 "Disable A/C";
VAL_ 1090 Uncounting_Req 3 "Invalid" 2 "Reserved" 1 "Counting Stop" 0 "No action";
VAL_ 1090 TBOX_Remote_PW 16 "App 4Door AutoDown" 15 "App 4Door AutoUp" 14 "Stop" 13 "App RR" 12 "App RL ManualDown" 11 "App FR MaualDown" 10 "App FL ManualDown" 9 "App 4Door ManualDown" 8 "App RR AutoDown" 7 "App RR AutoUp" 6 "App RL AutoDown" 5 "App RL AutoUp" 4 "App FR AutoDown" 3 "App FR AutoUp" 2 "App FL AutoDown" 1 "App FL AutoUp" 0 "release";
VAL_ 1090 Re_PwrReqTbox 6 "Request for PowerOff" 5 "Request for ON" 4 "Request for Radio" 3 "Request for DTC" 2 "Request for ACTemp" 1 "Request for VehChk" 0 "No Request";
VAL_ 1090 TBOX_RemoteOn 2 "Reserved" 1 "Remote on" 0 "No Request";
VAL_ 1090 TBOX_Re_VehData 3 "the data upload is NG" 2 "the data upload is OK" 1 "Request" 0 "No Request";
VAL_ 1090 Antitheft_Zero 15 "Invalid" 10 "KSN/TP Learn Fail" 9 "KSN/TP Learn Pass" 8 "legal Key in In/Out(identical)" 7 "legal Key in In/Out(different)" 6 "legal Key in Indoor" 5 "legal Key in Outdoor" 4 "Forced to lift anti-theft" 3 "Tailgate Open/Close" 2 "Unlock" 1 "Lock" 0 "Default";
VAL_ 1090 Re_DoorLock 10 "outside mirror release" 9 "outside mirror fold" 8 "seek mute(flash)" 7 "Handle unlock" 6 "Unlock via BT" 5 "Lock via BT" 4 "PTG open via 4G" 3 "Seek(flash+honk)" 2 "Unlock via 4G" 1 "Lock via 4G" 0 "Normal";
VAL_ 1090 TBOX_Re_DTCData 3 "the data upload is NG" 2 "the data upload is OK" 1 "Request" 0 "No Request";
VAL_ 1090 Remote_AutoReq 1 "ON" 0 "OFF";
VAL_ 1090 Remote_MidAutoReq 1 "ON" 0 "OFF";
VAL_ 1174 TimeSyncFromBS_Month 15 "Not Used" 14 "Not Used" 13 "Not Used" 0 "invalid";
VAL_ 1249 ReserveChargeOn_Month 15 "Not Used" 14 "Not Used" 13 "Not Used" 0 "invalid";
VAL_ 1249 ReserveChargeOFF_Month 15 "Not Used" 14 "Not Used" 13 "Not Used" 0 "invalid";
VAL_ 1249 Charge_Percent_Set 101 "Failed" 100 "Max" 0 "Min";
VAL_ 1280 NM_FUSION_ERROR_State 8 "BUS OFF_L2" 4 "BUS OFF_L1" 2 "ERROR PASSIVE" 1 "ERROR ACTIVE" 0 "Inactive";
VAL_ 1280 NM_FUSION_Rpt_Msg_Req 1 "Repeat Message State requested" 0 "Repeat Message State not requested";
VAL_ 1280 NM_FUSION_CSB 1 "Start of synchronized shutdown is requested by main coordinator" 0 "Start of synchronized shutdown is not requested by main coordinator";
VAL_ 1280 NM_FUSION_Active_WU 1 "Node has woken up the network (active Wakeup)" 0 "Node has not woken up the network (passive wakeup)";
VAL_ 1280 NM_FUSION_PNI 1 "NM PDU contains Partial Network request information" 0 "NM PDU contains no Partial Network request information";
VAL_ 593 DKC_Remote_PW 16 "App 4Door AutoDown" 15 "App 4Door AutoUP" 14 "Stop" 13 "App RR ManualDown" 12 "App RL ManualDown" 11 "App FR ManualDown" 10 "App FL ManualDown" 9 "App 4Door ManualD" 8 "App RRAutoDown" 7 "App RRAutoUP" 6 "App RLAutoDown" 5 "App RLAutoUP" 4 "App FRAutoDown" 3 "App FRAutoUP" 2 "App FLAutoDown" 1 "App FLAutoUP" 0 "release";
VAL_ 593 P_KeyMiss 1 "Key Miss" 0 "Default";
VAL_ 593 P_DKey_Area_PTG 3 "UnsedandReserved" 2 "Out of SPTG Zone" 1 "In to SPTG Zone" 0 "Unavaliable";
VAL_ 593 P_KeyMode 6 "Invalid" 5 "NFC" 4 "PHONE (BLE)" 3 "PHONE (UWB)" 2 "UID (BLE)" 1 "UID (UWB)" 0 "Default";
VAL_ 593 P_Dkey_Show_IVI 7 "invalid" 6 "IVI PHONE Green" 5 "IVI PHONE Red" 4 "IVI UID Green" 3 "IVI UID Red" 2 "IVI NFC Card Green" 1 "IVI NFC Card Red" 0 "Default";
VAL_ 593 P_CommandToPTG 5 "invalid" 4 "PTG-legal Key in Indoor and Outdoor(ID identical)" 3 "PTG-legal Key in Indoor and Outdoor(ID different)" 2 "PTG-legal Key in Indoor" 1 "PTG-legal Key in Outdoor" 0 "Default";
VAL_ 593 P_DKey_Area_PS 3 "UnsedandReserved" 2 "Out of PS Zone" 1 "In to PS Zone" 0 "Unavaliable";
VAL_ 593 P_DKey_Area_LockUnlock 3 "UnusedandReserved" 2 "In to Unlock Zone" 1 "In to Lock Zone" 0 "Unavailable";
VAL_ 593 P_DKey_Welcome 3 "UnsedandReserved" 2 "Out the welcome zone" 1 "In the welcom zone" 0 "Unavaliable";
VAL_ 593 P_CommandToBCM 8 "Invalid" 7 "Forced to lift anti-theft" 6 "HandleTailgate Open/Close" 5 "Failed to Lock Tailgate" 4 "Car Search" 3 "Remote Tailgate Open/Close" 2 "Unlock" 1 "Lock" 0 "Default";
VAL_ 593 DKC_Re_VehData 1 "Request" 0 "No Request";
VAL_ 593 P_UID_LowPower 1 "On" 0 "Off";
VAL_ 342 LF_RawWhlSpeed_V 1 "Invalid" 0 "Valid";
VAL_ 342 LF_WhlRotDir 3 "Standstill" 2 "Backward" 1 "Forward" 0 "Unknown/Standby";
VAL_ 342 LF_PulseCount_V 1 "Invalid" 0 "Valid";
VAL_ 342 RF_RawWhlSpeed_V 1 "Invalid" 0 "Valid";
VAL_ 342 RF_WhlRotDir 3 "Standstill" 2 "Backward" 1 "Forward" 0 "Unknown/Standby";
VAL_ 342 RF_PulseCount_V 1 "Invalid" 0 "Valid";
VAL_ 343 LR_RawWhlSpeed_V 1 "Invalid" 0 "Valid";
VAL_ 343 LR_WhlRotDir 3 "Standstill" 2 "Backward" 1 "Forward" 0 "Unknown/Standby";
VAL_ 343 LR_PulseCount_V 1 "Invalid" 0 "Valid";
VAL_ 343 RR_RawWhlSpeed_V 1 "Invalid" 0 "Valid";
VAL_ 343 RR_WhlRotDir 3 "Standstill" 2 "Backward" 1 "Forward" 0 "Unknown/Standby";
VAL_ 343 RR_PulseCount_V 1 "Invalid" 0 "Valid";
VAL_ 602 ParkBrake 1 "On" 0 "Off";
VAL_ 602 Charge 1 "Disable (LED ON)" 0 "Enable (LED OFF)";
VAL_ 602 LEDlitWarnReq 1 "Warning request" 0 "No warning request";
VAL_ 602 Spd_Crl_Sta 1 "ON" 0 "OFF";
VAL_ 602 Spd_Crl_Mode 5 "invalid" 4 "ISA" 3 "LIM" 2 "CC" 1 "ACC" 0 "OFF";
VAL_ 1168 DRAmbLightBrightnessSet 101 "~0x7F undefined" 100 "MAX" 0 "min";
VAL_ 1168 AmbLightUserSet 7 "undiefined" 6 "User6" 5 "User5" 4 "User4" 3 "User3" 2 "User2" 1 "User1" 0 "No Request";
VAL_ 1168 IPAmbLightBrightnessSet 101 "~0x7F undefined" 100 "MAX" 0 "min";
VAL_ 1168 Sched_OTA_wake 1 "wake" 0 "standby";
VAL_ 1168 AmbLightColorSet 63 "Red(255,0,0)" 62 "IndianRed(205,92,92)" 61 "LightCoral(240,128,128)" 60 "Tomato(255,99,71)" 59 "OrangeRed(255,69,0)" 58 "Coral(255,127,80)" 57 "LightSalmon(255,160,122)" 56 "DarkOrange(255,140,0)" 55 "Bisque(255,228,196)" 54 "NavajoWhite(255,222,173)" 53 "BlanchedAlmond(255,235,205)" 52 "Gold(255,215,0)" 51 "LemonChiffon(255,250,205)" 50 "Yellow(255,255,0)" 49 "LightYellow(255,255,224)" 48 "Ivory(255,255,240)" 47 "LightGoldenrodYellow(250,250,210)" 46 "Beige(245,245,220)" 45 "GreenYellow(73,255,47)" 44 "Chartreuse(127,255,0)" 43 "Lime(0,255,0)" 42 "LimeGreen(50,205,50)" 41 "PaleGreen(152,251,152)" 40 "LightGreen(144,238,144)" 39 "SeaGreen(46,139,87)" 38 "SpringGreen(60,179,113)" 37 "MediumSpringGreen(0,255,127)" 36 "MediumAquamarine(0,250,154)" 35 "Auqamarin(127,255,170)" 34 "MediumTurquoise(72,209,204)" 33 "DarkCyan(0,139,139)" 32 "DarkTurquoise(0,206,209)" 31 "Cyan(0,255,255)" 30 "PaleTurquoise(175,238,238)" 29 "DeepSkyBlue(0,191,255)" 28 "SkyBlue(135,206,235)" 27 "LightSkyBlue(135,206,250)" 26 "DoderBlue(30,144,255)" 25 "CornflowerBlue(100,149,237)" 24 "RoyalBlue(65,105,225)" 23 "Navy(0,0,128)" 22 "DarkBlue(0,0,139)" 21 "MidnightBlue(25,25,112)" 20 "MediumBlue(0,0,205)" 19 "Blue(0,0,255)" 18 "DarkSlateBlue(72,61,139)" 17 "SlateBlue(106,90,205)" 16 "MediumSlateBlue(123,104,238)" 15 "MediumPurple(147,112,219)" 14 "BlueViolet(138,43,226)" 13 "Indigo(75,0,130)" 12 "DarkOrchid(153,50,204)" 11 "DarkVoilet(148,0,211)" 10 "MediumOrchid(186,85,211)" 9 "DarkMagenta(139,0,139)" 8 "Magenta(255,0,255)" 7 "Violet(238,130,238)" 6 "Orchid(218,112,214)" 5 "MediumVioletRed(199,21,133)" 4 "DeepPink(255,20,147)" 3 "HotPink(255,105,180)" 2 "PaleVioletRed(219,112,147)" 1 "Crimson(220,20,60)" 0 "LightPink(255,182,193)";
VAL_ 1168 Upd_Countdown_Cancel 1 "Press" 0 "Release";
VAL_ 1168 Upd_Countdown_Skip 1 "Press" 0 "Release";
VAL_ 1168 LINKtoDrive 1 "ON" 0 "OFF";
VAL_ 1168 OTA_CompNTFY_Pres 1 "Presented" 0 "Not presented";
VAL_ 1168 OTA_CancelDL_Req 1 "Press" 0 "Release";
VAL_ 1168 IVI_OTA_Upd_Sta 3 "undefined" 2 "Completed" 1 "Uncompleted" 0 "No Update";
VAL_ 1168 OTA_UpdStart_Req 1 "Press" 0 "Release";
VAL_ 1168 OTA_SuspendDL_Req 1 "Press" 0 "Release";
VAL_ 1168 OTA_DL_Req 1 "Press" 0 "Release";
VAL_ 1168 FCP_FrEvt_BtnSyncReq 1 "Press" 0 "Release";
VAL_ 1168 FCP_MidEvt_BtnAutoReq 1 "Press" 0 "Release";
VAL_ 1168 FCP_FrEvt_BtnAutoReq 1 "Press" 0 "Release";
VAL_ 1168 FCP_FrEvt_BtnACReq 1 "Press" 0 "Release";
VAL_ 1168 FCP_FrEvt_BtnACMaxReq 1 "Press" 0 "Release";
VAL_ 1168 VehACModReq 7 "Invalid" 6 "Signal not available" 5 "Reserved" 2 "Reserved" 1 "Economy mode" 0 "Standard";
VAL_ 1168 PW_CONTINUE_USE 1 "Press" 0 "Release";
VAL_ 1168 PW_CLOSE_IMD 1 "Press" 0 "Release";
VAL_ 1168 SmartEco_Mode_SW 1 "ON" 0 "OFF";
VAL_ 1168 BrkAbn_GoReady_SW 1 "Press" 0 "Release";
VAL_ 1168 OpenDrOpenWdo_SW 1 "Press" 0 "Release";
VAL_ 1168 IVI_Lock_SoundSW_Sta 1 "ON" 0 "OFF";
VAL_ 1173 AVM_parking_cancel 2 "invalid" 1 "press" 0 "release";
VAL_ 1173 AVM_parking_excute 3 "remote request" 2 "invalid" 1 "press" 0 "release";
VAL_ 1173 AVM_OFF_Rec_Butt 1 "ON" 0 "OFF";
VAL_ 1173 IVI_AGSCloseSW 3 "Undefined" 2 "Invalid" 1 "Press (>0.5s)" 0 "Release";
VAL_ 1173 IVI_LVChrgFuncSW 3 "Undefined" 2 "Invalid" 1 "Press (>0.5s)" 0 "Release";
VAL_ 1173 IVI_PwrLockSW 3 "Undefined" 2 "Invalid" 1 "Press (>0.5s)" 0 "Release";
VAL_ 1173 IVI_CoastDwSW 3 "Undefined" 2 "Invalid" 1 "Press (>0.5s)" 0 "Release";
VAL_ 1173 IVI_ActvDmpDisabSW 3 "Undefined" 2 "Invalid" 1 "Press (>0.5s)" 0 "Release";
VAL_ 1173 Roll_Mode_SW_Cmd 3 "Invaild" 2 "Undefined" 1 "Press" 0 "Release";
VAL_ 1173 TCS_SW_Cmd 3 "Invaild" 2 "Undefined" 1 "Press" 0 "Release";
VAL_ 1173 SLIF_BUTT 2 "Invalid" 1 "Pressed" 0 "No request";
VAL_ 1173 Roll_Eng_Mode 1 "on" 0 "off";
VAL_ 1173 SOC_Limit_Set 31 "invalid" 26 "~0x1E undefined" 0 "~0x19 50%~100%";
VAL_ 1173 CDL_Lock_Butt 1 "Press" 0 "Release";
VAL_ 1173 CDL_Unlock_Butt 1 "Press" 0 "Release";
VAL_ 1173 SOC_ADJ_BUTT 1 "Press" 0 "Release";
VAL_ 1173 IVI_ISA_OffsetSpd 15 "Invalid" 14 "reserve" 13 "reserve" 12 "reserve" 11 "5 mph" 10 "0 mph" 9 "-5 mph" 8 "reserve" 7 "reserve" 6 "reserve" 5 "+10 km/h" 4 "+5 km/h" 3 "0 km/h" 2 "-5 km/h" 1 "-10 km/h" 0 "Off";
VAL_ 1173 RoomLampMode 1 "OFF Mode" 0 "DoorMode";
VAL_ 1173 NAVI_SpeedLimit 31 "80mph" 30 "75mph" 29 "70mph" 28 "65mph" 27 "60mph" 26 "55mph" 25 "50mph" 24 "45mph" 23 "40mph" 22 "35mph" 21 "30mph" 20 "25mph" 19 "20mph" 18 "15mph" 17 "10mph" 16 "160 km/h" 15 "150 km/h" 14 "140 km/h" 13 "130 km/h" 12 "120 km/h" 11 "110 km/h" 10 "100 km/h" 9 "90 km/h" 8 "80 km/h" 7 "70 km/h" 6 "60 km/h" 5 "50 km/h" 4 "40 km/h" 3 "30 km/h" 2 "20 km/h" 1 "10 km/h" 0 "No request";
VAL_ 1173 NAVI_RoadClass 7 "undefined" 6 "undefined" 5 "Freeway" 4 "School" 3 "Street" 2 "Interurban" 1 "City" 0 "NA";
VAL_ 1173 NAVI_LinkClass 15 "undefined" 14 "undefined" 13 "undefined" 12 "undefined" 11 "undefined" 10 "undefined" 9 "undefined" 8 "etc" 7 "shoulder" 6 "ramp" 5 "Freeway" 4 "Bus lane" 3 "Roundabout" 2 "City Lv2" 1 "City Lv1" 0 "NA";
VAL_ 1173 NAVI_ForwardLinkLevel 15 "undefined" 14 "undefined" 13 "undefined" 12 "undefined" 11 "undefined" 10 "undefined" 9 "undefined" 8 "etc" 7 "shoulder" 6 "ramp" 5 "Freeway" 4 "Bus lane" 3 "Roundabout" 2 "City Lv2" 1 "City Lv1" 0 "NA";
VAL_ 1173 SenstivityPosition 15 "not used" 14 "not used" 13 "not used" 12 "not used" 11 "not used" 10 "not used" 9 "not used" 8 "not used" 7 "not used" 6 "not used" 5 "not used" 4 "senstivity level-4" 3 "senstivity level-3" 2 "senstivity level-2" 1 "senstivity level-1" 0 "not used";
VAL_ 1173 AVM_Parking_mode 8 "Forced to end" 7 "emergency stop" 6 "Left parking out" 5 "Right parking out" 4 "Left Perpendicular parking" 3 "Right Perpendicular parking" 2 "Left Parallel parking" 1 "Right Parallel parking" 0 "No message";
VAL_ 1173 Hood_Latch_SW 2 "invalid" 1 "Press" 0 "No Request";
VAL_ 1173 RCTA_BUTT 2 "Invalid" 1 "Pressed" 0 "No request";
VAL_ 1173 IVI_Pwroff_req 1 "Request" 0 "No request";
VAL_ 1173 IVI_Trigger_req 1 "Request" 0 "No request";
VAL_ 1173 AVM_Err_STA 1 "Error" 0 "No Error";
VAL_ 1173 IVI_Mute_Sta 1 "Mute On" 0 "Mute Off";
VAL_ 1173 IVI_PTG_USSta_SW 1 "Off" 0 "On";
VAL_ 1173 IVI_WI_MAIN_SW 1 "ON" 0 "OFF";
VAL_ 1173 IVI_RR_Def_Req 1 "Press" 0 "Release";
VAL_ 1173 IVI_Night_Mode_Sta 1 "ON" 0 "OFF";
VAL_ 1173 IVI_Status 1 "Ready" 0 "Not ready";
VAL_ 1173 LVDAMute_BUTT 2 "Invalid" 1 "Pressed" 0 "No request";
VAL_ 1173 CAAS_Sw 2 "Invalid" 1 "Press" 0 "Release";
VAL_ 1173 DSEAT_entryfun_set 1 "ON" 0 "OFF";
VAL_ 1173 DSEAT_anti_set 1 "ON" 0 "OFF";
VAL_ 1173 TPMS_Res_Butt 1 "Press" 0 "Release";
VAL_ 1173 FollowMeSW 1 "Press" 0 "Release";
VAL_ 1173 SetUnlockSingle 1 "Press" 0 "Release";
VAL_ 1173 IVI_PTG_Mode_SW 2 "Invalid" 1 "Press" 0 "No Request";
VAL_ 1173 IVI_PTG_Sta_SW 2 "Invalid" 1 "Press" 0 "Release";
VAL_ 1173 SLG_Sw 2 "invalid" 1 "ON" 0 "OFF";
VAL_ 1173 FS_Off_Sw 2 "invalid" 1 "ON" 0 "OFF";
VAL_ 1173 PSEAT_vent_req 4 "OFF" 3 "Vent3" 2 "Vent2" 1 "Vent1" 0 "No request";
VAL_ 1173 FFogLampSW 1 "ON" 0 "OFF";
VAL_ 1173 DSEAT_vent_req 7 "Not used" 6 "Not used" 5 "Not used" 4 "OFF" 3 "High" 2 "Middle" 1 "Low" 0 "No request";
VAL_ 1173 RFogLampSW 1 "ON" 0 "OFF";
VAL_ 1173 MFRD_N_Bright_Req 127 "invalid" 100 "Max" 0 "Min";
VAL_ 1173 User_p_download 1 "download" 0 "No Request";
VAL_ 1173 HeadLampSW 3 "OFF" 2 "Low beam" 1 "Postion lamp" 0 "AUTO";
VAL_ 1173 NAVI_State 3 "NAVI error" 2 "NAVI good reception" 1 "NAVI no satellite" 0 "No NAVI";
VAL_ 1173 Wifi_Sta_IVI_TBOX 9 "password error" 8 "Connection error" 6 "Internal Error" 5 "no signal" 4 "4 bar" 3 "3 bar" 2 "2 bar" 1 "1 bar" 0 "Invalid";
VAL_ 1173 NAVI_Cam_Dist_info 255 "Invalid" 150 "MAX" 0 "Min";
VAL_ 1173 OFF_AC_MODE 7 "Invalid" 3 "CAMP" 2 "Pet" 1 "ON" 0 "OFF";
VAL_ 1173 IVI_PW_Mode_Req 3 "No request" 2 "ECO" 1 "Sport" 0 "Normal";
VAL_ 1173 User_p_upload 1 "upload" 0 "No Request";
VAL_ 1173 CameraWrn 1 "Warnning enable" 0 "Off";
VAL_ 1173 Wifi_Reset 1 "reset VIG Wifi" 0 "No Request";
VAL_ 1173 IVI_Screen 63 "invalid" 62 "undefined" 29 "undefined" 28 "APS-all" 27 "AVM-all" 26 "Phone:incoming call popup:upper" 25 "Phone:dialer-upper" 24 "Phone:call history-upper" 23 "Phone:contacts-upper" 22 "System setting-Display-all" 21 "System setting-Sound-all" 20 "System setting-Cellular-all" 19 "System setting-Bluetooth-all" 18 "System setting-WiFi-all" 17 "System setting-account-all" 16 "Setting-About-all" 15 "Setting-Software-all" 14 "Setting-Service-all" 13 "Setting-Security-all" 12 "Setting-ADAS-all" 11 "Setting-Doors-all" 10 "Setting-Charging-all" 9 "Setting-Energy-all" 8 "Setting-Spotlight-all" 7 "Navi page-upper" 6 "3rd party app page-upper" 5 "Android auto-upper" 4 "Car play-upper" 3 "All app page-upper" 2 "DropDown menu-upper" 1 "DropDown menu-all" 0 "Home-up";
VAL_ 1173 TurnSwTimeSet 3 "Undefiend" 2 "7 times" 1 "5 times" 0 "3 times";
VAL_ 1173 Pressure_unit 1 "kg/m2" 0 "PSI";
VAL_ 1173 Time_system 1 "24h" 0 "12h";
VAL_ 1173 NAVI_Speed_Limit_A 3 "invalid" 2 "Not Used" 1 "Applicable" 0 "Not Applicable";
VAL_ 1173 Temperature_unit 1 "Fahrenheit" 0 "Celsius";
VAL_ 1173 Distance_unit 1 "mile" 0 "kilometer";
VAL_ 1173 ESC_SW_Cmd 3 "Invaild" 2 "Undefined" 1 "Press" 0 "Release";
VAL_ 1173 IVI_Panel_Act 1 "PRESS" 0 "RELEASE";
VAL_ 1173 sigHvacRearReq 1 "Press" 0 "Release";
VAL_ 1173 FCWMute_BUTT 2 "Invalid" 1 "Pressed" 0 "No request";
VAL_ 1173 LKA_BUTT 2 "Invalid" 1 "Pressed" 0 "No request";
VAL_ 1173 ODAMute_BUTT 2 "Invalid" 1 "Pressed" 0 "No request";
VAL_ 1173 LDWMute_BUTT 2 "Invalid" 1 "Pressed" 0 "No request";
VAL_ 1173 BSDMute_BUTT 2 "Invalid" 1 "Pressed" 0 "No request";
VAL_ 1173 sigWindDirZon3Req 7 "NOT Set / Reserved" 6 "All open" 5 "Face + Screen" 4 "DEFOG" 3 "Foot + Screen" 2 "Foot" 1 "Bilevel" 0 "FACE";
VAL_ 1173 sigAirIntenZon3Req 15 "Invalid" 14 "Reserved" 11 "Reserved" 10 "NOT set" 9 "Level 8" 8 "Level 7" 7 "Level 6" 6 "Level 5" 5 "Level 4" 4 "Level 3" 3 "Level 2" 2 "Level 1" 1 "OFF" 0 "NO display / No request";
VAL_ 1173 sigAirIntenZon1Req 15 "Invalid" 14 "Reserved" 11 "Reserved" 10 "NOT set" 9 "Level 8" 8 "Level 7" 7 "Level 6" 6 "Level 5" 5 "Level 4" 4 "Level 3" 3 "Level 2" 2 "Level 1" 1 "OFF" 0 "NO display / No request";
VAL_ 1173 AEB_BUTT 2 "Invalid" 1 "Pressed" 0 "No request";
VAL_ 1173 sigRecircReq 1 "Press" 0 "Release";
VAL_ 1173 sigHvacReq 1 "ON" 0 "Off / Auto";
VAL_ 1173 sigHvacFrontReq 1 "Press" 0 "Release";
VAL_ 1173 sigDfrstReq 1 "press" 0 "relesase";
VAL_ 1173 L_Drv_ControlCommand 127 "No Request" 100 "Max" 0 "Min";
VAL_ 1173 TPMS_Cali_Butt 1 "press" 0 "relesase";
VAL_ 1173 L_Pas_ControlCommand 127 "No Request" 100 "Max" 0 "Min";
VAL_ 1173 IVI_Unlock_Chg_req 1 "press" 0 "relesase";
VAL_ 1173 L_RLD_ControlCommand 127 "No Request" 100 "Max" 0 "Min";
VAL_ 1173 IVI_Stop_Chg_req 1 "press" 0 "relesase";
VAL_ 1173 L_RRD_ControlCommand 127 "No Request" 100 "Max" 0 "Min";
VAL_ 1173 IVI_Start_Chg_req 1 "press" 0 "relesase";
VAL_ 1173 METER_Malfunc_Sta 2 "Warning flash" 1 "Warning" 0 "Normal";
VAL_ 1173 sigFootReq 1 "press" 0 "relesase";
VAL_ 1173 sigFaceReq 1 "press" 0 "relesase";
VAL_ 1173 Sched_Chg_Start 1 "press" 0 "release";
VAL_ 1173 Sched_Chg_wake 1 "wake" 0 "standby";
VAL_ 1173 Sched_Chg_butt 1 "on" 0 "off";
VAL_ 1173 Sched_Chg_Stop 1 "press" 0 "release";
VAL_ 1173 Sched_Chg_limit 31 "invalid" 26 "~0x1E undefined" 0 "~0x19 50%~100%";
VAL_ 1173 Walkaway_Lock_SW 1 "ON" 0 "OFF";
VAL_ 1173 Approach_Unlock_SW 1 "ON" 0 "OFF";
VAL_ 1173 FalseNPrevent_SW 1 "ON" 0 "OFF";
VAL_ 1173 IVI_CreepSW_Req 1 "Press" 0 "Release";
VAL_ 1173 IVI_PTG_Open_Height 7 "Invalid" 6 "Invalid" 5 "Invalid" 4 "Set by User" 3 "Lv3(80%)" 2 "Lv2(60%)" 1 "Lv1(40%)" 0 "Full Open";
VAL_ 1173 IVI_Req_V2L 1 "Request" 0 "Not request";
VAL_ 1173 Perd_V2L 15 "8hr" 14 "7.5hr" 13 "7hr" 12 "6.5hr" 11 "6hr" 10 "5.5hr" 9 "5hr" 8 "4.5hr" 7 "4hr" 6 "3.5hr" 5 "3hr" 4 "2.5hr" 3 "2hr" 2 "1.5hr" 1 "1hr" 0 "0.5hr";
VAL_ 1173 SOC_V2LLimit 15 "invalid" 14 "undefined" 13 "undefined" 12 "80%" 11 "75%" 10 "70%" 9 "65%" 8 "60%" 7 "55%" 6 "50%" 5 "45%" 4 "40%" 3 "35%" 2 "30%" 1 "25%" 0 "20%";
VAL_ 1179 A2B_Node_sta 1 "Fail" 0 "Normal";
VAL_ 1179 Re_Radio_Sta 1 "ON" 0 "OFF";
VAL_ 1179 Sched_Chg_Day_Set 1 "Weekday" 0 "Everyday";
VAL_ 1183 IVI_Located_STA 3 "Not Used" 2 "3D fix" 1 "2D fix" 0 "No fix";
VAL_ 1183 IVI_Time_Month 15 "Not Used" 14 "Not Used" 13 "Not Used" 0 "invalid";
VAL_ 1282 NM_Telltale_ERROR_State 8 "BUS OFF_L2" 4 "BUS OFF_L1" 2 "ERROR PASSIVE" 1 "ERROR ACTIVE" 0 "Inactive";
VAL_ 1282 NM_Telltale_Rpt_Msg_Req 1 "Repeat Message State requested" 0 "Repeat Message State not requested";
VAL_ 1282 NM_Telltale_CSB 1 "Start of synchronized shutdown is requested by main coordinator" 0 "Start of synchronized shutdown is not requested by main coordinator";
VAL_ 1282 NM_Telltale_Active_WU 1 "Node has woken up the network (active Wakeup)" 0 "Node has not woken up the network (passive wakeup)";
VAL_ 1282 NM_Telltale_PNI 1 "NM PDU contains Partial Network request information" 0 "NM PDU contains no Partial Network request information";
VAL_ 1312 NM_IVI_ERROR_State 8 "BUS OFF_L2" 4 "BUS OFF_L1" 2 "ERROR PASSIVE" 1 "ERROR ACTIVE" 0 "Inactive";
VAL_ 1312 NM_IVI_Rpt_Msg_Req 1 "Repeat Message State requested" 0 "Repeat Message State not requested";
VAL_ 1312 NM_IVI_CSB 1 "Start of synchronized shutdown is requested by main coordinator" 0 "Start of synchronized shutdown is not requested by main coordinator";
VAL_ 1312 NM_IVI_Active_WU 1 "Node has woken up the network (active Wakeup)" 0 "Node has not woken up the network (passive wakeup)";
VAL_ 1312 NM_IVI_PNI 1 "NM PDU contains Partial Network request information" 0 "NM PDU contains no Partial Network request information";
VAL_ 1330 NM_HMI_ERROR_State 8 "BUS OFF_L2" 4 "BUS OFF_L1" 2 "ERROR PASSIVE" 1 "ERROR ACTIVE" 0 "Inactive";
VAL_ 1330 NM_HMI_Rpt_Msg_Req 1 "Repeat Message State requested" 0 "Repeat Message State not requested";
VAL_ 1330 NM_HMI_CSB 1 "Start of synchronized shutdown is requested by main coordinator" 0 "Start of synchronized shutdown is not requested by main coordinator";
VAL_ 1330 NM_HMI_Active_WU 1 "Node has woken up the network (active Wakeup)" 0 "Node has not woken up the network (passive wakeup)";
VAL_ 1330 NM_HMI_PNI 1 "NM PDU contains Partial Network request information" 0 "NM PDU contains no Partial Network request information";
VAL_ 796 BMSReqTapPosHSC6 7 "7 Tap" 6 "6 Tap" 5 "5 Tap" 4 "4 Tap" 3 "3 Tap" 2 "2 Tap" 1 "1 Tap" 0 "0 Tap";
VAL_ 796 BMSReqMdHSC6 3 "PWM Control" 2 "Tap Position Control" 1 "Power Control" 0 "No Request";
VAL_ 796 BMSEnbPTCHSC6 1 "On" 0 "Off";
VAL_ 385 Shifter_Handle_Cmd 255 "invalid" 7 "Reverse" 5 "Drive" 4 "Neutral" 2 "Park" 0 "Default";
VAL_ 385 Shifter_Fail_sta 3 "shifter failure" 2 "Hall failure" 1 "P button failure" 0 "normal";
VAL_ 496 SysPwrSta 10 "ON_HVChrg" 9 "OFF-C_LVChrg" 8 "HVChrgPre-action" 7 "Power_down" 6 "Power_up" 5 "READY" 4 "ON_NoChrg" 3 "STANDBY" 2 "OFF-A" 1 "OFF-C_HVChrg" 0 "OFF";
VAL_ 496 PowerUpState 9 "HVSysChk" 8 "DriverSafetyChk" 7 "SafetyChk" 6 "PowerUpFail" 5 "Completed" 4 "MCU_Enable" 3 "OBC_Enable" 2 "DCDC_Enable" 1 "BattPACK" 0 "Initialize";
VAL_ 496 PowerUpFault 8 "DCDC_SetVoltFail" 7 "DriverSafetyChkFail" 6 "SafetyChkFail" 5 "MCU_EnableFail" 4 "OBC_EnableFail" 3 "DCDC_EnableFail" 2 "BattUpFail" 1 "PreChargeChkFail" 0 "No Fault";
VAL_ 496 PowerDownState 7 "MCU_Disable" 6 "MLvSafetyChkPowerDown" 5 "Completed" 4 "OBC_Disable" 3 "MCU_DisCharge" 2 "BattPACK" 1 "DCDC Disable" 0 "Initialize";
VAL_ 496 PowerDownFault 7 "SafetyChkMLvFail" 6 "MCU_Disable" 5 "MCU_Discharge" 4 "BattPDFail" 3 "OBC_Disable" 2 "DCDC_Stop" 1 "DCDC_Disable" 0 "No Fault";
VAL_ 496 PwrStaSelect 3 "Go OFF-A" 2 "Go OFF-C" 1 "Go ON" 0 "No request";
VAL_ 496 PwrStaConstraint 4 "Keep HV active for time" 3 "Keep power state ON for time" 2 "Keep HV active" 1 "Power state ON" 0 "No request";
VAL_ 496 TCountSta 2 "Counting finish" 1 "Timmer counting" 0 "No counting";
VAL_ 496 PwrUpReq 2 "System request  power up" 1 "User request  power up" 0 "No request";
VAL_ 496 PwrDownReq 2 "System request  power down" 1 "User request  power down" 0 "No request";
VAL_ 496 Rr_TqSource 9 "ForceIdle" 8 "APS" 7 "MSA" 6 "ADAS" 5 "CC" 4 "TCS" 3 "RollABS" 2 "ABS" 1 "Internal" 0 "Invalid";
VAL_ 496 Fr_TqSource 9 "ForceIdle" 8 "APS" 7 "MSA" 6 "ADAS" 5 "CC" 4 "TCS" 3 "RollABS" 2 "ABS" 1 "Internal" 0 "Invalid";
VAL_ 496 LVBattVoltSta 3 "Invalid" 2 "Reserved" 1 "Failure" 0 "Normal";
VAL_ 496 HVTHCMSysAvail 3 "Invalid" 2 "Reserved" 1 "Failure" 0 "Normal";
VAL_ 496 VCUBrkSWSta 2 "Invalid" 1 "On" 0 "OFF";
VAL_ 496 VCUFLDoorSta 1 "Fail" 0 "Normal";
VAL_ 496 VCUFRDoorSta 1 "Fail" 0 "Normal";
VAL_ 496 VCURLDoorSta 1 "Fail" 0 "Normal";
VAL_ 496 VCURRDoorSta 1 "Fail" 0 "Normal";
VAL_ 496 SysAllowReadySta 1 "Not allow ready" 0 "Normal";
VAL_ 496 HVRlyOpFail 1 "Fail" 0 "Normal";
VAL_ 496 MCUActDisFail 1 "Fail" 0 "Normal";
VAL_ 496 PwrStaONTOIVIPopReq 1 "On" 0 "OFF";
VAL_ 496 PwrStaTOSta 1 "Timeout" 0 "Normal";
VAL_ 496 SchedChgTOSta 1 "Timeout" 0 "Normal";
VAL_ 496 SilentChkAllowSleep 1 "Allow sleep" 0 "Not allow sleep";
VAL_ 496 LVSilentChrgSta 3 "Fault" 2 "Charging completed" 1 "Charging" 0 "No action";
VAL_ 496 LVSilentChrgLv 3 "Level 3" 2 "Level 2" 1 "Level 1" 0 "Invalid";
VAL_ 496 LVSilentChrgReq 1 "Request LV silent charging" 0 "No request,";
VAL_ 496 TimerAllowSleep 1 "Allow sleep" 0 "Not allow sleep";
VAL_ 496 PMMAllowECUSleep 1 "Allow sleep" 0 "Not allow sleep";
VAL_ 496 EVCCAplusPwrUpReq 1 "Request" 0 "No Request";
VAL_ 496 VCUHoodSWSta 1 "Fail" 0 "Normal";
VAL_ 496 VCUTailgateSWSta 1 "Fail" 0 "Normal";
VAL_ 340 AccPedal_Override 1 "Acceleration Pedal Override" 0 "No Override";
VAL_ 340 ACC_CtrlAvail 1 "Available" 0 "Unavailable";
